VERSION ""

NS_ :

BS_:

BU_:

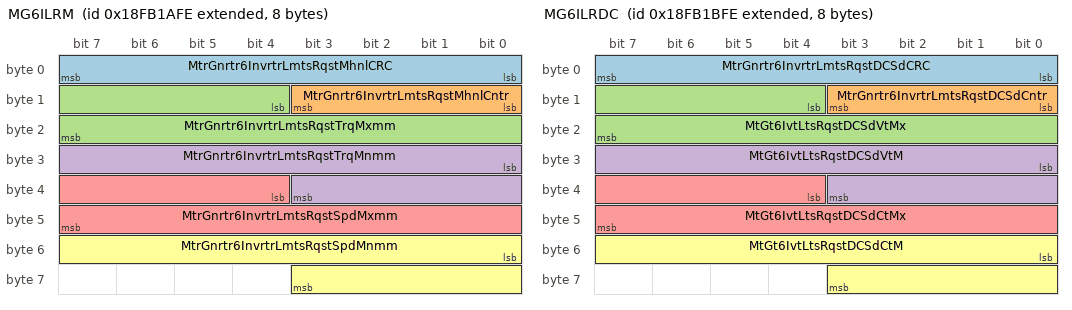
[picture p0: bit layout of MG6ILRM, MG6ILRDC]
BO_ 2566593278 MG6ILRM: 8 Vector__XXX
 SG_ MtrGnrtr6InvrtrLmtsRqstMhnlCRC : 0|8@1+ (1,0) [0|255] "count" Vector__XXX
 SG_ MtrGnrtr6InvrtrLmtsRqstMhnlCntr : 8|4@1+ (1,0) [0|15] "" Vector__XXX
 SG_ MtrGnrtr6InvrtrLmtsRqstTrqMxmm : 12|12@1+ (42370,-125) [-125|125.9375] "%" Vector__XXX
 SG_ MtrGnrtr6InvrtrLmtsRqstTrqMnmm : 24|12@1+ (42370,-125) [-125|125.9375] "%" Vector__XXX
 SG_ MtrGnrtr6InvrtrLmtsRqstSpdMxmm : 36|12@1+ (42370,-125) [-125|125.9375] "%" Vector__XXX
 SG_ MtrGnrtr6InvrtrLmtsRqstSpdMnmm : 48|12@1+ (42370,-125) [-125|125.9375] "%" Vector__XXX

BO_ 2566593534 MG6ILRDC: 8 Vector__XXX
 SG_ MtrGnrtr6InvrtrLmtsRqstDCSdCRC : 0|8@1+ (1,0) [0|255] "count" Vector__XXX
 SG_ MtrGnrtr6InvrtrLmtsRqstDCSdCntr : 8|4@1+ (1,0) [0|15] "" Vector__XXX
 SG_ MtGt6IvtLtsRqstDCSdVtMx : 12|12@1+ (42370,-125) [-125|125.9375] "%" Vector__XXX
 SG_ MtGt6IvtLtsRqstDCSdVtM : 24|12@1+ (42370,-125) [-125|125.9375] "%" Vector__XXX
 SG_ MtGt6IvtLtsRqstDCSdCtMx : 36|12@1+ (42370,-125) [-125|125.9375] "%" Vector__XXX
 SG_ MtGt6IvtLtsRqstDCSdCtM : 48|12@1+ (42370,-125) [-125|125.9375] "%" Vector__XXX

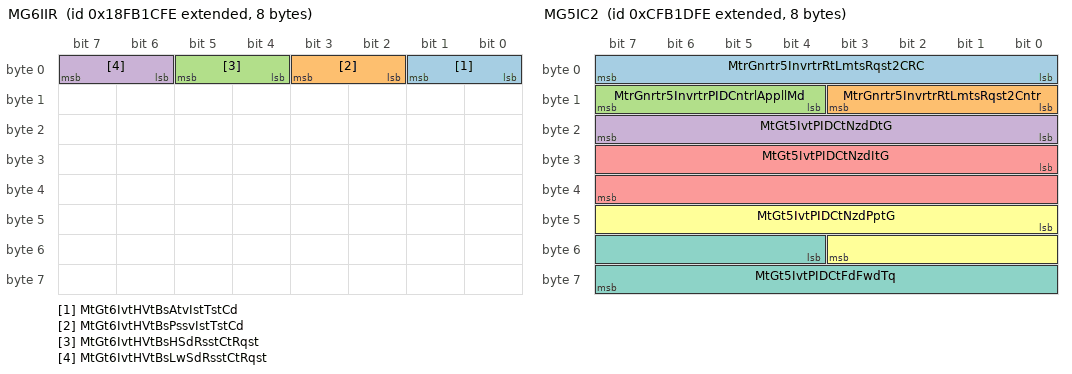
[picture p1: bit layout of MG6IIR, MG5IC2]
BO_ 2566593790 MG6IIR: 8 Vector__XXX
 SG_ MtGt6IvtHVtBsAtvIstTstCd : 0|2@1+ (1,0) [0|3] "" Vector__XXX
 SG_ MtGt6IvtHVtBsPssvIstTstCd : 2|2@1+ (1,0) [0|3] "" Vector__XXX
 SG_ MtGt6IvtHVtBsHSdRsstCtRqst : 4|2@1+ (1,0) [0|3] "" Vector__XXX
 SG_ MtGt6IvtHVtBsLwSdRsstCtRqst : 6|2@1+ (1,0) [0|3] "" Vector__XXX

BO_ 2365267454 MG5IC2: 8 Vector__XXX
 SG_ MtrGnrtr5InvrtrRtLmtsRqst2CRC : 0|8@1+ (1,0) [0|255] "count" Vector__XXX
 SG_ MtrGnrtr5InvrtrRtLmtsRqst2Cntr : 8|4@1+ (1,0) [0|15] "" Vector__XXX
 SG_ MtrGnrtr5InvrtrPIDCntrlAppllMd : 12|4@1+ (1,0) [0|15] "" Vector__XXX
 SG_ MtGt5IvtPIDCtNzdDtG : 16|8@1+ (11689,0) [0|7.8125] "%/(%/s)" Vector__XXX
 SG_ MtGt5IvtPIDCtNzdItG : 24|16@1+ (23377,0) [0|1003.984375] "%/(%/s)" Vector__XXX
 SG_ MtGt5IvtPIDCtNzdPptG : 40|12@1+ (42370,0) [0|250.9375] "%/%" Vector__XXX
 SG_ MtGt5IvtPIDCtFdFwdTq : 52|12@1+ (42370,-125) [-125|125.9375] "%" Vector__XXX

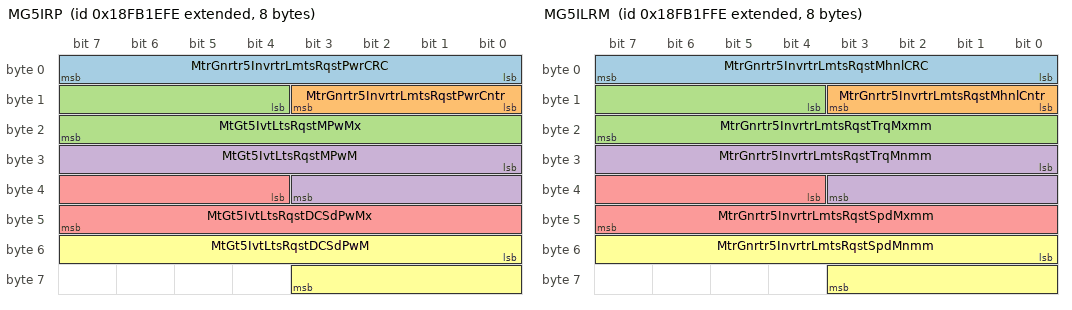
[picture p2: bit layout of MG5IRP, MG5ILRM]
BO_ 2566594302 MG5IRP: 8 Vector__XXX
 SG_ MtrGnrtr5InvrtrLmtsRqstPwrCRC : 0|8@1+ (1,0) [0|255] "count" Vector__XXX
 SG_ MtrGnrtr5InvrtrLmtsRqstPwrCntr : 8|4@1+ (1,0) [0|15] "" Vector__XXX
 SG_ MtGt5IvtLtsRqstMPwMx : 12|12@1+ (42370,-125) [-125|125.9375] "%" Vector__XXX
 SG_ MtGt5IvtLtsRqstMPwM : 24|12@1+ (42370,-125) [-125|125.9375] "%" Vector__XXX
 SG_ MtGt5IvtLtsRqstDCSdPwMx : 36|12@1+ (42370,-125) [-125|125.9375] "%" Vector__XXX
 SG_ MtGt5IvtLtsRqstDCSdPwM : 48|12@1+ (42370,-125) [-125|125.9375] "%" Vector__XXX

BO_ 2566594558 MG5ILRM: 8 Vector__XXX
 SG_ MtrGnrtr5InvrtrLmtsRqstMhnlCRC : 0|8@1+ (1,0) [0|255] "count" Vector__XXX
 SG_ MtrGnrtr5InvrtrLmtsRqstMhnlCntr : 8|4@1+ (1,0) [0|15] "" Vector__XXX
 SG_ MtrGnrtr5InvrtrLmtsRqstTrqMxmm : 12|12@1+ (42370,-125) [-125|125.9375] "%" Vector__XXX
 SG_ MtrGnrtr5InvrtrLmtsRqstTrqMnmm : 24|12@1+ (42370,-125) [-125|125.9375] "%" Vector__XXX
 SG_ MtrGnrtr5InvrtrLmtsRqstSpdMxmm : 36|12@1+ (42370,-125) [-125|125.9375] "%" Vector__XXX
 SG_ MtrGnrtr5InvrtrLmtsRqstSpdMnmm : 48|12@1+ (42370,-125) [-125|125.9375] "%" Vector__XXX

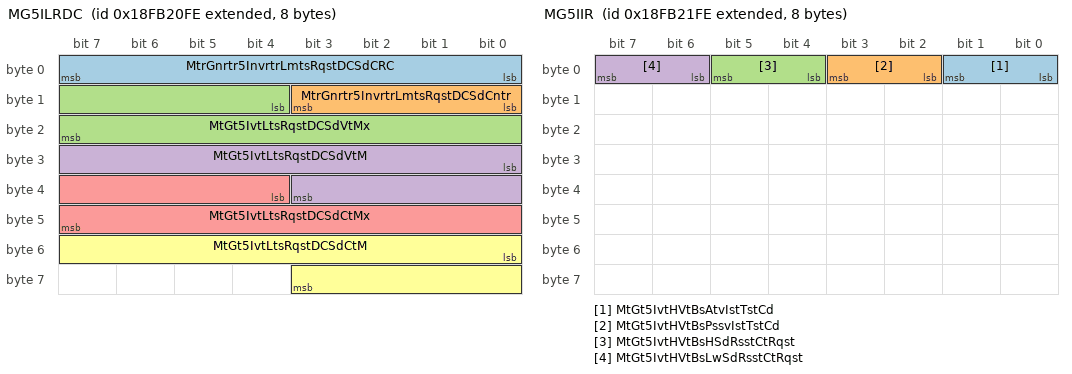
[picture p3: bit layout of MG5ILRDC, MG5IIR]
BO_ 2566594814 MG5ILRDC: 8 Vector__XXX
 SG_ MtrGnrtr5InvrtrLmtsRqstDCSdCRC : 0|8@1+ (1,0) [0|255] "count" Vector__XXX
 SG_ MtrGnrtr5InvrtrLmtsRqstDCSdCntr : 8|4@1+ (1,0) [0|15] "" Vector__XXX
 SG_ MtGt5IvtLtsRqstDCSdVtMx : 12|12@1+ (42370,-125) [-125|125.9375] "%" Vector__XXX
 SG_ MtGt5IvtLtsRqstDCSdVtM : 24|12@1+ (42370,-125) [-125|125.9375] "%" Vector__XXX
 SG_ MtGt5IvtLtsRqstDCSdCtMx : 36|12@1+ (42370,-125) [-125|125.9375] "%" Vector__XXX
 SG_ MtGt5IvtLtsRqstDCSdCtM : 48|12@1+ (42370,-125) [-125|125.9375] "%" Vector__XXX

BO_ 2566595070 MG5IIR: 8 Vector__XXX
 SG_ MtGt5IvtHVtBsAtvIstTstCd : 0|2@1+ (1,0) [0|3] "" Vector__XXX
 SG_ MtGt5IvtHVtBsPssvIstTstCd : 2|2@1+ (1,0) [0|3] "" Vector__XXX
 SG_ MtGt5IvtHVtBsHSdRsstCtRqst : 4|2@1+ (1,0) [0|3] "" Vector__XXX
 SG_ MtGt5IvtHVtBsLwSdRsstCtRqst : 6|2@1+ (1,0) [0|3] "" Vector__XXX

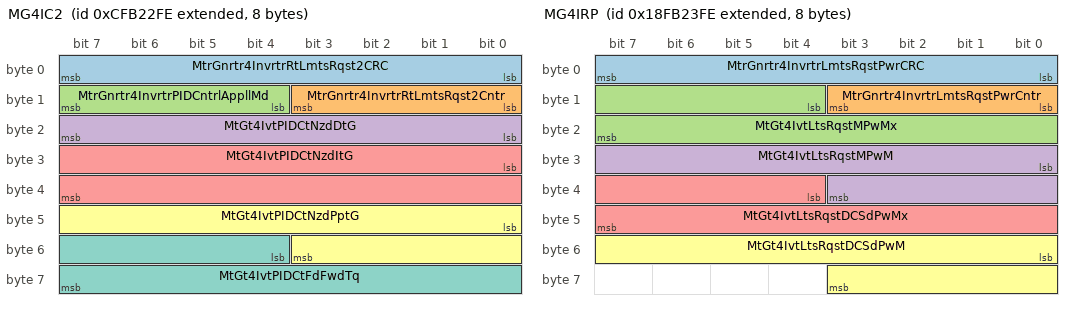
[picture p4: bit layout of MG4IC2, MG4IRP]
BO_ 2365268734 MG4IC2: 8 Vector__XXX
 SG_ MtrGnrtr4InvrtrRtLmtsRqst2CRC : 0|8@1+ (1,0) [0|255] "count" Vector__XXX
 SG_ MtrGnrtr4InvrtrRtLmtsRqst2Cntr : 8|4@1+ (1,0) [0|15] "" Vector__XXX
 SG_ MtrGnrtr4InvrtrPIDCntrlAppllMd : 12|4@1+ (1,0) [0|15] "" Vector__XXX
 SG_ MtGt4IvtPIDCtNzdDtG : 16|8@1+ (11689,0) [0|7.8125] "%/(%/s)" Vector__XXX
 SG_ MtGt4IvtPIDCtNzdItG : 24|16@1+ (23377,0) [0|1003.984375] "%/(%/s)" Vector__XXX
 SG_ MtGt4IvtPIDCtNzdPptG : 40|12@1+ (42370,0) [0|250.9375] "%/%" Vector__XXX
 SG_ MtGt4IvtPIDCtFdFwdTq : 52|12@1+ (42370,-125) [-125|125.9375] "%" Vector__XXX

BO_ 2566595582 MG4IRP: 8 Vector__XXX
 SG_ MtrGnrtr4InvrtrLmtsRqstPwrCRC : 0|8@1+ (1,0) [0|255] "count" Vector__XXX
 SG_ MtrGnrtr4InvrtrLmtsRqstPwrCntr : 8|4@1+ (1,0) [0|15] "" Vector__XXX
 SG_ MtGt4IvtLtsRqstMPwMx : 12|12@1+ (42370,-125) [-125|125.9375] "%" Vector__XXX
 SG_ MtGt4IvtLtsRqstMPwM : 24|12@1+ (42370,-125) [-125|125.9375] "%" Vector__XXX
 SG_ MtGt4IvtLtsRqstDCSdPwMx : 36|12@1+ (42370,-125) [-125|125.9375] "%" Vector__XXX
 SG_ MtGt4IvtLtsRqstDCSdPwM : 48|12@1+ (42370,-125) [-125|125.9375] "%" Vector__XXX

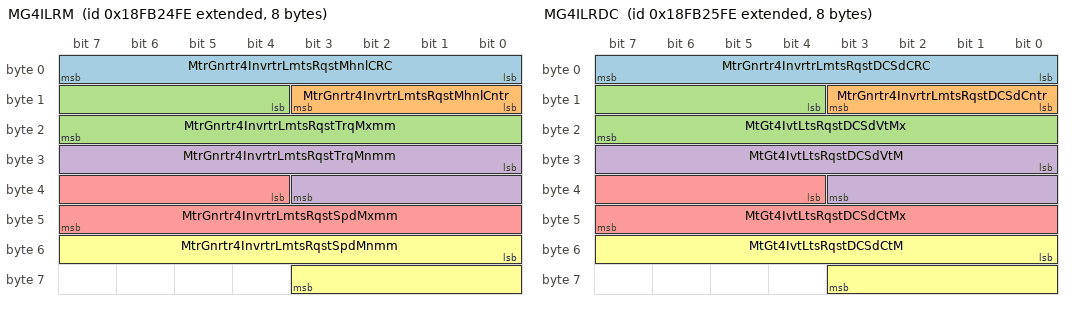
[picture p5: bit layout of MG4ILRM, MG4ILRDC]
BO_ 2566595838 MG4ILRM: 8 Vector__XXX
 SG_ MtrGnrtr4InvrtrLmtsRqstMhnlCRC : 0|8@1+ (1,0) [0|255] "count" Vector__XXX
 SG_ MtrGnrtr4InvrtrLmtsRqstMhnlCntr : 8|4@1+ (1,0) [0|15] "" Vector__XXX
 SG_ MtrGnrtr4InvrtrLmtsRqstTrqMxmm : 12|12@1+ (42370,-125) [-125|125.9375] "%" Vector__XXX
 SG_ MtrGnrtr4InvrtrLmtsRqstTrqMnmm : 24|12@1+ (42370,-125) [-125|125.9375] "%" Vector__XXX
 SG_ MtrGnrtr4InvrtrLmtsRqstSpdMxmm : 36|12@1+ (42370,-125) [-125|125.9375] "%" Vector__XXX
 SG_ MtrGnrtr4InvrtrLmtsRqstSpdMnmm : 48|12@1+ (42370,-125) [-125|125.9375] "%" Vector__XXX

BO_ 2566596094 MG4ILRDC: 8 Vector__XXX
 SG_ MtrGnrtr4InvrtrLmtsRqstDCSdCRC : 0|8@1+ (1,0) [0|255] "count" Vector__XXX
 SG_ MtrGnrtr4InvrtrLmtsRqstDCSdCntr : 8|4@1+ (1,0) [0|15] "" Vector__XXX
 SG_ MtGt4IvtLtsRqstDCSdVtMx : 12|12@1+ (42370,-125) [-125|125.9375] "%" Vector__XXX
 SG_ MtGt4IvtLtsRqstDCSdVtM : 24|12@1+ (42370,-125) [-125|125.9375] "%" Vector__XXX
 SG_ MtGt4IvtLtsRqstDCSdCtMx : 36|12@1+ (42370,-125) [-125|125.9375] "%" Vector__XXX
 SG_ MtGt4IvtLtsRqstDCSdCtM : 48|12@1+ (42370,-125) [-125|125.9375] "%" Vector__XXX

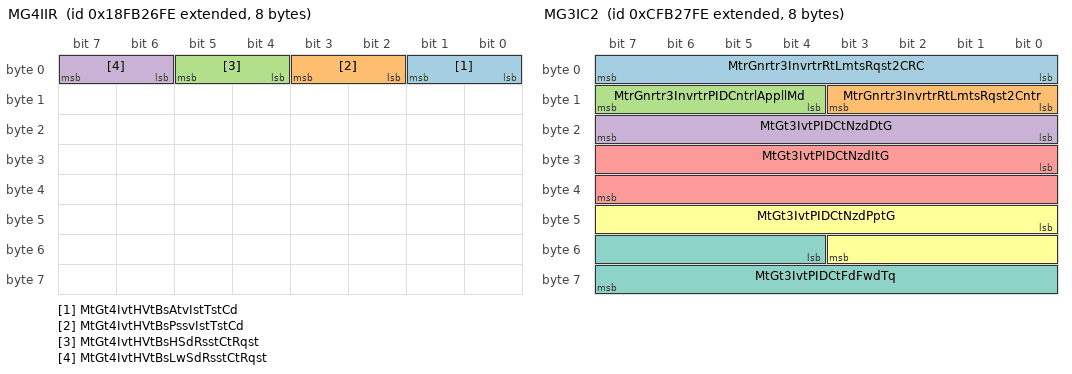
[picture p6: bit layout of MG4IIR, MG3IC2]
BO_ 2566596350 MG4IIR: 8 Vector__XXX
 SG_ MtGt4IvtHVtBsAtvIstTstCd : 0|2@1+ (1,0) [0|3] "" Vector__XXX
 SG_ MtGt4IvtHVtBsPssvIstTstCd : 2|2@1+ (1,0) [0|3] "" Vector__XXX
 SG_ MtGt4IvtHVtBsHSdRsstCtRqst : 4|2@1+ (1,0) [0|3] "" Vector__XXX
 SG_ MtGt4IvtHVtBsLwSdRsstCtRqst : 6|2@1+ (1,0) [0|3] "" Vector__XXX

BO_ 2365270014 MG3IC2: 8 Vector__XXX
 SG_ MtrGnrtr3InvrtrRtLmtsRqst2CRC : 0|8@1+ (1,0) [0|255] "count" Vector__XXX
 SG_ MtrGnrtr3InvrtrRtLmtsRqst2Cntr : 8|4@1+ (1,0) [0|15] "" Vector__XXX
 SG_ MtrGnrtr3InvrtrPIDCntrlAppllMd : 12|4@1+ (1,0) [0|15] "" Vector__XXX
 SG_ MtGt3IvtPIDCtNzdDtG : 16|8@1+ (11689,0) [0|7.8125] "%/(%/s)" Vector__XXX
 SG_ MtGt3IvtPIDCtNzdItG : 24|16@1+ (23377,0) [0|1003.984375] "%/(%/s)" Vector__XXX
 SG_ MtGt3IvtPIDCtNzdPptG : 40|12@1+ (42370,0) [0|250.9375] "%/%" Vector__XXX
 SG_ MtGt3IvtPIDCtFdFwdTq : 52|12@1+ (42370,-125) [-125|125.9375] "%" Vector__XXX

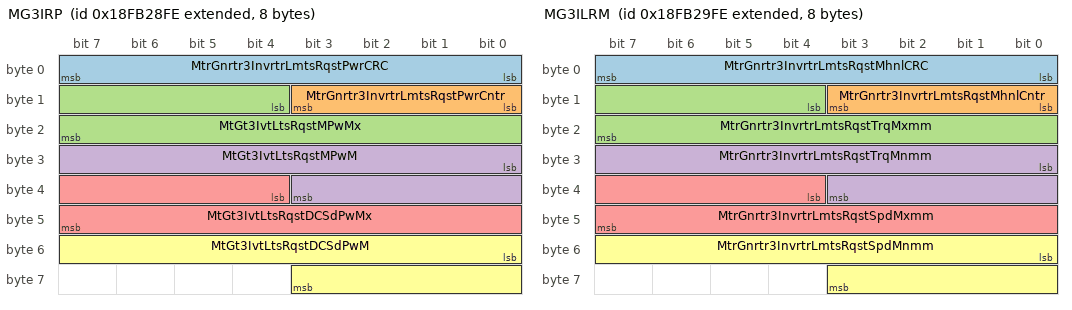
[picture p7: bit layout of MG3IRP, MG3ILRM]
BO_ 2566596862 MG3IRP: 8 Vector__XXX
 SG_ MtrGnrtr3InvrtrLmtsRqstPwrCRC : 0|8@1+ (1,0) [0|255] "count" Vector__XXX
 SG_ MtrGnrtr3InvrtrLmtsRqstPwrCntr : 8|4@1+ (1,0) [0|15] "" Vector__XXX
 SG_ MtGt3IvtLtsRqstMPwMx : 12|12@1+ (42370,-125) [-125|125.9375] "%" Vector__XXX
 SG_ MtGt3IvtLtsRqstMPwM : 24|12@1+ (42370,-125) [-125|125.9375] "%" Vector__XXX
 SG_ MtGt3IvtLtsRqstDCSdPwMx : 36|12@1+ (42370,-125) [-125|125.9375] "%" Vector__XXX
 SG_ MtGt3IvtLtsRqstDCSdPwM : 48|12@1+ (42370,-125) [-125|125.9375] "%" Vector__XXX

BO_ 2566597118 MG3ILRM: 8 Vector__XXX
 SG_ MtrGnrtr3InvrtrLmtsRqstMhnlCRC : 0|8@1+ (1,0) [0|255] "count" Vector__XXX
 SG_ MtrGnrtr3InvrtrLmtsRqstMhnlCntr : 8|4@1+ (1,0) [0|15] "" Vector__XXX
 SG_ MtrGnrtr3InvrtrLmtsRqstTrqMxmm : 12|12@1+ (42370,-125) [-125|125.9375] "%" Vector__XXX
 SG_ MtrGnrtr3InvrtrLmtsRqstTrqMnmm : 24|12@1+ (42370,-125) [-125|125.9375] "%" Vector__XXX
 SG_ MtrGnrtr3InvrtrLmtsRqstSpdMxmm : 36|12@1+ (42370,-125) [-125|125.9375] "%" Vector__XXX
 SG_ MtrGnrtr3InvrtrLmtsRqstSpdMnmm : 48|12@1+ (42370,-125) [-125|125.9375] "%" Vector__XXX

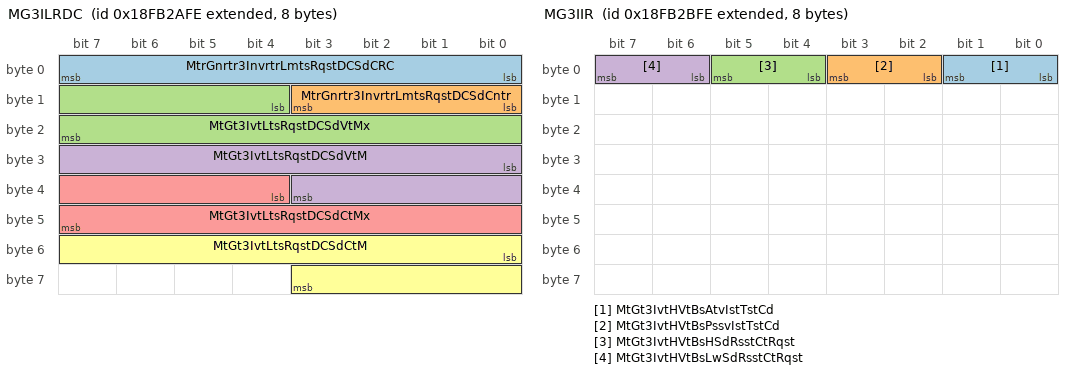
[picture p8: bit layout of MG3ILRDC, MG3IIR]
BO_ 2566597374 MG3ILRDC: 8 Vector__XXX
 SG_ MtrGnrtr3InvrtrLmtsRqstDCSdCRC : 0|8@1+ (1,0) [0|255] "count" Vector__XXX
 SG_ MtrGnrtr3InvrtrLmtsRqstDCSdCntr : 8|4@1+ (1,0) [0|15] "" Vector__XXX
 SG_ MtGt3IvtLtsRqstDCSdVtMx : 12|12@1+ (42370,-125) [-125|125.9375] "%" Vector__XXX
 SG_ MtGt3IvtLtsRqstDCSdVtM : 24|12@1+ (42370,-125) [-125|125.9375] "%" Vector__XXX
 SG_ MtGt3IvtLtsRqstDCSdCtMx : 36|12@1+ (42370,-125) [-125|125.9375] "%" Vector__XXX
 SG_ MtGt3IvtLtsRqstDCSdCtM : 48|12@1+ (42370,-125) [-125|125.9375] "%" Vector__XXX

BO_ 2566597630 MG3IIR: 8 Vector__XXX
 SG_ MtGt3IvtHVtBsAtvIstTstCd : 0|2@1+ (1,0) [0|3] "" Vector__XXX
 SG_ MtGt3IvtHVtBsPssvIstTstCd : 2|2@1+ (1,0) [0|3] "" Vector__XXX
 SG_ MtGt3IvtHVtBsHSdRsstCtRqst : 4|2@1+ (1,0) [0|3] "" Vector__XXX
 SG_ MtGt3IvtHVtBsLwSdRsstCtRqst : 6|2@1+ (1,0) [0|3] "" Vector__XXX

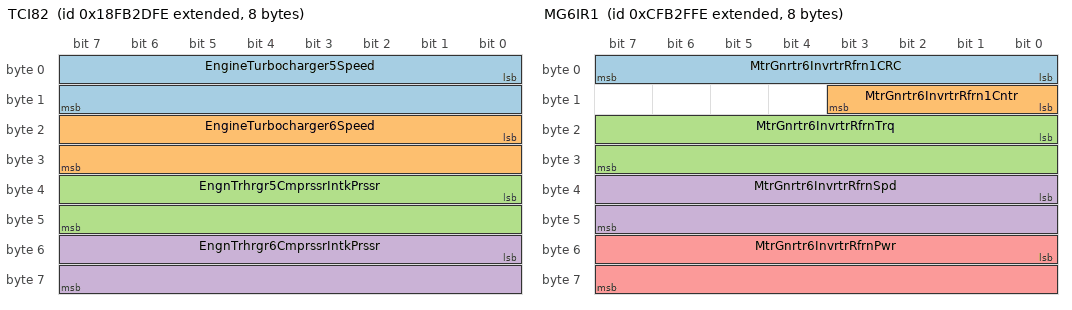
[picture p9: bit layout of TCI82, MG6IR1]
BO_ 2566598142 TCI82: 8 Vector__XXX
 SG_ EngineTurbocharger5Speed : 0|16@1+ (4,0) [0|257020] "rpm" Vector__XXX
 SG_ EngineTurbocharger6Speed : 16|16@1+ (4,0) [0|257020] "rpm" Vector__XXX
 SG_ EngnTrhrgr5CmprssrIntkPrssr : 32|16@1+ (0.0078125,-250) [-250|251.99] "kPa" Vector__XXX
 SG_ EngnTrhrgr6CmprssrIntkPrssr : 48|16@1+ (0.0078125,-250) [-250|251.99] "kPa" Vector__XXX

BO_ 2566598398 WINCH2: 8 Vector__XXX
 SG_ WinchLifetimeRevolutionCounter : 0|32@1+ (1,0) [0|4211081215] "count" Vector__XXX

BO_ 2365272062 MG6IR1: 8 Vector__XXX
 SG_ MtrGnrtr6InvrtrRfrn1CRC : 0|8@1+ (1,0) [0|255] "count" Vector__XXX
 SG_ MtrGnrtr6InvrtrRfrn1Cntr : 8|4@1+ (1,0) [0|15] "" Vector__XXX
 SG_ MtrGnrtr6InvrtrRfrnTrq : 16|16@1+ (0.5,0) [0|32127.5] "Nm" Vector__XXX
 SG_ MtrGnrtr6InvrtrRfrnSpd : 32|16@1+ (4,0) [0|257020] "rpm" Vector__XXX
 SG_ MtrGnrtr6InvrtrRfrnPwr : 48|16@1+ (0.0625,0) [0|4015.9375] "kW" Vector__XXX

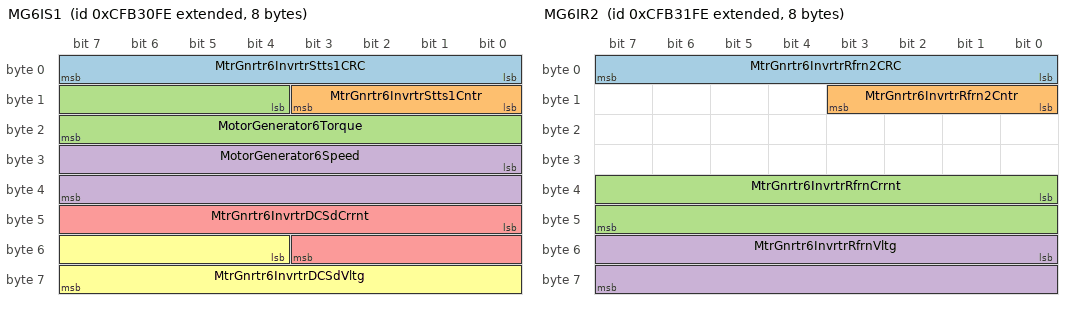
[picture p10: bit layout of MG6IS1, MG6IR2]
BO_ 2365272318 MG6IS1: 8 Vector__XXX
 SG_ MtrGnrtr6InvrtrStts1CRC : 0|8@1+ (1,0) [0|255] "count" Vector__XXX
 SG_ MtrGnrtr6InvrtrStts1Cntr : 8|4@1+ (1,0) [0|15] "" Vector__XXX
 SG_ MotorGenerator6Torque : 12|12@1+ (42370,-125) [-125|125.9375] "%" Vector__XXX
 SG_ MotorGenerator6Speed : 24|16@1+ (0.00390625,-125) [-125|125.99609375] "%" Vector__XXX
 SG_ MtrGnrtr6InvrtrDCSdCrrnt : 40|12@1+ (42370,-125) [-125|125.9375] "%" Vector__XXX
 SG_ MtrGnrtr6InvrtrDCSdVltg : 52|12@1+ (42370,-125) [-125|125.9375] "%" Vector__XXX

BO_ 2365272574 MG6IR2: 8 Vector__XXX
 SG_ MtrGnrtr6InvrtrRfrn2CRC : 0|8@1+ (1,0) [0|255] "count" Vector__XXX
 SG_ MtrGnrtr6InvrtrRfrn2Cntr : 8|4@1+ (1,0) [0|15] "" Vector__XXX
 SG_ MtrGnrtr6InvrtrRfrnCrrnt : 32|16@1+ (0.125,0) [0|8031.875] "A" Vector__XXX
 SG_ MtrGnrtr6InvrtrRfrnVltg : 48|16@1+ (0.125,0) [0|8031.875] "V" Vector__XXX

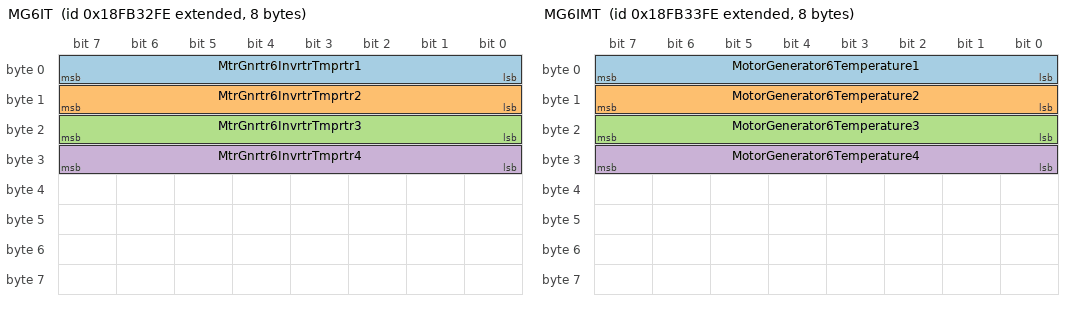
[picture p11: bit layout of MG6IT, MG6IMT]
BO_ 2566599422 MG6IT: 8 Vector__XXX
 SG_ MtrGnrtr6InvrtrTmprtr1 : 0|8@1+ (1,-40) [-40|210] "degC" Vector__XXX
 SG_ MtrGnrtr6InvrtrTmprtr2 : 8|8@1+ (1,-40) [-40|210] "degC" Vector__XXX
 SG_ MtrGnrtr6InvrtrTmprtr3 : 16|8@1+ (1,-40) [-40|210] "degC" Vector__XXX
 SG_ MtrGnrtr6InvrtrTmprtr4 : 24|8@1+ (1,-40) [-40|210] "degC" Vector__XXX

BO_ 2566599678 MG6IMT: 8 Vector__XXX
 SG_ MotorGenerator6Temperature1 : 0|8@1+ (1,-40) [-40|210] "degC" Vector__XXX
 SG_ MotorGenerator6Temperature2 : 8|8@1+ (1,-40) [-40|210] "degC" Vector__XXX
 SG_ MotorGenerator6Temperature3 : 16|8@1+ (1,-40) [-40|210] "degC" Vector__XXX
 SG_ MotorGenerator6Temperature4 : 24|8@1+ (1,-40) [-40|210] "degC" Vector__XXX

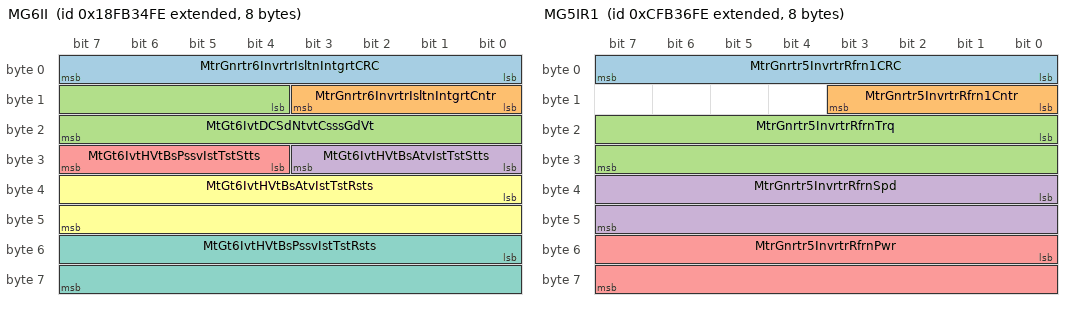
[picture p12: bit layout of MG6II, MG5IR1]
BO_ 2566599934 MG6II: 8 Vector__XXX
 SG_ MtrGnrtr6InvrtrIsltnIntgrtCRC : 0|8@1+ (1,0) [0|255] "count" Vector__XXX
 SG_ MtrGnrtr6InvrtrIsltnIntgrtCntr : 8|4@1+ (1,0) [0|15] "" Vector__XXX
 SG_ MtGt6IvtDCSdNtvtCsssGdVt : 12|12@1+ (42370,-125) [-125|125.9375] "%" Vector__XXX
 SG_ MtGt6IvtHVtBsAtvIstTstStts : 24|4@1+ (1,0) [0|15] "" Vector__XXX
 SG_ MtGt6IvtHVtBsPssvIstTstStts : 28|4@1+ (1,0) [0|15] "" Vector__XXX
 SG_ MtGt6IvtHVtBsAtvIstTstRsts : 32|16@1+ (0.1,0) [0|6425.5] "ohm/V" Vector__XXX
 SG_ MtGt6IvtHVtBsPssvIstTstRsts : 48|16@1+ (0.1,0) [0|6425.5] "ohm/V" Vector__XXX

BO_ 2566600190 MG6IAPL: 8 Vector__XXX
 SG_ MtGt6IvtPwLtddtUddRs : 0|2@1+ (1,0) [0|3] "" Vector__XXX
 SG_ MtGt6IvtPwLtddtDCSdCtMx : 2|2@1+ (1,0) [0|3] "" Vector__XXX
 SG_ MtGt6IvtPwLtddtDCSdCtM : 4|2@1+ (1,0) [0|3] "" Vector__XXX
 SG_ MtGt6IvtPwLtddtDCSdVtMx : 6|2@1+ (1,0) [0|3] "" Vector__XXX
 SG_ MtGt6IvtPwLtddtDCSdVtM : 8|2@1+ (1,0) [0|3] "" Vector__XXX
 SG_ MtGt6IvtPwLtddtMPwMx : 10|2@1+ (1,0) [0|3] "" Vector__XXX
 SG_ MtGt6IvtPwLtddtMPwM : 12|2@1+ (1,0) [0|3] "" Vector__XXX
 SG_ MtGt6IvtPwLtddtDCSdPwMx : 14|2@1+ (1,0) [0|3] "" Vector__XXX
 SG_ MtGt6IvtPwLtddtDCSdPwM : 16|2@1+ (1,0) [0|3] "" Vector__XXX
 SG_ MtrGnrtr6InvrtrPwrLmtddtTrqMxmm : 18|2@1+ (1,0) [0|3] "" Vector__XXX
 SG_ MtrGnrtr6InvrtrPwrLmtddtTrqMnmm : 20|2@1+ (1,0) [0|3] "" Vector__XXX
 SG_ MtrGnrtr6InvrtrPwrLmtddtSpdMxmm : 22|2@1+ (1,0) [0|3] "" Vector__XXX
 SG_ MtrGnrtr6InvrtrPwrLmtddtSpdMnmm : 24|2@1+ (1,0) [0|3] "" Vector__XXX
 SG_ MtGt6IvtPwLtddtIvtTpt : 28|2@1+ (1,0) [0|3] "" Vector__XXX
 SG_ MtGt6IvtPwLtddtMtTpt : 30|2@1+ (1,0) [0|3] "" Vector__XXX
 SG_ MtGt6IvtPwLtdDtFtCdt : 32|2@1+ (1,0) [0|3] "" Vector__XXX
 SG_ MtGt6IvtPwLtdDtAtvTqRtLt : 34|2@1+ (1,0) [0|3] "" Vector__XXX
 SG_ MtGt6IvtPwLtdDtAtvSpdRtLt : 36|2@1+ (1,0) [0|3] "" Vector__XXX
 SG_ MtGt6IvtTqLtdDtMCtsts : 38|2@1+ (1,0) [0|3] "" Vector__XXX

BO_ 2365273854 MG5IR1: 8 Vector__XXX
 SG_ MtrGnrtr5InvrtrRfrn1CRC : 0|8@1+ (1,0) [0|255] "count" Vector__XXX
 SG_ MtrGnrtr5InvrtrRfrn1Cntr : 8|4@1+ (1,0) [0|15] "" Vector__XXX
 SG_ MtrGnrtr5InvrtrRfrnTrq : 16|16@1+ (0.5,0) [0|32127.5] "Nm" Vector__XXX
 SG_ MtrGnrtr5InvrtrRfrnSpd : 32|16@1+ (4,0) [0|257020] "rpm" Vector__XXX
 SG_ MtrGnrtr5InvrtrRfrnPwr : 48|16@1+ (0.0625,0) [0|4015.9375] "kW" Vector__XXX

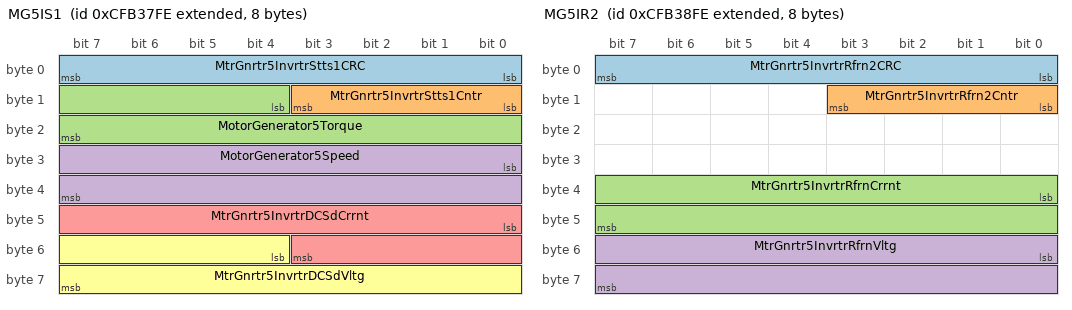
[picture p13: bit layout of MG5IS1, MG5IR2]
BO_ 2365274110 MG5IS1: 8 Vector__XXX
 SG_ MtrGnrtr5InvrtrStts1CRC : 0|8@1+ (1,0) [0|255] "count" Vector__XXX
 SG_ MtrGnrtr5InvrtrStts1Cntr : 8|4@1+ (1,0) [0|15] "" Vector__XXX
 SG_ MotorGenerator5Torque : 12|12@1+ (42370,-125) [-125|125.9375] "%" Vector__XXX
 SG_ MotorGenerator5Speed : 24|16@1+ (0.00390625,-125) [-125|125.99609375] "%" Vector__XXX
 SG_ MtrGnrtr5InvrtrDCSdCrrnt : 40|12@1+ (42370,-125) [-125|125.9375] "%" Vector__XXX
 SG_ MtrGnrtr5InvrtrDCSdVltg : 52|12@1+ (42370,-125) [-125|125.9375] "%" Vector__XXX

BO_ 2365274366 MG5IR2: 8 Vector__XXX
 SG_ MtrGnrtr5InvrtrRfrn2CRC : 0|8@1+ (1,0) [0|255] "count" Vector__XXX
 SG_ MtrGnrtr5InvrtrRfrn2Cntr : 8|4@1+ (1,0) [0|15] "" Vector__XXX
 SG_ MtrGnrtr5InvrtrRfrnCrrnt : 32|16@1+ (0.125,0) [0|8031.875] "A" Vector__XXX
 SG_ MtrGnrtr5InvrtrRfrnVltg : 48|16@1+ (0.125,0) [0|8031.875] "V" Vector__XXX

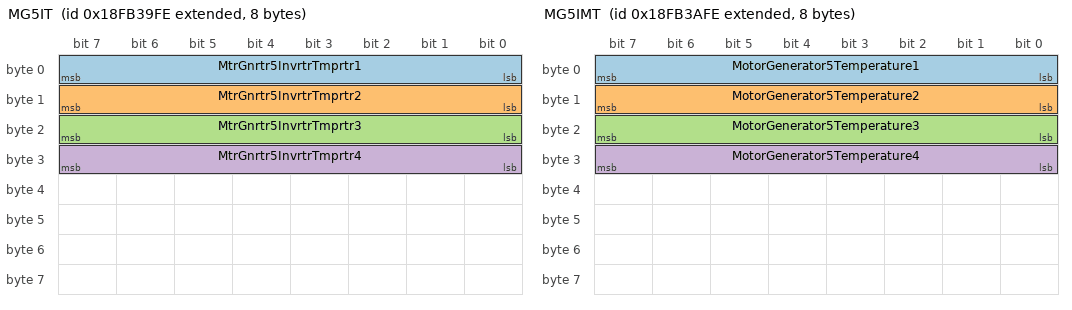
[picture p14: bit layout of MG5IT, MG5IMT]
BO_ 2566601214 MG5IT: 8 Vector__XXX
 SG_ MtrGnrtr5InvrtrTmprtr1 : 0|8@1+ (1,-40) [-40|210] "degC" Vector__XXX
 SG_ MtrGnrtr5InvrtrTmprtr2 : 8|8@1+ (1,-40) [-40|210] "degC" Vector__XXX
 SG_ MtrGnrtr5InvrtrTmprtr3 : 16|8@1+ (1,-40) [-40|210] "degC" Vector__XXX
 SG_ MtrGnrtr5InvrtrTmprtr4 : 24|8@1+ (1,-40) [-40|210] "degC" Vector__XXX

BO_ 2566601470 MG5IMT: 8 Vector__XXX
 SG_ MotorGenerator5Temperature1 : 0|8@1+ (1,-40) [-40|210] "degC" Vector__XXX
 SG_ MotorGenerator5Temperature2 : 8|8@1+ (1,-40) [-40|210] "degC" Vector__XXX
 SG_ MotorGenerator5Temperature3 : 16|8@1+ (1,-40) [-40|210] "degC" Vector__XXX
 SG_ MotorGenerator5Temperature4 : 24|8@1+ (1,-40) [-40|210] "degC" Vector__XXX

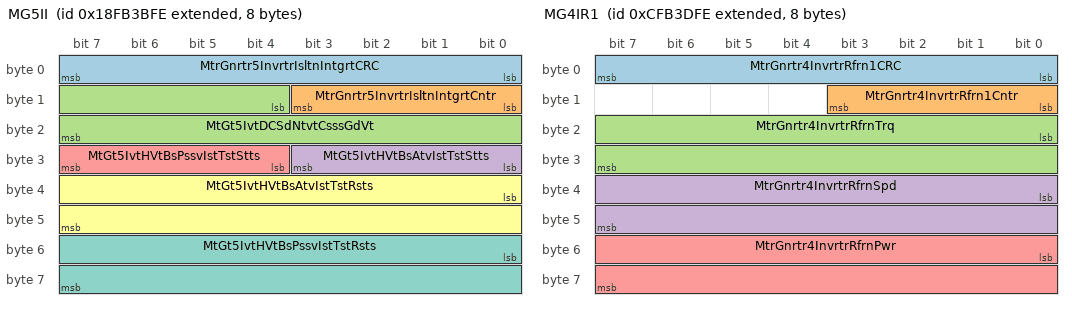
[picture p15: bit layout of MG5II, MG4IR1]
BO_ 2566601726 MG5II: 8 Vector__XXX
 SG_ MtrGnrtr5InvrtrIsltnIntgrtCRC : 0|8@1+ (1,0) [0|255] "count" Vector__XXX
 SG_ MtrGnrtr5InvrtrIsltnIntgrtCntr : 8|4@1+ (1,0) [0|15] "" Vector__XXX
 SG_ MtGt5IvtDCSdNtvtCsssGdVt : 12|12@1+ (42370,-125) [-125|125.9375] "%" Vector__XXX
 SG_ MtGt5IvtHVtBsAtvIstTstStts : 24|4@1+ (1,0) [0|15] "" Vector__XXX
 SG_ MtGt5IvtHVtBsPssvIstTstStts : 28|4@1+ (1,0) [0|15] "" Vector__XXX
 SG_ MtGt5IvtHVtBsAtvIstTstRsts : 32|16@1+ (0.1,0) [0|6425.5] "ohm/V" Vector__XXX
 SG_ MtGt5IvtHVtBsPssvIstTstRsts : 48|16@1+ (0.1,0) [0|6425.5] "ohm/V" Vector__XXX

BO_ 2566601982 MG5IAPL: 8 Vector__XXX
 SG_ MtGt5IvtPwLtddtUddRs : 0|2@1+ (1,0) [0|3] "" Vector__XXX
 SG_ MtGt5IvtPwLtddtDCSdCtMx : 2|2@1+ (1,0) [0|3] "" Vector__XXX
 SG_ MtGt5IvtPwLtddtDCSdCtM : 4|2@1+ (1,0) [0|3] "" Vector__XXX
 SG_ MtGt5IvtPwLtddtDCSdVtMx : 6|2@1+ (1,0) [0|3] "" Vector__XXX
 SG_ MtGt5IvtPwLtddtDCSdVtM : 8|2@1+ (1,0) [0|3] "" Vector__XXX
 SG_ MtGt5IvtPwLtddtMPwMx : 10|2@1+ (1,0) [0|3] "" Vector__XXX
 SG_ MtGt5IvtPwLtddtMPwM : 12|2@1+ (1,0) [0|3] "" Vector__XXX
 SG_ MtGt5IvtPwLtddtDCSdPwMx : 14|2@1+ (1,0) [0|3] "" Vector__XXX
 SG_ MtGt5IvtPwLtddtDCSdPwM : 16|2@1+ (1,0) [0|3] "" Vector__XXX
 SG_ MtrGnrtr5InvrtrPwrLmtddtTrqMxmm : 18|2@1+ (1,0) [0|3] "" Vector__XXX
 SG_ MtrGnrtr5InvrtrPwrLmtddtTrqMnmm : 20|2@1+ (1,0) [0|3] "" Vector__XXX
 SG_ MtrGnrtr5InvrtrPwrLmtddtSpdMxmm : 22|2@1+ (1,0) [0|3] "" Vector__XXX
 SG_ MtrGnrtr5InvrtrPwrLmtddtSpdMnmm : 24|2@1+ (1,0) [0|3] "" Vector__XXX
 SG_ MtGt5IvtPwLtddtIvtTpt : 28|2@1+ (1,0) [0|3] "" Vector__XXX
 SG_ MtGt5IvtPwLtddtMtTpt : 30|2@1+ (1,0) [0|3] "" Vector__XXX
 SG_ MtGt5IvtPwLtdDtFtCdt : 32|2@1+ (1,0) [0|3] "" Vector__XXX
 SG_ MtGt5IvtPwLtdDtAtvTqRtLt : 34|2@1+ (1,0) [0|3] "" Vector__XXX
 SG_ MtGt5IvtPwLtdDtAtvSpdRtLt : 36|2@1+ (1,0) [0|3] "" Vector__XXX
 SG_ MtGt5IvtTqLtdDtMCtsts : 38|2@1+ (1,0) [0|3] "" Vector__XXX

BO_ 2365275646 MG4IR1: 8 Vector__XXX
 SG_ MtrGnrtr4InvrtrRfrn1CRC : 0|8@1+ (1,0) [0|255] "count" Vector__XXX
 SG_ MtrGnrtr4InvrtrRfrn1Cntr : 8|4@1+ (1,0) [0|15] "" Vector__XXX
 SG_ MtrGnrtr4InvrtrRfrnTrq : 16|16@1+ (0.5,0) [0|32127.5] "Nm" Vector__XXX
 SG_ MtrGnrtr4InvrtrRfrnSpd : 32|16@1+ (4,0) [0|257020] "rpm" Vector__XXX
 SG_ MtrGnrtr4InvrtrRfrnPwr : 48|16@1+ (0.0625,0) [0|4015.9375] "kW" Vector__XXX

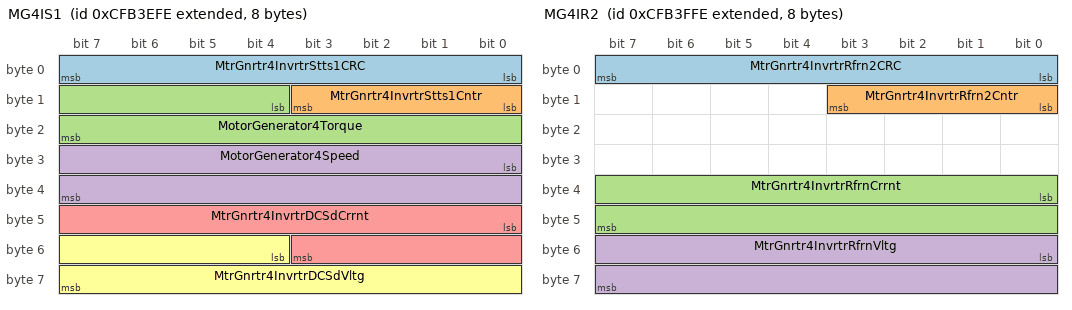
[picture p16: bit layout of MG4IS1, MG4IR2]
BO_ 2365275902 MG4IS1: 8 Vector__XXX
 SG_ MtrGnrtr4InvrtrStts1CRC : 0|8@1+ (1,0) [0|255] "count" Vector__XXX
 SG_ MtrGnrtr4InvrtrStts1Cntr : 8|4@1+ (1,0) [0|15] "" Vector__XXX
 SG_ MotorGenerator4Torque : 12|12@1+ (42370,-125) [-125|125.9375] "%" Vector__XXX
 SG_ MotorGenerator4Speed : 24|16@1+ (0.00390625,-125) [-125|125.99609375] "%" Vector__XXX
 SG_ MtrGnrtr4InvrtrDCSdCrrnt : 40|12@1+ (42370,-125) [-125|125.9375] "%" Vector__XXX
 SG_ MtrGnrtr4InvrtrDCSdVltg : 52|12@1+ (42370,-125) [-125|125.9375] "%" Vector__XXX

BO_ 2365276158 MG4IR2: 8 Vector__XXX
 SG_ MtrGnrtr4InvrtrRfrn2CRC : 0|8@1+ (1,0) [0|255] "count" Vector__XXX
 SG_ MtrGnrtr4InvrtrRfrn2Cntr : 8|4@1+ (1,0) [0|15] "" Vector__XXX
 SG_ MtrGnrtr4InvrtrRfrnCrrnt : 32|16@1+ (0.125,0) [0|8031.875] "A" Vector__XXX
 SG_ MtrGnrtr4InvrtrRfrnVltg : 48|16@1+ (0.125,0) [0|8031.875] "V" Vector__XXX

BO_ 2566603006 MG4IT: 8 Vector__XXX
 SG_ MtrGnrtr4InvrtrTmprtr1 : 0|8@1+ (1,-40) [-40|210] "degC" Vector__XXX
 SG_ MtrGnrtr4InvrtrTmprtr2 : 8|8@1+ (1,-40) [-40|210] "degC" Vector__XXX
 SG_ MtrGnrtr4InvrtrTmprtr3 : 16|8@1+ (1,-40) [-40|210] "degC" Vector__XXX
 SG_ MtrGnrtr4InvrtrTmprtr4 : 24|8@1+ (1,-40) [-40|210] "degC" Vector__XXX

BO_ 2566603262 MG4IMT: 8 Vector__XXX
 SG_ MotorGenerator4Temperature1 : 0|8@1+ (1,-40) [-40|210] "degC" Vector__XXX
 SG_ MotorGenerator4Temperature2 : 8|8@1+ (1,-40) [-40|210] "degC" Vector__XXX
 SG_ MotorGenerator4Temperature3 : 16|8@1+ (1,-40) [-40|210] "degC" Vector__XXX
 SG_ MotorGenerator4Temperature4 : 24|8@1+ (1,-40) [-40|210] "degC" Vector__XXX

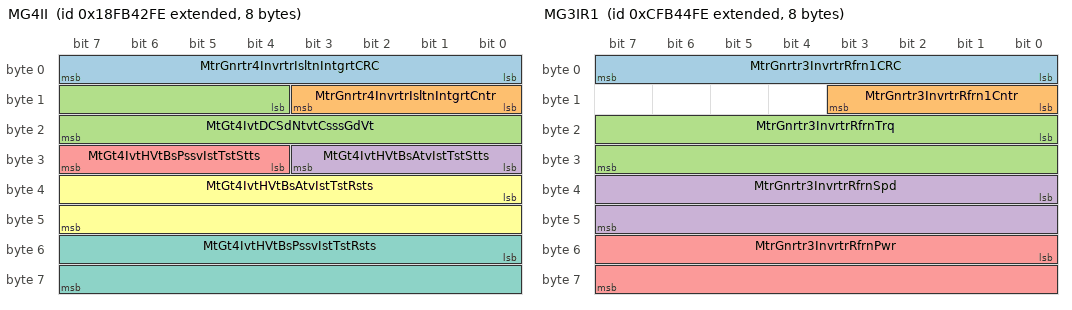
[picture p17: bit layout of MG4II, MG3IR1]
BO_ 2566603518 MG4II: 8 Vector__XXX
 SG_ MtrGnrtr4InvrtrIsltnIntgrtCRC : 0|8@1+ (1,0) [0|255] "count" Vector__XXX
 SG_ MtrGnrtr4InvrtrIsltnIntgrtCntr : 8|4@1+ (1,0) [0|15] "" Vector__XXX
 SG_ MtGt4IvtDCSdNtvtCsssGdVt : 12|12@1+ (42370,-125) [-125|125.9375] "%" Vector__XXX
 SG_ MtGt4IvtHVtBsAtvIstTstStts : 24|4@1+ (1,0) [0|15] "" Vector__XXX
 SG_ MtGt4IvtHVtBsPssvIstTstStts : 28|4@1+ (1,0) [0|15] "" Vector__XXX
 SG_ MtGt4IvtHVtBsAtvIstTstRsts : 32|16@1+ (0.1,0) [0|6425.5] "ohm/V" Vector__XXX
 SG_ MtGt4IvtHVtBsPssvIstTstRsts : 48|16@1+ (0.1,0) [0|6425.5] "ohm/V" Vector__XXX

BO_ 2566603774 MG4IAPL: 8 Vector__XXX
 SG_ MtGt4IvtPwLtddtUddRs : 0|2@1+ (1,0) [0|3] "" Vector__XXX
 SG_ MtGt4IvtPwLtddtDCSdCtMx : 2|2@1+ (1,0) [0|3] "" Vector__XXX
 SG_ MtGt4IvtPwLtddtDCSdCtM : 4|2@1+ (1,0) [0|3] "" Vector__XXX
 SG_ MtGt4IvtPwLtddtDCSdVtMx : 6|2@1+ (1,0) [0|3] "" Vector__XXX
 SG_ MtGt4IvtPwLtddtDCSdVtM : 8|2@1+ (1,0) [0|3] "" Vector__XXX
 SG_ MtGt4IvtPwLtddtMPwMx : 10|2@1+ (1,0) [0|3] "" Vector__XXX
 SG_ MtGt4IvtPwLtddtMPwM : 12|2@1+ (1,0) [0|3] "" Vector__XXX
 SG_ MtGt4IvtPwLtddtDCSdPwMx : 14|2@1+ (1,0) [0|3] "" Vector__XXX
 SG_ MtGt4IvtPwLtddtDCSdPwM : 16|2@1+ (1,0) [0|3] "" Vector__XXX
 SG_ MtrGnrtr4InvrtrPwrLmtddtTrqMxmm : 18|2@1+ (1,0) [0|3] "" Vector__XXX
 SG_ MtrGnrtr4InvrtrPwrLmtddtTrqMnmm : 20|2@1+ (1,0) [0|3] "" Vector__XXX
 SG_ MtrGnrtr4InvrtrPwrLmtddtSpdMxmm : 22|2@1+ (1,0) [0|3] "" Vector__XXX
 SG_ MtrGnrtr4InvrtrPwrLmtddtSpdMnmm : 24|2@1+ (1,0) [0|3] "" Vector__XXX
 SG_ MtGt4IvtPwLtddtIvtTpt : 28|2@1+ (1,0) [0|3] "" Vector__XXX
 SG_ MtGt4IvtPwLtddtMtTpt : 30|2@1+ (1,0) [0|3] "" Vector__XXX
 SG_ MtGt4IvtPwLtdDtFtCdt : 32|2@1+ (1,0) [0|3] "" Vector__XXX
 SG_ MtGt4IvtPwLtdDtAtvTqRtLt : 34|2@1+ (1,0) [0|3] "" Vector__XXX
 SG_ MtGt4IvtPwLtdDtAtvSpdRtLt : 36|2@1+ (1,0) [0|3] "" Vector__XXX
 SG_ MtGt4IvtTqLtdDtMCtsts : 38|2@1+ (1,0) [0|3] "" Vector__XXX

BO_ 2365277438 MG3IR1: 8 Vector__XXX
 SG_ MtrGnrtr3InvrtrRfrn1CRC : 0|8@1+ (1,0) [0|255] "count" Vector__XXX
 SG_ MtrGnrtr3InvrtrRfrn1Cntr : 8|4@1+ (1,0) [0|15] "" Vector__XXX
 SG_ MtrGnrtr3InvrtrRfrnTrq : 16|16@1+ (0.5,0) [0|32127.5] "Nm" Vector__XXX
 SG_ MtrGnrtr3InvrtrRfrnSpd : 32|16@1+ (4,0) [0|257020] "rpm" Vector__XXX
 SG_ MtrGnrtr3InvrtrRfrnPwr : 48|16@1+ (0.0625,0) [0|4015.9375] "kW" Vector__XXX

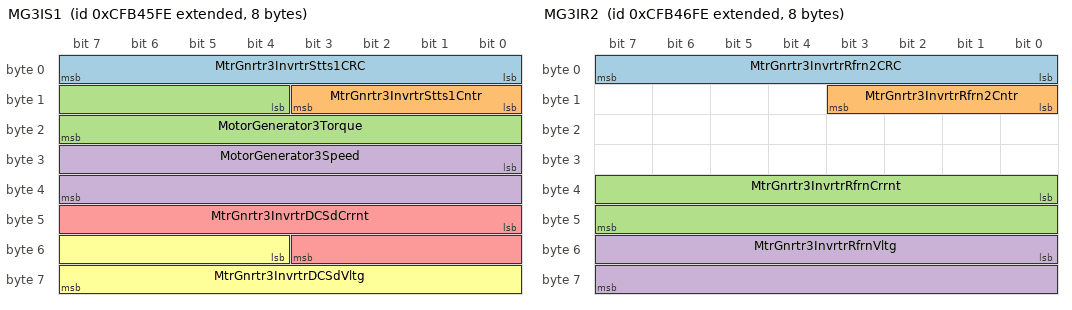
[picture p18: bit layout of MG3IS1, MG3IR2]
BO_ 2365277694 MG3IS1: 8 Vector__XXX
 SG_ MtrGnrtr3InvrtrStts1CRC : 0|8@1+ (1,0) [0|255] "count" Vector__XXX
 SG_ MtrGnrtr3InvrtrStts1Cntr : 8|4@1+ (1,0) [0|15] "" Vector__XXX
 SG_ MotorGenerator3Torque : 12|12@1+ (42370,-125) [-125|125.9375] "%" Vector__XXX
 SG_ MotorGenerator3Speed : 24|16@1+ (0.00390625,-125) [-125|125.99609375] "%" Vector__XXX
 SG_ MtrGnrtr3InvrtrDCSdCrrnt : 40|12@1+ (42370,-125) [-125|125.9375] "%" Vector__XXX
 SG_ MtrGnrtr3InvrtrDCSdVltg : 52|12@1+ (42370,-125) [-125|125.9375] "%" Vector__XXX

BO_ 2365277950 MG3IR2: 8 Vector__XXX
 SG_ MtrGnrtr3InvrtrRfrn2CRC : 0|8@1+ (1,0) [0|255] "count" Vector__XXX
 SG_ MtrGnrtr3InvrtrRfrn2Cntr : 8|4@1+ (1,0) [0|15] "" Vector__XXX
 SG_ MtrGnrtr3InvrtrRfrnCrrnt : 32|16@1+ (0.125,0) [0|8031.875] "A" Vector__XXX
 SG_ MtrGnrtr3InvrtrRfrnVltg : 48|16@1+ (0.125,0) [0|8031.875] "V" Vector__XXX

BO_ 2566604798 MG3IT: 8 Vector__XXX
 SG_ MtrGnrtr3InvrtrTmprtr1 : 0|8@1+ (1,-40) [-40|210] "degC" Vector__XXX
 SG_ MtrGnrtr3InvrtrTmprtr2 : 8|8@1+ (1,-40) [-40|210] "degC" Vector__XXX
 SG_ MtrGnrtr3InvrtrTmprtr3 : 16|8@1+ (1,-40) [-40|210] "degC" Vector__XXX
 SG_ MtrGnrtr3InvrtrTmprtr4 : 24|8@1+ (1,-40) [-40|210] "degC" Vector__XXX

BO_ 2566605054 MG3IMT: 8 Vector__XXX
 SG_ MotorGenerator3Temperature1 : 0|8@1+ (1,-40) [-40|210] "degC" Vector__XXX
 SG_ MotorGenerator3Temperature2 : 8|8@1+ (1,-40) [-40|210] "degC" Vector__XXX
 SG_ MotorGenerator3Temperature3 : 16|8@1+ (1,-40) [-40|210] "degC" Vector__XXX
 SG_ MotorGenerator3Temperature4 : 24|8@1+ (1,-40) [-40|210] "degC" Vector__XXX

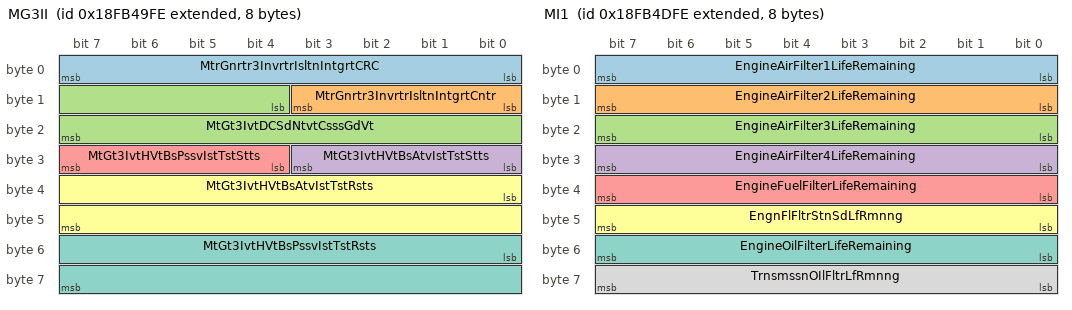
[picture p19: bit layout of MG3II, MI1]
BO_ 2566605310 MG3II: 8 Vector__XXX
 SG_ MtrGnrtr3InvrtrIsltnIntgrtCRC : 0|8@1+ (1,0) [0|255] "count" Vector__XXX
 SG_ MtrGnrtr3InvrtrIsltnIntgrtCntr : 8|4@1+ (1,0) [0|15] "" Vector__XXX
 SG_ MtGt3IvtDCSdNtvtCsssGdVt : 12|12@1+ (42370,-125) [-125|125.9375] "%" Vector__XXX
 SG_ MtGt3IvtHVtBsAtvIstTstStts : 24|4@1+ (1,0) [0|15] "" Vector__XXX
 SG_ MtGt3IvtHVtBsPssvIstTstStts : 28|4@1+ (1,0) [0|15] "" Vector__XXX
 SG_ MtGt3IvtHVtBsAtvIstTstRsts : 32|16@1+ (0.1,0) [0|6425.5] "ohm/V" Vector__XXX
 SG_ MtGt3IvtHVtBsPssvIstTstRsts : 48|16@1+ (0.1,0) [0|6425.5] "ohm/V" Vector__XXX

BO_ 2566605566 MG3IAPL: 8 Vector__XXX
 SG_ MtGt3IvtPwLtddtUddRs : 0|2@1+ (1,0) [0|3] "" Vector__XXX
 SG_ MtGt3IvtPwLtddtDCSdCtMx : 2|2@1+ (1,0) [0|3] "" Vector__XXX
 SG_ MtGt3IvtPwLtddtDCSdCtM : 4|2@1+ (1,0) [0|3] "" Vector__XXX
 SG_ MtGt3IvtPwLtddtDCSdVtMx : 6|2@1+ (1,0) [0|3] "" Vector__XXX
 SG_ MtGt3IvtPwLtddtDCSdVtM : 8|2@1+ (1,0) [0|3] "" Vector__XXX
 SG_ MtGt3IvtPwLtddtMPwMx : 10|2@1+ (1,0) [0|3] "" Vector__XXX
 SG_ MtGt3IvtPwLtddtMPwM : 12|2@1+ (1,0) [0|3] "" Vector__XXX
 SG_ MtGt3IvtPwLtddtDCSdPwMx : 14|2@1+ (1,0) [0|3] "" Vector__XXX
 SG_ MtGt3IvtPwLtddtDCSdPwM : 16|2@1+ (1,0) [0|3] "" Vector__XXX
 SG_ MtrGnrtr3InvrtrPwrLmtddtTrqMxmm : 18|2@1+ (1,0) [0|3] "" Vector__XXX
 SG_ MtrGnrtr3InvrtrPwrLmtddtTrqMnmm : 20|2@1+ (1,0) [0|3] "" Vector__XXX
 SG_ MtrGnrtr3InvrtrPwrLmtddtSpdMxmm : 22|2@1+ (1,0) [0|3] "" Vector__XXX
 SG_ MtrGnrtr3InvrtrPwrLmtddtSpdMnmm : 24|2@1+ (1,0) [0|3] "" Vector__XXX
 SG_ MtGt3IvtPwLtddtIvtTpt : 28|2@1+ (1,0) [0|3] "" Vector__XXX
 SG_ MtGt3IvtPwLtddtMtTpt : 30|2@1+ (1,0) [0|3] "" Vector__XXX
 SG_ MtGt3IvtPwLtdDtFtCdt : 32|2@1+ (1,0) [0|3] "" Vector__XXX
 SG_ MtGt3IvtPwLtdDtAtvTqRtLt : 34|2@1+ (1,0) [0|3] "" Vector__XXX
 SG_ MtGt3IvtPwLtdDtAtvSpdRtLt : 36|2@1+ (1,0) [0|3] "" Vector__XXX
 SG_ MtGt3IvtTqLtdDtMCtsts : 38|2@1+ (1,0) [0|3] "" Vector__XXX

BO_ 2566605822 ADSF: 8 Vector__XXX
 SG_ SAddssCtDvTSC1CtPpsP7 : 0|8@1+ (1,0) [0|255] "SA" Vector__XXX
 SG_ TSC1CntrlPrpsP7RdnssStts : 8|2@1+ (1,0) [0|3] "" Vector__XXX

BO_ 2566606078 CCSI2: 8 Vector__XXX
 SG_ CabHeaterPower : 0|16@1+ (2,0) [0|128510] "W" Vector__XXX

BO_ 2566606334 MI1: 8 Vector__XXX
 SG_ EngineAirFilter1LifeRemaining : 0|8@1+ (0.4,0) [0|100] "%" Vector__XXX
 SG_ EngineAirFilter2LifeRemaining : 8|8@1+ (0.4,0) [0|100] "%" Vector__XXX
 SG_ EngineAirFilter3LifeRemaining : 16|8@1+ (0.4,0) [0|100] "%" Vector__XXX
 SG_ EngineAirFilter4LifeRemaining : 24|8@1+ (0.4,0) [0|100] "%" Vector__XXX
 SG_ EngineFuelFilterLifeRemaining : 32|8@1+ (0.4,0) [0|100] "%" Vector__XXX
 SG_ EngnFlFltrStnSdLfRmnng : 40|8@1+ (0.4,0) [0|100] "%" Vector__XXX
 SG_ EngineOilFilterLifeRemaining : 48|8@1+ (0.4,0) [0|100] "%" Vector__XXX
 SG_ TrnsmssnOIlFltrLfRmnng : 56|8@1+ (0.4,0) [0|100] "%" Vector__XXX

BO_ 2499497726 HCI1: 8 Vector__XXX
 SG_ HoistLeverPosition : 0|16@1+ (0.005,-150) [-150|171.275] "%" Vector__XXX
 SG_ HoistLeverDetentPositionStatus : 16|2@1+ (1,0) [0|3] "" Vector__XXX

BO_ 2633715710 HVESP6HIST: 200 Vector__XXX
 SG_ HVESP6StateofHealth : 0|8@1+ (0.4,0) [0|100] "%" Vector__XXX
 SG_ HVESP6CnttrOpnUndrLdCnt : 8|16@1+ (1,0) [0|64255] "count" Vector__XXX
 SG_ HVESP6TotalEnergyThroughput : 24|32@1+ (100,0) [0|421108121500] "Watt-hour" Vector__XXX
 SG_ HVESP6TotalAccumulatedCharge : 56|32@1+ (100,0) [0|421108121500] "Ah" Vector__XXX
 SG_ HVESP6TotalLifetimeEnergyInput : 88|32@1+ (1,0) [0|4211081215] "kWh" Vector__XXX
 SG_ HVESP6TotalLifetimeEnergyOutput : 120|32@1+ (1,0) [0|4211081215] "kWh" Vector__XXX

BO_ 2566607102 HVESP6CFG: 200 Vector__XXX
 SG_ HVESP6NominalVoltage : 0|16@1+ (0.05,0) [0|3212.75] "V" Vector__XXX
 SG_ HVESP6RmmnddMnmmOprtngVltg : 16|16@1+ (0.05,0) [0|3212.75] "V" Vector__XXX
 SG_ HVESP6RmmnddMxmmOprtngVltg : 32|16@1+ (0.05,0) [0|3212.75] "V" Vector__XXX
 SG_ HVESP6RmmnddMnmmSttOfChrg : 48|16@1+ (0.0015625,0) [0|100.3984375] "%" Vector__XXX
 SG_ HVESP6RmmnddMxmmSttOfChrg : 64|16@1+ (0.0015625,0) [0|100.3984375] "%" Vector__XXX
 SG_ HVESP6RmmnddMxmmOprtngTmprtr : 80|16@1+ (0.03125,-273) [-273|1734.96875] "degC" Vector__XXX
 SG_ HVESP6RmmnddMnmmOprtngTmprtr : 96|16@1+ (0.03125,-273) [-273|1734.96875] "degC" Vector__XXX
 SG_ HVESP6CellMaximumVoltageLimit : 112|8@1+ (0.02044,0) [0|5.11] "V" Vector__XXX
 SG_ HVESP6CellMinimumVoltageLimit : 120|8@1+ (0.02044,0) [0|5.11] "V" Vector__XXX

BO_ 2633716222 HVESP5HIST: 200 Vector__XXX
 SG_ HVESP5StateofHealth : 0|8@1+ (0.4,0) [0|100] "%" Vector__XXX
 SG_ HVESP5CnttrOpnUndrLdCnt : 8|16@1+ (1,0) [0|64255] "count" Vector__XXX
 SG_ HVESP5TotalEnergyThroughput : 24|32@1+ (100,0) [0|421108121500] "Watt-hour" Vector__XXX
 SG_ HVESP5TotalAccumulatedCharge : 56|32@1+ (100,0) [0|421108121500] "Ah" Vector__XXX
 SG_ HVESP5TotalLifetimeEnergyInput : 88|32@1+ (1,0) [0|4211081215] "kWh" Vector__XXX
 SG_ HVESP5TotalLifetimeEnergyOutput : 120|32@1+ (1,0) [0|4211081215] "kWh" Vector__XXX

BO_ 2566607614 HVESP5CFG: 200 Vector__XXX
 SG_ HVESP5NominalVoltage : 0|16@1+ (0.05,0) [0|3212.75] "V" Vector__XXX
 SG_ HVESP5RmmnddMnmmOprtngVltg : 16|16@1+ (0.05,0) [0|3212.75] "V" Vector__XXX
 SG_ HVESP5RmmnddMxmmOprtngVltg : 32|16@1+ (0.05,0) [0|3212.75] "V" Vector__XXX
 SG_ HVESP5RmmnddMnmmSttOfChrg : 48|16@1+ (0.0015625,0) [0|100.3984375] "%" Vector__XXX
 SG_ HVESP5RmmnddMxmmSttOfChrg : 64|16@1+ (0.0015625,0) [0|100.3984375] "%" Vector__XXX
 SG_ HVESP5RmmnddMxmmOprtngTmprtr : 80|16@1+ (0.03125,-273) [-273|1734.96875] "degC" Vector__XXX
 SG_ HVESP5RmmnddMnmmOprtngTmprtr : 96|16@1+ (0.03125,-273) [-273|1734.96875] "degC" Vector__XXX
 SG_ HVESP5CellMaximumVoltageLimit : 112|8@1+ (0.02044,0) [0|5.11] "V" Vector__XXX
 SG_ HVESP5CellMinimumVoltageLimit : 120|8@1+ (0.02044,0) [0|5.11] "V" Vector__XXX

BO_ 2633716734 HVESP4HIST: 200 Vector__XXX
 SG_ HVESP4StateofHealth : 0|8@1+ (0.4,0) [0|100] "%" Vector__XXX
 SG_ HVESP4CnttrOpnUndrLdCnt : 8|16@1+ (1,0) [0|64255] "count" Vector__XXX
 SG_ HVESP4TotalEnergyThroughput : 24|32@1+ (100,0) [0|421108121500] "Watt-hour" Vector__XXX
 SG_ HVESP4TotalAccumulatedCharge : 56|32@1+ (100,0) [0|421108121500] "Ah" Vector__XXX
 SG_ HVESP4TotalLifetimeEnergyInput : 88|32@1+ (1,0) [0|4211081215] "kWh" Vector__XXX
 SG_ HVESP4TotalLifetimeEnergyOutput : 120|32@1+ (1,0) [0|4211081215] "kWh" Vector__XXX

BO_ 2566608126 HVESP4CFG: 200 Vector__XXX
 SG_ HVESP4NominalVoltage : 0|16@1+ (0.05,0) [0|3212.75] "V" Vector__XXX
 SG_ HVESP4RmmnddMnmmOprtngVltg : 16|16@1+ (0.05,0) [0|3212.75] "V" Vector__XXX
 SG_ HVESP4RmmnddMxmmOprtngVltg : 32|16@1+ (0.05,0) [0|3212.75] "V" Vector__XXX
 SG_ HVESP4RmmnddMnmmSttOfChrg : 48|16@1+ (0.0015625,0) [0|100.3984375] "%" Vector__XXX
 SG_ HVESP4RmmnddMxmmSttOfChrg : 64|16@1+ (0.0015625,0) [0|100.3984375] "%" Vector__XXX
 SG_ HVESP4RmmnddMxmmOprtngTmprtr : 80|16@1+ (0.03125,-273) [-273|1734.96875] "degC" Vector__XXX
 SG_ HVESP4RmmnddMnmmOprtngTmprtr : 96|16@1+ (0.03125,-273) [-273|1734.96875] "degC" Vector__XXX
 SG_ HVESP4CellMaximumVoltageLimit : 112|8@1+ (0.02044,0) [0|5.11] "V" Vector__XXX
 SG_ HVESP4CellMinimumVoltageLimit : 120|8@1+ (0.02044,0) [0|5.11] "V" Vector__XXX

BO_ 2633717246 HVESP3HIST: 200 Vector__XXX
 SG_ HVESP3StateofHealth : 0|8@1+ (0.4,0) [0|100] "%" Vector__XXX
 SG_ HVESP3CnttrOpnUndrLdCnt : 8|16@1+ (1,0) [0|64255] "count" Vector__XXX
 SG_ HVESP3TotalEnergyThroughput : 24|32@1+ (100,0) [0|421108121500] "Watt-hour" Vector__XXX
 SG_ HVESP3TotalAccumulatedCharge : 56|32@1+ (100,0) [0|421108121500] "Ah" Vector__XXX
 SG_ HVESP3TotalLifetimeEnergyInput : 88|32@1+ (1,0) [0|4211081215] "kWh" Vector__XXX
 SG_ HVESP3TotalLifetimeEnergyOutput : 120|32@1+ (1,0) [0|4211081215] "kWh" Vector__XXX

BO_ 2566608638 HVESP3CFG: 200 Vector__XXX
 SG_ HVESP3NominalVoltage : 0|16@1+ (0.05,0) [0|3212.75] "V" Vector__XXX
 SG_ HVESP3RmmnddMnmmOprtngVltg : 16|16@1+ (0.05,0) [0|3212.75] "V" Vector__XXX
 SG_ HVESP3RmmnddMxmmOprtngVltg : 32|16@1+ (0.05,0) [0|3212.75] "V" Vector__XXX
 SG_ HVESP3RmmnddMnmmSttOfChrg : 48|16@1+ (0.0015625,0) [0|100.3984375] "%" Vector__XXX
 SG_ HVESP3RmmnddMxmmSttOfChrg : 64|16@1+ (0.0015625,0) [0|100.3984375] "%" Vector__XXX
 SG_ HVESP3RmmnddMxmmOprtngTmprtr : 80|16@1+ (0.03125,-273) [-273|1734.96875] "degC" Vector__XXX
 SG_ HVESP3RmmnddMnmmOprtngTmprtr : 96|16@1+ (0.03125,-273) [-273|1734.96875] "degC" Vector__XXX
 SG_ HVESP3CellMaximumVoltageLimit : 112|8@1+ (0.02044,0) [0|5.11] "V" Vector__XXX
 SG_ HVESP3CellMinimumVoltageLimit : 120|8@1+ (0.02044,0) [0|5.11] "V" Vector__XXX

BO_ 2633717758 HVESP2HIST: 200 Vector__XXX
 SG_ HVESP2StateofHealth : 0|8@1+ (0.4,0) [0|100] "%" Vector__XXX
 SG_ HVESP2CnttrOpnUndrLdCnt : 8|16@1+ (1,0) [0|64255] "count" Vector__XXX
 SG_ HVESP2TotalEnergyThroughput : 24|32@1+ (100,0) [0|421108121500] "Watt-hour" Vector__XXX
 SG_ HVESP2TotalAccumulatedCharge : 56|32@1+ (100,0) [0|421108121500] "Ah" Vector__XXX
 SG_ HVESP2TotalLifetimeEnergyInput : 88|32@1+ (1,0) [0|4211081215] "kWh" Vector__XXX
 SG_ HVESP2TotalLifetimeEnergyOutput : 120|32@1+ (1,0) [0|4211081215] "kWh" Vector__XXX

BO_ 2566609150 HVESP2CFG: 200 Vector__XXX
 SG_ HVESP2NominalVoltage : 0|16@1+ (0.05,0) [0|3212.75] "V" Vector__XXX
 SG_ HVESP2RmmnddMnmmOprtngVltg : 16|16@1+ (0.05,0) [0|3212.75] "V" Vector__XXX
 SG_ HVESP2RmmnddMxmmOprtngVltg : 32|16@1+ (0.05,0) [0|3212.75] "V" Vector__XXX
 SG_ HVESP2RmmnddMnmmSttOfChrg : 48|16@1+ (0.0015625,0) [0|100.3984375] "%" Vector__XXX
 SG_ HVESP2RmmnddMxmmSttOfChrg : 64|16@1+ (0.0015625,0) [0|100.3984375] "%" Vector__XXX
 SG_ HVESP2RmmnddMxmmOprtngTmprtr : 80|16@1+ (0.03125,-273) [-273|1734.96875] "degC" Vector__XXX
 SG_ HVESP2RmmnddMnmmOprtngTmprtr : 96|16@1+ (0.03125,-273) [-273|1734.96875] "degC" Vector__XXX
 SG_ HVESP2CellMaximumVoltageLimit : 112|8@1+ (0.02044,0) [0|5.11] "V" Vector__XXX
 SG_ HVESP2CellMinimumVoltageLimit : 120|8@1+ (0.02044,0) [0|5.11] "V" Vector__XXX

BO_ 2633718270 HVESP1HIST: 200 Vector__XXX
 SG_ HVESP1StateofHealth : 0|8@1+ (0.4,0) [0|100] "%" Vector__XXX
 SG_ HVESP1CnttrOpnUndrLdCnt : 8|16@1+ (1,0) [0|64255] "count" Vector__XXX
 SG_ HVESP1TotalEnergyThroughput : 24|32@1+ (100,0) [0|421108121500] "Watt-hour" Vector__XXX
 SG_ HVESP1TotalAccumulatedCharge : 56|32@1+ (100,0) [0|421108121500] "Ah" Vector__XXX
 SG_ HVESP1TotalLifetimeEnergyInput : 88|32@1+ (1,0) [0|4211081215] "kWh" Vector__XXX
 SG_ HVESP1TotalLifetimeEnergyOutput : 120|32@1+ (1,0) [0|4211081215] "kWh" Vector__XXX

BO_ 2566609662 HVESP1CFG: 200 Vector__XXX
 SG_ HVESP1NominalVoltage : 0|16@1+ (0.05,0) [0|3212.75] "V" Vector__XXX
 SG_ HVESP1RmmnddMnmmOprtngVltg : 16|16@1+ (0.05,0) [0|3212.75] "V" Vector__XXX
 SG_ HVESP1RmmnddMxmmOprtngVltg : 32|16@1+ (0.05,0) [0|3212.75] "V" Vector__XXX
 SG_ HVESP1RmmnddMnmmSttOfChrg : 48|16@1+ (0.0015625,0) [0|100.3984375] "%" Vector__XXX
 SG_ HVESP1RmmnddMxmmSttOfChrg : 64|16@1+ (0.0015625,0) [0|100.3984375] "%" Vector__XXX
 SG_ HVESP1RmmnddMxmmOprtngTmprtr : 80|16@1+ (0.03125,-273) [-273|1734.96875] "degC" Vector__XXX
 SG_ HVESP1RmmnddMnmmOprtngTmprtr : 96|16@1+ (0.03125,-273) [-273|1734.96875] "degC" Vector__XXX
 SG_ HVESP1CellMaximumVoltageLimit : 112|8@1+ (0.02044,0) [0|5.11] "V" Vector__XXX
 SG_ HVESP1CellMinimumVoltageLimit : 120|8@1+ (0.02044,0) [0|5.11] "V" Vector__XXX

BO_ 2633718782 VFSSM1DET: 24 Vector__XXX
 SG_ VFSSMdl1Dttr1DttrTp : 0|4@1+ (1,0) [0|15] "" Vector__XXX
 SG_ VFSSMdl1Dttr1DttrDtSLOT : 4|4@1+ (1,0) [0|15] "" Vector__XXX
 SG_ VFSSMdl1Dttr2DttrTp : 24|4@1+ (1,0) [0|15] "" Vector__XXX
 SG_ VFSSMdl1Dttr2DttrDtSLOT : 28|4@1+ (1,0) [0|15] "" Vector__XXX
 SG_ VFSSMdl1Dttr3DttrTp : 48|4@1+ (1,0) [0|15] "" Vector__XXX
 SG_ VFSSMdl1Dttr3DttrDtSLOT : 52|4@1+ (1,0) [0|15] "" Vector__XXX
 SG_ VFSSMdl1Dttr4DttrTp : 72|4@1+ (1,0) [0|15] "" Vector__XXX
 SG_ VFSSMdl1Dttr4DttrDtSLOT : 76|4@1+ (1,0) [0|15] "" Vector__XXX
 SG_ VFSSMdl1Dttr5DttrTp : 96|4@1+ (1,0) [0|15] "" Vector__XXX
 SG_ VFSSMdl1Dttr5DttrDtSLOT : 100|4@1+ (1,0) [0|15] "" Vector__XXX
 SG_ VFSSMdl1Dttr6DttrTp : 120|4@1+ (1,0) [0|15] "" Vector__XXX
 SG_ VFSSMdl1Dttr6DttrDtSLOT : 124|4@1+ (1,0) [0|15] "" Vector__XXX
 SG_ VFSSMdl1Dttr7DttrTp : 144|4@1+ (1,0) [0|15] "" Vector__XXX
 SG_ VFSSMdl1Dttr7DttrDtSLOT : 148|4@1+ (1,0) [0|15] "" Vector__XXX
 SG_ VFSSMdl1Dttr8DttrTp : 168|4@1+ (1,0) [0|15] "" Vector__XXX
 SG_ VFSSMdl1Dttr8DttrDtSLOT : 172|4@1+ (1,0) [0|15] "" Vector__XXX

BO_ 2633719038 VFSSM2DET: 24 Vector__XXX
 SG_ VFSSMdl2Dttr1DttrTp : 0|4@1+ (1,0) [0|15] "" Vector__XXX
 SG_ VFSSMdl2Dttr1DttrDtSLOT : 4|4@1+ (1,0) [0|15] "" Vector__XXX
 SG_ VFSSMdl2Dttr2DttrTp : 24|4@1+ (1,0) [0|15] "" Vector__XXX
 SG_ VFSSMdl2Dttr2DttrDtSLOT : 28|4@1+ (1,0) [0|15] "" Vector__XXX
 SG_ VFSSMdl2Dttr3DttrTp : 48|4@1+ (1,0) [0|15] "" Vector__XXX
 SG_ VFSSMdl2Dttr3DttrDtSLOT : 52|4@1+ (1,0) [0|15] "" Vector__XXX
 SG_ VFSSMdl2Dttr4DttrTp : 72|4@1+ (1,0) [0|15] "" Vector__XXX
 SG_ VFSSMdl2Dttr4DttrDtSLOT : 76|4@1+ (1,0) [0|15] "" Vector__XXX
 SG_ VFSSMdl2Dttr5DttrTp : 96|4@1+ (1,0) [0|15] "" Vector__XXX
 SG_ VFSSMdl2Dttr5DttrDtSLOT : 100|4@1+ (1,0) [0|15] "" Vector__XXX
 SG_ VFSSMdl2Dttr6DttrTp : 120|4@1+ (1,0) [0|15] "" Vector__XXX
 SG_ VFSSMdl2Dttr6DttrDtSLOT : 124|4@1+ (1,0) [0|15] "" Vector__XXX
 SG_ VFSSMdl2Dttr7DttrTp : 144|4@1+ (1,0) [0|15] "" Vector__XXX
 SG_ VFSSMdl2Dttr7DttrDtSLOT : 148|4@1+ (1,0) [0|15] "" Vector__XXX
 SG_ VFSSMdl2Dttr8DttrTp : 168|4@1+ (1,0) [0|15] "" Vector__XXX
 SG_ VFSSMdl2Dttr8DttrDtSLOT : 172|4@1+ (1,0) [0|15] "" Vector__XXX

CM_ BO_ 2566593278 "Motor/Generator 6 Inverter Limits Request Mechanical";
CM_ SG_ 2566593278 MtrGnrtr6InvrtrLmtsRqstMhnlCRC "Motor/Generator 6 Inverter Limits Request Mechanical CRC: The CRC is defined as follows:• Length: 8 bits• Polynomial: x^8+x^5+x^3+x^2+x+1• Initial Value: FFh• Input Data Reflection: Not reflected• Result Data Reflection: Not reflected• XOR value: FFh...";
CM_ SG_ 2566593278 MtrGnrtr6InvrtrLmtsRqstMhnlCntr "Motor/Generator 6 Inverter Limits Request Mechanical Counter: The message counter is used to detect situations where the transmitting ECU malfunction repeats the same frame all the time. The receiver of the information may use the counter parameter t...";
CM_ SG_ 2566593278 MtrGnrtr6InvrtrLmtsRqstTrqMxmm "Motor/Generator 6 Inverter Limits Request Torque Maximum: This requests a maximum torque the inverter should command for this device.Refer to SPN 12175 [Reference Torque] to convert % to Nm. Request a value of FBFh to instruct the inverter to use its...";
CM_ SG_ 2566593278 MtrGnrtr6InvrtrLmtsRqstTrqMnmm "Motor/Generator 6 Inverter Limits Request Torque Minimum: This requests a minimum torque the inverter should command for this device.Refer to SPN 12175 [Reference Torque] to convert % to Nm. Request a value of FBFh to instruct the inverter to use its...";
CM_ SG_ 2566593278 MtrGnrtr6InvrtrLmtsRqstSpdMxmm "Motor/Generator 6 Inverter Limits Request Speed Maximum: This is a request to the inverter to set a maximum speed limit for this device.Refer to SPN 12176 [Reference Speed] to convert % to rpm. Request a value of FBFh to instruct the inverter to use ...";
CM_ SG_ 2566593278 MtrGnrtr6InvrtrLmtsRqstSpdMnmm "Motor/Generator 6 Inverter Limits Request Speed Minimum: This is a request to the inverter to set a minimum speed limit for this device.Refer to SPN 12176 [Reference Speed] to convert % to rpm. Request a value of FBFh to instruct the inverter to use ...";
CM_ BO_ 2566593534 "Motor/Generator 6 Inverter Limits Request DC Side";
CM_ SG_ 2566593534 MtrGnrtr6InvrtrLmtsRqstDCSdCRC "Motor/Generator 6 Inverter Limits Request DC Side CRC: The CRC is defined as follows:• Length: 8 bits• Polynomial: x^8+x^5+x^3+x^2+x+1• Initial Value: FFh• Input Data Reflection: Not reflected• Result Data Reflection: Not reflected• XOR value: FFhSAE...";
CM_ SG_ 2566593534 MtrGnrtr6InvrtrLmtsRqstDCSdCntr "Motor/Generator 6 Inverter Limits Request DC Side Counter: The message counter is used to detect situations where the transmitting ECU malfunction repeats the same frame all the time. The receiver of the information may use the counter parameter to d...";
CM_ SG_ 2566593534 MtGt6IvtLtsRqstDCSdVtMx "Motor/Generator 6 Inverter Limits Request DC Side Voltage Maximum: This is a request to the inverter to set a maximum DC Side Voltage limit for this device instance.Refer to SPN 12208 [Reference Voltage] to convert % to Volts. Request a value of FBFh...";
CM_ SG_ 2566593534 MtGt6IvtLtsRqstDCSdVtM "Motor/Generator 6 Inverter Limits Request DC Side Voltage Minimum: This is a request to the inverter to set a minimum DC Side Voltage limit for this device instance.Refer to SPN 12208 [Reference Voltage] to convert % to Volts. Request a value of FBFh...";
CM_ SG_ 2566593534 MtGt6IvtLtsRqstDCSdCtMx "Motor/Generator 6 Inverter Limits Request DC Side Current Maximum: This is a request to the inverter to set a maximum DC Side Current limit for this device instance.Refer to SPN 12207 [Reference Current] to convert % to Amps. Request a value of FBFh ...";
CM_ SG_ 2566593534 MtGt6IvtLtsRqstDCSdCtM "Motor/Generator 6 Inverter Limits Request DC Side Current Minimum: This is a request to the inverter to set a minimum DC Side Current limit for this device instance.Refer to SPN 12207 [Reference Current] to convert % to Amps. Request a value of FBFh ...";
CM_ BO_ 2566593790 "Motor/Generator 6 Inverter Isolation Integrity Request";
CM_ SG_ 2566593790 MtGt6IvtHVtBsAtvIstTstCd "Motor/Generator 6 Inverter High-Voltage Bus Active Isolation Test Command: Command for the inverter to perform an active electrical isolation test on the high voltage bus.An active isolation test might use a generated signal (e.g. an injected AC sign...";
CM_ SG_ 2566593790 MtGt6IvtHVtBsPssvIstTstCd "Motor/Generator 6 Inverter High-Voltage Bus Passive Isolation Test Command: Command for the inverter to perform a passive electrical isolation test on the high voltage bus.A passive isolation test uses additional circuitry (e.g. a high impedance netw...";
CM_ SG_ 2566593790 MtGt6IvtHVtBsHSdRsstCtRqst "Motor/Generator 6 Inverter High-Voltage Bus High Side Resistor Connect Request: This parameter is used to request connection of the inverter High-Voltage bus high side resistor in order to perform an isolation test. 00b = Connection not Requested01b ...";
CM_ SG_ 2566593790 MtGt6IvtHVtBsLwSdRsstCtRqst "Motor/Generator 6 Inverter High-Voltage Bus Low Side Resistor Connect Request: This parameter is used to request connection of the inverter High-Voltage bus low side resistor in order to perform an isolation test.  00b = Connection not Requested01b =...";
CM_ BO_ 2365267454 "Motor/Generator 5 Inverter Control 2";
CM_ SG_ 2365267454 MtrGnrtr5InvrtrRtLmtsRqst2CRC "Motor/Generator 5 Inverter Rate Limits Request 2 CRC: The CRC is defined as follows:• Length: 8 bits• Polynomial: x^8+x^5+x^3+x^2+x+1• Initial Value: FFh• Input Data Reflection: Not reflected• Result Data Reflection: Not reflected• XOR value: FFhSAE ...";
CM_ SG_ 2365267454 MtrGnrtr5InvrtrRtLmtsRqst2Cntr "Motor/Generator 5 Inverter Rate Limits Request 2 Counter: The message counter is used to detect situations where the transmitting ECU malfunction repeats the same frame all the time. The receiver of the information may use the counter parameter to de...";
CM_ SG_ 2365267454 MtrGnrtr5InvrtrPIDCntrlAppllMd "Motor/Generator 5 Inverter PID Control Applicable Mode : Defines the Mode that the PID Gain parameters apply for this instance of the inverter.  See SPN 12054 [Control Setpoint Mode] for a definition of modes for control purposes.Applicable modes:000...";
CM_ SG_ 2365267454 MtGt5IvtPIDCtNzdDtG "Motor/Generator 5 Inverter PID Control Normalized Differential Gain: A PID controller can be parametrized by factors Kp, Ki and Kd. This parameter defines the normalized integral gain (Kin) for control applications in this inverter instance. The norm...";
CM_ SG_ 2365267454 MtGt5IvtPIDCtNzdItG "Motor/Generator 5 Inverter PID Control Normalized Integral Gain: A PID controller can be parametrized by factors Kp, Ki and Kd. This parameter defines the normalized integral gain (Kin) for control applications in this inverter instance. The normaliz...";
CM_ SG_ 2365267454 MtGt5IvtPIDCtNzdPptG "Motor/Generator 5 Inverter PID Control Normalized Proportional Gain: A PID controller can be parametrized by factors Kp, Ki and Kd. This parameter defines the normalized proportional gain (Kpn) for control applications in this inverter instance. The ...";
CM_ SG_ 2365267454 MtGt5IvtPIDCtFdFwdTq "Motor/Generator 5 Inverter PID Control Feed-Forward Torque: A PID controller can have a Feed-Forward Torque added to its output. This parameter defines the Feed-Forward Torque Setpoint for control applications in this inverter instance. The Setpoint ...";
CM_ BO_ 2566594302 "Motor/Generator 5 Inverter Limits Request Power";
CM_ SG_ 2566594302 MtrGnrtr5InvrtrLmtsRqstPwrCRC "Motor/Generator 5 Inverter Limits Request Power CRC: The CRC is defined as follows:• Length: 8 bits• Polynomial: x^8+x^5+x^3+x^2+x+1• Initial Value: FFh• Input Data Reflection: Not reflected• Result Data Reflection: Not reflected• XOR value: FFhSAE m...";
CM_ SG_ 2566594302 MtrGnrtr5InvrtrLmtsRqstPwrCntr "Motor/Generator 5 Inverter Limits Request Power Counter: The message counter is used to detect situations where the transmitting ECU malfunction repeats the same frame all the time. The receiver of the information may use the counter parameter to det...";
CM_ SG_ 2566594302 MtGt5IvtLtsRqstMPwMx "Motor/Generator 5 Inverter Limits Request Mechanical Power Maximum: This requests a maximum limit for the mechanical power.Refer to SPN 12059 [Reference Power] to convert % to kW. Request a value of FBFh to instruct the inverter to use its default va...";
CM_ SG_ 2566594302 MtGt5IvtLtsRqstMPwM "Motor/Generator 5 Inverter Limits Request Mechanical Power Minimum: This requests a minimum limit for the mechanical power.Refer to SPN 12059 [Reference Power] to convert % to kW. Request a value of FBFh to instruct the inverter to use its default va...";
CM_ SG_ 2566594302 MtGt5IvtLtsRqstDCSdPwMx "Motor/Generator 5 Inverter Limits Request DC Side Power Maximum: This requests a maximum limit for the DC Side power.Refer to SPN 12059 [Reference Power] to convert % to kW. Request a value of FBFh to instruct the inverter to use its default values.F...";
CM_ SG_ 2566594302 MtGt5IvtLtsRqstDCSdPwM "Motor/Generator 5 Inverter Limits Request DC Side Power Minimum: This requests a minimum limit for the DC Side power.Refer to SPN 12059 [Reference Power] to convert % to kW. Request a value of FBFh to instruct the inverter to use its default values.F...";
CM_ BO_ 2566594558 "Motor/Generator 5 Inverter Limits Request Mechanical";
CM_ SG_ 2566594558 MtrGnrtr5InvrtrLmtsRqstMhnlCRC "Motor/Generator 5 Inverter Limits Request Mechanical CRC: The CRC is defined as follows:• Length: 8 bits• Polynomial: x^8+x^5+x^3+x^2+x+1• Initial Value: FFh• Input Data Reflection: Not reflected• Result Data Reflection: Not reflected• XOR value: FFh...";
CM_ SG_ 2566594558 MtrGnrtr5InvrtrLmtsRqstMhnlCntr "Motor/Generator 5 Inverter Limits Request Mechanical Counter: The message counter is used to detect situations where the transmitting ECU malfunction repeats the same frame all the time. The receiver of the information may use the counter parameter t...";
CM_ SG_ 2566594558 MtrGnrtr5InvrtrLmtsRqstTrqMxmm "Motor/Generator 5 Inverter Limits Request Torque Maximum: This requests a maximum torque the inverter should command for this device.Refer to SPN 12057 [Reference Torque] to convert % to Nm. Request a value of FBFh to instruct the inverter to use its...";
CM_ SG_ 2566594558 MtrGnrtr5InvrtrLmtsRqstTrqMnmm "Motor/Generator 5 Inverter Limits Request Torque Minimum: This requests a minimum torque the inverter should command for this device.Refer to SPN 12057 [Reference Torque] to convert % to Nm. Request a value of FBFh to instruct the inverter to use its...";
CM_ SG_ 2566594558 MtrGnrtr5InvrtrLmtsRqstSpdMxmm "Motor/Generator 5 Inverter Limits Request Speed Maximum: This is a request to the inverter to set a maximum speed limit for this device.Refer to SPN 12058 [Reference Speed] to convert % to rpm. Request a value of FBFh to instruct the inverter to use ...";
CM_ SG_ 2566594558 MtrGnrtr5InvrtrLmtsRqstSpdMnmm "Motor/Generator 5 Inverter Limits Request Speed Minimum: This is a request to the inverter to set a minimum speed limit for this device.Refer to SPN 12058 [Reference Speed] to convert % to rpm. Request a value of FBFh to instruct the inverter to use ...";
CM_ BO_ 2566594814 "Motor/Generator 5 Inverter Limits Request DC Side";
CM_ SG_ 2566594814 MtrGnrtr5InvrtrLmtsRqstDCSdCRC "Motor/Generator 5 Inverter Limits Request DC Side CRC: The CRC is defined as follows:• Length: 8 bits• Polynomial: x^8+x^5+x^3+x^2+x+1• Initial Value: FFh• Input Data Reflection: Not reflected• Result Data Reflection: Not reflected• XOR value: FFhSAE...";
CM_ SG_ 2566594814 MtrGnrtr5InvrtrLmtsRqstDCSdCntr "Motor/Generator 5 Inverter Limits Request DC Side Counter: The message counter is used to detect situations where the transmitting ECU malfunction repeats the same frame all the time. The receiver of the information may use the counter parameter to d...";
CM_ SG_ 2566594814 MtGt5IvtLtsRqstDCSdVtMx "Motor/Generator 5 Inverter Limits Request DC Side Voltage Maximum: This is a request to the inverter to set a maximum DC Side Voltage limit for this device instance.Refer to SPN 12090 [Reference Voltage] to convert % to Volts. Request a value of FBFh...";
CM_ SG_ 2566594814 MtGt5IvtLtsRqstDCSdVtM "Motor/Generator 5 Inverter Limits Request DC Side Voltage Minimum: This is a request to the inverter to set a minimum DC Side Voltage limit for this device instance.Refer to SPN 12090 [Reference Voltage] to convert % to Volts. Request a value of FBFh...";
CM_ SG_ 2566594814 MtGt5IvtLtsRqstDCSdCtMx "Motor/Generator 5 Inverter Limits Request DC Side Current Maximum: This is a request to the inverter to set a maximum DC Side Current limit for this device instance.Refer to SPN 12089 [Reference Current] to convert % to Amps. Request a value of FBFh ...";
CM_ SG_ 2566594814 MtGt5IvtLtsRqstDCSdCtM "Motor/Generator 5 Inverter Limits Request DC Side Current Minimum: This is a request to the inverter to set a minimum DC Side Current limit for this device instance.Refer to SPN 12089 [Reference Current] to convert % to Amps. Request a value of FBFh ...";
CM_ BO_ 2566595070 "Motor/Generator 5 Inverter Isolation Integrity Request";
CM_ SG_ 2566595070 MtGt5IvtHVtBsAtvIstTstCd "Motor/Generator 5 Inverter High-Voltage Bus Active Isolation Test Command: Command for the inverter to perform an active electrical isolation test on the high voltage bus.An active isolation test might use a generated signal (e.g. an injected AC sign...";
CM_ SG_ 2566595070 MtGt5IvtHVtBsPssvIstTstCd "Motor/Generator 5 Inverter High-Voltage Bus Passive Isolation Test Command: Command for the inverter to perform a passive electrical isolation test on the high voltage bus.A passive isolation test uses additional circuitry (e.g. a high impedance netw...";
CM_ SG_ 2566595070 MtGt5IvtHVtBsHSdRsstCtRqst "Motor/Generator 5 Inverter High-Voltage Bus High Side Resistor Connect Request: This parameter is used to request connection of the inverter High-Voltage bus high side resistor in order to perform an isolation test. 00b = Connection not Requested01b ...";
CM_ SG_ 2566595070 MtGt5IvtHVtBsLwSdRsstCtRqst "Motor/Generator 5 Inverter High-Voltage Bus Low Side Resistor Connect Request: This parameter is used to request connection of the inverter High-Voltage bus low side resistor in order to perform an isolation test.  00b = Connection not Requested01b =...";
CM_ BO_ 2365268734 "Motor/Generator 4 Inverter Control 2";
CM_ SG_ 2365268734 MtrGnrtr4InvrtrRtLmtsRqst2CRC "Motor/Generator 4 Inverter Rate Limits Request 2 CRC: The CRC is defined as follows:• Length: 8 bits• Polynomial: x^8+x^5+x^3+x^2+x+1• Initial Value: FFh• Input Data Reflection: Not reflected• Result Data Reflection: Not reflected• XOR value: FFhSAE ...";
CM_ SG_ 2365268734 MtrGnrtr4InvrtrRtLmtsRqst2Cntr "Motor/Generator 4 Inverter Rate Limits Request 2 Counter: The message counter is used to detect situations where the transmitting ECU malfunction repeats the same frame all the time. The receiver of the information may use the counter parameter to de...";
CM_ SG_ 2365268734 MtrGnrtr4InvrtrPIDCntrlAppllMd "Motor/Generator 4 Inverter PID Control Applicable Mode : Defines the Mode that the PID Gain parameters apply for this instance of the inverter.  See SPN 11936 [Control Setpoint Mode] for a definition of modes for control purposes.Applicable modes:000...";
CM_ SG_ 2365268734 MtGt4IvtPIDCtNzdDtG "Motor/Generator 4 Inverter PID Control Normalized Differential Gain: A PID controller can be parametrized by factors Kp, Ki and Kd. This parameter defines the normalized integral gain (Kin) for control applications in this inverter instance. The norm...";
CM_ SG_ 2365268734 MtGt4IvtPIDCtNzdItG "Motor/Generator 4 Inverter PID Control Normalized Integral Gain: A PID controller can be parametrized by factors Kp, Ki and Kd. This parameter defines the normalized integral gain (Kin) for control applications in this inverter instance. The normaliz...";
CM_ SG_ 2365268734 MtGt4IvtPIDCtNzdPptG "Motor/Generator 4 Inverter PID Control Normalized Proportional Gain: A PID controller can be parametrized by factors Kp, Ki and Kd. This parameter defines the normalized proportional gain (Kpn) for control applications in this inverter instance. The ...";
CM_ SG_ 2365268734 MtGt4IvtPIDCtFdFwdTq "Motor/Generator 4 Inverter PID Control Feed-Forward Torque: A PID controller can have a Feed-Forward Torque added to its output. This parameter defines the Feed-Forward Torque Setpoint for control applications in this inverter instance. The Setpoint ...";
CM_ BO_ 2566595582 "Motor/Generator 4 Inverter Limits Request Power";
CM_ SG_ 2566595582 MtrGnrtr4InvrtrLmtsRqstPwrCRC "Motor/Generator 4 Inverter Limits Request Power CRC: The CRC is defined as follows:• Length: 8 bits• Polynomial: x^8+x^5+x^3+x^2+x+1• Initial Value: FFh• Input Data Reflection: Not reflected• Result Data Reflection: Not reflected• XOR value: FFhSAE m...";
CM_ SG_ 2566595582 MtrGnrtr4InvrtrLmtsRqstPwrCntr "Motor/Generator 4 Inverter Limits Request Power Counter: The message counter is used to detect situations where the transmitting ECU malfunction repeats the same frame all the time. The receiver of the information may use the counter parameter to det...";
CM_ SG_ 2566595582 MtGt4IvtLtsRqstMPwMx "Motor/Generator 4 Inverter Limits Request Mechanical Power Maximum: This requests a maximum limit for the mechanical power.Refer to SPN 11941 [Reference Power] to convert % to kW. Request a value of FBFh to instruct the inverter to use its default va...";
CM_ SG_ 2566595582 MtGt4IvtLtsRqstMPwM "Motor/Generator 4 Inverter Limits Request Mechanical Power Minimum: This requests a minimum limit for the mechanical power.Refer to SPN 11941 [Reference Power] to convert % to kW. Request a value of FBFh to instruct the inverter to use its default va...";
CM_ SG_ 2566595582 MtGt4IvtLtsRqstDCSdPwMx "Motor/Generator 4 Inverter Limits Request DC Side Power Maximum: This requests a maximum limit for the DC Side power.Refer to SPN 11941 [Reference Power] to convert % to kW. Request a value of FBFh to instruct the inverter to use its default values.F...";
CM_ SG_ 2566595582 MtGt4IvtLtsRqstDCSdPwM "Motor/Generator 4 Inverter Limits Request DC Side Power Minimum: This requests a minimum limit for the DC Side power.Refer to SPN 11941 [Reference Power] to convert % to kW. Request a value of FBFh to instruct the inverter to use its default values.F...";
CM_ BO_ 2566595838 "Motor/Generator 4 Inverter Limits Request Mechanical";
CM_ SG_ 2566595838 MtrGnrtr4InvrtrLmtsRqstMhnlCRC "Motor/Generator 4 Inverter Limits Request Mechanical CRC: The CRC is defined as follows:• Length: 8 bits• Polynomial: x^8+x^5+x^3+x^2+x+1• Initial Value: FFh• Input Data Reflection: Not reflected• Result Data Reflection: Not reflected• XOR value: FFh...";
CM_ SG_ 2566595838 MtrGnrtr4InvrtrLmtsRqstMhnlCntr "Motor/Generator 4 Inverter Limits Request Mechanical Counter: The message counter is used to detect situations where the transmitting ECU malfunction repeats the same frame all the time. The receiver of the information may use the counter parameter t...";
CM_ SG_ 2566595838 MtrGnrtr4InvrtrLmtsRqstTrqMxmm "Motor/Generator 4 Inverter Limits Request Torque Maximum: This requests a maximum torque the inverter should command for this device.Refer to SPN 11939 [Reference Torque] to convert % to Nm. Request a value of FBFh to instruct the inverter to use its...";
CM_ SG_ 2566595838 MtrGnrtr4InvrtrLmtsRqstTrqMnmm "Motor/Generator 4 Inverter Limits Request Torque Minimum: This requests a minimum torque the inverter should command for this device.Refer to SPN 11939 [Reference Torque] to convert % to Nm. Request a value of FBFh to instruct the inverter to use its...";
CM_ SG_ 2566595838 MtrGnrtr4InvrtrLmtsRqstSpdMxmm "Motor/Generator 4 Inverter Limits Request Speed Maximum: This is a request to the inverter to set a maximum speed limit for this device.Refer to SPN 11940 [Reference Speed] to convert % to rpm. Request a value of FBFh to instruct the inverter to use ...";
CM_ SG_ 2566595838 MtrGnrtr4InvrtrLmtsRqstSpdMnmm "Motor/Generator 4 Inverter Limits Request Speed Minimum: This is a request to the inverter to set a minimum speed limit for this device.Refer to SPN 11940 [Reference Speed] to convert % to rpm. Request a value of FBFh to instruct the inverter to use ...";
CM_ BO_ 2566596094 "Motor/Generator 4 Inverter Limits Request DC Side";
CM_ SG_ 2566596094 MtrGnrtr4InvrtrLmtsRqstDCSdCRC "Motor/Generator 4 Inverter Limits Request DC Side CRC: The CRC is defined as follows:• Length: 8 bits• Polynomial: x^8+x^5+x^3+x^2+x+1• Initial Value: FFh• Input Data Reflection: Not reflected• Result Data Reflection: Not reflected• XOR value: FFhSAE...";
CM_ SG_ 2566596094 MtrGnrtr4InvrtrLmtsRqstDCSdCntr "Motor/Generator 4 Inverter Limits Request DC Side Counter: The message counter is used to detect situations where the transmitting ECU malfunction repeats the same frame all the time. The receiver of the information may use the counter parameter to d...";
CM_ SG_ 2566596094 MtGt4IvtLtsRqstDCSdVtMx "Motor/Generator 4 Inverter Limits Request DC Side Voltage Maximum: This is a request to the inverter to set a maximum DC Side Voltage limit for this device instance.Refer to SPN 11972 [Reference Voltage] to convert % to Volts. Request a value of FBFh...";
CM_ SG_ 2566596094 MtGt4IvtLtsRqstDCSdVtM "Motor/Generator 4 Inverter Limits Request DC Side Voltage Minimum: This is a request to the inverter to set a minimum DC Side Voltage limit for this device instance.Refer to SPN 11972 [Reference Voltage] to convert % to Volts. Request a value of FBFh...";
CM_ SG_ 2566596094 MtGt4IvtLtsRqstDCSdCtMx "Motor/Generator 4 Inverter Limits Request DC Side Current Maximum: This is a request to the inverter to set a maximum DC Side Current limit for this device instance.Refer to SPN 11971 [Reference Current] to convert % to Amps. Request a value of FBFh ...";
CM_ SG_ 2566596094 MtGt4IvtLtsRqstDCSdCtM "Motor/Generator 4 Inverter Limits Request DC Side Current Minimum: This is a request to the inverter to set a minimum DC Side Current limit for this device instance.Refer to SPN 11971 [Reference Current] to convert % to Amps. Request a value of FBFh ...";
CM_ BO_ 2566596350 "Motor/Generator 4 Inverter Isolation Integrity Request";
CM_ SG_ 2566596350 MtGt4IvtHVtBsAtvIstTstCd "Motor/Generator 4 Inverter High-Voltage Bus Active Isolation Test Command: Command for the inverter to perform an active electrical isolation test on the high voltage bus.An active isolation test might use a generated signal (e.g. an injected AC sign...";
CM_ SG_ 2566596350 MtGt4IvtHVtBsPssvIstTstCd "Motor/Generator 4 Inverter High-Voltage Bus Passive Isolation Test Command: Command for the inverter to perform a passive electrical isolation test on the high voltage bus.A passive isolation test uses additional circuitry (e.g. a high impedance netw...";
CM_ SG_ 2566596350 MtGt4IvtHVtBsHSdRsstCtRqst "Motor/Generator 4 Inverter High-Voltage Bus High Side Resistor Connect Request: This parameter is used to request connection of the inverter High-Voltage bus high side resistor in order to perform an isolation test. 00b = Connection not Requested01b ...";
CM_ SG_ 2566596350 MtGt4IvtHVtBsLwSdRsstCtRqst "Motor/Generator 4 Inverter High-Voltage Bus Low Side Resistor Connect Request: This parameter is used to request connection of the inverter High-Voltage bus low side resistor in order to perform an isolation test.  00b = Connection not Requested01b =...";
CM_ BO_ 2365270014 "Motor/Generator 3 Inverter Control 2";
CM_ SG_ 2365270014 MtrGnrtr3InvrtrRtLmtsRqst2CRC "Motor/Generator 3 Inverter Rate Limits Request 2 CRC: The CRC is defined as follows:• Length: 8 bits• Polynomial: x^8+x^5+x^3+x^2+x+1• Initial Value: FFh• Input Data Reflection: Not reflected• Result Data Reflection: Not reflected• XOR value: FFhSAE ...";
CM_ SG_ 2365270014 MtrGnrtr3InvrtrRtLmtsRqst2Cntr "Motor/Generator 3 Inverter Rate Limits Request 2 Counter: The message counter is used to detect situations where the transmitting ECU malfunction repeats the same frame all the time. The receiver of the information may use the counter parameter to de...";
CM_ SG_ 2365270014 MtrGnrtr3InvrtrPIDCntrlAppllMd "Motor/Generator 3 Inverter PID Control Applicable Mode : Defines the Mode that the PID Gain parameters apply for this instance of the inverter.  See SPN 11818 [Control Setpoint Mode] for a definition of modes for control purposes.Applicable modes:000...";
CM_ SG_ 2365270014 MtGt3IvtPIDCtNzdDtG "Motor/Generator 3 Inverter PID Control Normalized Differential Gain: A PID controller can be parametrized by factors Kp, Ki and Kd. This parameter defines the normalized integral gain (Kin) for control applications in this inverter instance. The norm...";
CM_ SG_ 2365270014 MtGt3IvtPIDCtNzdItG "Motor/Generator 3 Inverter PID Control Normalized Integral Gain: A PID controller can be parametrized by factors Kp, Ki and Kd. This parameter defines the normalized integral gain (Kin) for control applications in this inverter instance. The normaliz...";
CM_ SG_ 2365270014 MtGt3IvtPIDCtNzdPptG "Motor/Generator 3 Inverter PID Control Normalized Proportional Gain: A PID controller can be parametrized by factors Kp, Ki and Kd. This parameter defines the normalized proportional gain (Kpn) for control applications in this inverter instance. The ...";
CM_ SG_ 2365270014 MtGt3IvtPIDCtFdFwdTq "Motor/Generator 3 Inverter PID Control Feed-Forward Torque: A PID controller can have a Feed-Forward Torque added to its output. This parameter defines the Feed-Forward Torque Setpoint for control applications in this inverter instance. The Setpoint ...";
CM_ BO_ 2566596862 "Motor/Generator 3 Inverter Limits Request Power";
CM_ SG_ 2566596862 MtrGnrtr3InvrtrLmtsRqstPwrCRC "Motor/Generator 3 Inverter Limits Request Power CRC: The CRC is defined as follows:• Length: 8 bits• Polynomial: x^8+x^5+x^3+x^2+x+1• Initial Value: FFh• Input Data Reflection: Not reflected• Result Data Reflection: Not reflected• XOR value: FFhSAE m...";
CM_ SG_ 2566596862 MtrGnrtr3InvrtrLmtsRqstPwrCntr "Motor/Generator 3 Inverter Limits Request Power Counter: The message counter is used to detect situations where the transmitting ECU malfunction repeats the same frame all the time. The receiver of the information may use the counter parameter to det...";
CM_ SG_ 2566596862 MtGt3IvtLtsRqstMPwMx "Motor/Generator 3 Inverter Limits Request Mechanical Power Maximum: This requests a maximum limit for the mechanical power.Refer to SPN 11823 [Reference Power] to convert % to kW. Request a value of FBFh to instruct the inverter to use its default va...";
CM_ SG_ 2566596862 MtGt3IvtLtsRqstMPwM "Motor/Generator 3 Inverter Limits Request Mechanical Power Minimum: This requests a minimum limit for the mechanical power.Refer to SPN 11823 [Reference Power] to convert % to kW. Request a value of FBFh to instruct the inverter to use its default va...";
CM_ SG_ 2566596862 MtGt3IvtLtsRqstDCSdPwMx "Motor/Generator 3 Inverter Limits Request DC Side Power Maximum: This requests a maximum limit for the DC Side power.Refer to SPN 11823 [Reference Power] to convert % to kW. Request a value of FBFh to instruct the inverter to use its default values.F...";
CM_ SG_ 2566596862 MtGt3IvtLtsRqstDCSdPwM "Motor/Generator 3 Inverter Limits Request DC Side Power Minimum: This requests a minimum limit for the DC Side power.Refer to SPN 11823 [Reference Power] to convert % to kW. Request a value of FBFh to instruct the inverter to use its default values.F...";
CM_ BO_ 2566597118 "Motor/Generator 3 Inverter Limits Request Mechanical";
CM_ SG_ 2566597118 MtrGnrtr3InvrtrLmtsRqstMhnlCRC "Motor/Generator 3 Inverter Limits Request Mechanical CRC: The CRC is defined as follows:• Length: 8 bits• Polynomial: x^8+x^5+x^3+x^2+x+1• Initial Value: FFh• Input Data Reflection: Not reflected• Result Data Reflection: Not reflected• XOR value: FFh...";
CM_ SG_ 2566597118 MtrGnrtr3InvrtrLmtsRqstMhnlCntr "Motor/Generator 3 Inverter Limits Request Mechanical Counter: The message counter is used to detect situations where the transmitting ECU malfunction repeats the same frame all the time. The receiver of the information may use the counter parameter t...";
CM_ SG_ 2566597118 MtrGnrtr3InvrtrLmtsRqstTrqMxmm "Motor/Generator 3 Inverter Limits Request Torque Maximum: This requests a maximum torque the inverter should command for this device.Refer to SPN 11821 [Reference Torque] to convert % to Nm. Request a value of FBFh to instruct the inverter to use its...";
CM_ SG_ 2566597118 MtrGnrtr3InvrtrLmtsRqstTrqMnmm "Motor/Generator 3 Inverter Limits Request Torque Minimum: This requests a minimum torque the inverter should command for this device.Refer to SPN 11821 [Reference Torque] to convert % to Nm. Request a value of FBFh to instruct the inverter to use its...";
CM_ SG_ 2566597118 MtrGnrtr3InvrtrLmtsRqstSpdMxmm "Motor/Generator 3 Inverter Limits Request Speed Maximum: This is a request to the inverter to set a maximum speed limit for this device.Refer to SPN 11822 [Reference Speed] to convert % to rpm. Request a value of FBFh to instruct the inverter to use ...";
CM_ SG_ 2566597118 MtrGnrtr3InvrtrLmtsRqstSpdMnmm "Motor/Generator 3 Inverter Limits Request Speed Minimum: This is a request to the inverter to set a minimum speed limit for this device.Refer to SPN 11822 [Reference Speed] to convert % to rpm. Request a value of FBFh to instruct the inverter to use ...";
CM_ BO_ 2566597374 "Motor/Generator 3 Inverter Limits Request DC Side";
CM_ SG_ 2566597374 MtrGnrtr3InvrtrLmtsRqstDCSdCRC "Motor/Generator 3 Inverter Limits Request DC Side CRC: The CRC is defined as follows:• Length: 8 bits• Polynomial: x^8+x^5+x^3+x^2+x+1• Initial Value: FFh• Input Data Reflection: Not reflected• Result Data Reflection: Not reflected• XOR value: FFhSAE...";
CM_ SG_ 2566597374 MtrGnrtr3InvrtrLmtsRqstDCSdCntr "Motor/Generator 3 Inverter Limits Request DC Side Counter: The message counter is used to detect situations where the transmitting ECU malfunction repeats the same frame all the time. The receiver of the information may use the counter parameter to d...";
CM_ SG_ 2566597374 MtGt3IvtLtsRqstDCSdVtMx "Motor/Generator 3 Inverter Limits Request DC Side Voltage Maximum: This is a request to the inverter to set a maximum DC Side Voltage limit for this device instance.Refer to SPN 11854 [Reference Voltage] to convert % to Volts. Request a value of FBFh...";
CM_ SG_ 2566597374 MtGt3IvtLtsRqstDCSdVtM "Motor/Generator 3 Inverter Limits Request DC Side Voltage Minimum: This is a request to the inverter to set a minimum DC Side Voltage limit for this device instance.Refer to SPN 11854 [Reference Voltage] to convert % to Volts. Request a value of FBFh...";
CM_ SG_ 2566597374 MtGt3IvtLtsRqstDCSdCtMx "Motor/Generator 3 Inverter Limits Request DC Side Current Maximum: This is a request to the inverter to set a maximum DC Side Current limit for this device instance.Refer to SPN 11853 [Reference Current] to convert % to Amps. Request a value of FBFh ...";
CM_ SG_ 2566597374 MtGt3IvtLtsRqstDCSdCtM "Motor/Generator 3 Inverter Limits Request DC Side Current Minimum: This is a request to the inverter to set a minimum DC Side Current limit for this device instance.Refer to SPN 11853 [Reference Current] to convert % to Amps. Request a value of FBFh ...";
CM_ BO_ 2566597630 "Motor/Generator 3 Inverter Isolation Integrity Request";
CM_ SG_ 2566597630 MtGt3IvtHVtBsAtvIstTstCd "Motor/Generator 3 Inverter High-Voltage Bus Active Isolation Test Command: Command for the inverter to perform an active electrical isolation test on the high voltage bus.An active isolation test might use a generated signal (e.g. an injected AC sign...";
CM_ SG_ 2566597630 MtGt3IvtHVtBsPssvIstTstCd "Motor/Generator 3 Inverter High-Voltage Bus Passive Isolation Test Command: Command for the inverter to perform a passive electrical isolation test on the high voltage bus.A passive isolation test uses additional circuitry (e.g. a high impedance netw...";
CM_ SG_ 2566597630 MtGt3IvtHVtBsHSdRsstCtRqst "Motor/Generator 3 Inverter High-Voltage Bus High Side Resistor Connect Request: This parameter is used to request connection of the inverter High-Voltage bus high side resistor in order to perform an isolation test. 00b = Connection not Requested01b ...";
CM_ SG_ 2566597630 MtGt3IvtHVtBsLwSdRsstCtRqst "Motor/Generator 3 Inverter High-Voltage Bus Low Side Resistor Connect Request: This parameter is used to request connection of the inverter High-Voltage bus low side resistor in order to perform an isolation test.  00b = Connection not Requested01b =...";
CM_ BO_ 2566598142 "Turbocharger Information 8";
CM_ SG_ 2566598142 EngineTurbocharger5Speed "Engine Turbocharger 5 Speed: Rotational velocity of rotor in the turbocharger.";
CM_ SG_ 2566598142 EngineTurbocharger6Speed "Engine Turbocharger 6 Speed: Rotational velocity of rotor in the turbocharger.";
CM_ SG_ 2566598142 EngnTrhrgr5CmprssrIntkPrssr "Engine Turbocharger 5 Compressor Intake Pressure: Gage pressure of the air entering the compressor side of the turbocharger.";
CM_ SG_ 2566598142 EngnTrhrgr6CmprssrIntkPrssr "Engine Turbocharger 6 Compressor Intake Pressure: Gage pressure of the air entering the compressor side of the turbocharger.";
CM_ BO_ 2566598398 "Winch Information 2";
CM_ SG_ 2566598398 WinchLifetimeRevolutionCounter "Winch Lifetime Revolution Counter: Accumulated number of revolutions of winch motor during its operation. This includes both forward and reverse directions and may be used for maintenance purposes.";
CM_ BO_ 2365272062 "Motor/Generator 6 Inverter Reference 1";
CM_ SG_ 2365272062 MtrGnrtr6InvrtrRfrn1CRC "Motor/Generator 6 Inverter Reference 1 CRC: The CRC is defined as follows:• Length: 8 bits• Polynomial: x^8+x^5+x^3+x^2+x+1• Initial Value: FFh• Input Data Reflection: Not reflected• Result Data Reflection: Not reflected• XOR value: FFhSAE makes no c...";
CM_ SG_ 2365272062 MtrGnrtr6InvrtrRfrn1Cntr "Motor/Generator 6 Inverter Reference 1 Counter: The message counter is used to detect situations where the transmitting ECU malfunction repeats the same frame all the time. The receiver of the information may use the counter parameter to detect this ...";
CM_ SG_ 2365272062 MtrGnrtr6InvrtrRfrnTrq "Motor/Generator 6 Inverter Reference Torque: This value is used for converting torque in percent to units of Nm.Value in Nm = (Percent Value)/(100%) * (Reference Torque)For example, if this parameter has a value of 400 Nm and the percent value is equ...";
CM_ SG_ 2365272062 MtrGnrtr6InvrtrRfrnSpd "Motor/Generator 6 Inverter Reference Speed: This value is used for converting Speed in percent to units of rpm.Value in rpm = (Percent Value)/(100%) * (Reference Speed)For example, if this parameter has a value of 8192 rpm and the percent value is eq...";
CM_ SG_ 2365272062 MtrGnrtr6InvrtrRfrnPwr "Motor/Generator 6 Inverter Reference Power: This value is used for converting power in percent to units of kW.  It is applicable to both mechanical and electrical power.(Value in kW) = (Percent Value)/(100%) * (Reference Power)For example, if this pa...";
CM_ BO_ 2365272318 "Motor/Generator 6 Inverter Status 1";
CM_ SG_ 2365272318 MtrGnrtr6InvrtrStts1CRC "Motor/Generator 6 Inverter Status 1 CRC: The CRC is defined as follows:• Length: 8 bits• Polynomial: x^8+x^5+x^3+x^2+x+1• Initial Value: FFh• Input Data Reflection: Not reflected• Result Data Reflection: Not reflected• XOR value: FFhSAE makes no clai...";
CM_ SG_ 2365272318 MtrGnrtr6InvrtrStts1Cntr "Motor/Generator 6 Inverter Status 1 Counter: The message counter is used to detect situations where the transmitting ECU malfunction repeats the same frame all the time. The receiver of the information may use the counter parameter to detect this sit...";
CM_ SG_ 2365272318 MotorGenerator6Torque "Motor/Generator 6 Torque: The measured or estimated motor torque.  This refers to the motor rotor output and excludes any gearbox that may be attached to the motor.Refer to SPN 12175 [Reference Torque] to convert % to Nm.The motor is generating when ...";
CM_ SG_ 2365272318 MotorGenerator6Speed "Motor/Generator 6 Speed: The measured or estimated motor speed.  This refers to the motor rotor output and excludes any gearbox that may be attached to the motor.   Refer to SPN 12176 [Reference Speed] to convert % to rpm.";
CM_ SG_ 2365272318 MtrGnrtr6InvrtrDCSdCrrnt "Motor/Generator 6 Inverter DC Side Current: This is the DC side current of the inverter.Refer to SPN 12207 [Reference Current] to convert % to Amps.While motoring, the current is defined as positive.  For example, in a hybrid propulsion system, posit...";
CM_ SG_ 2365272318 MtrGnrtr6InvrtrDCSdVltg "Motor/Generator 6 Inverter DC Side Voltage: The measured or estimated DC side voltage.  Refer to SPN 12208 [Reference Voltage] to convert % to Volts.";
CM_ BO_ 2365272574 "Motor/Generator 6 Inverter Reference 2";
CM_ SG_ 2365272574 MtrGnrtr6InvrtrRfrn2CRC "Motor/Generator 6 Inverter Reference 2 CRC: The CRC is defined as follows:• Length: 8 bits• Polynomial: x^8+x^5+x^3+x^2+x+1• Initial Value: FFh• Input Data Reflection: Not reflected• Result Data Reflection: Not reflected• XOR value: FFhSAE makes no c...";
CM_ SG_ 2365272574 MtrGnrtr6InvrtrRfrn2Cntr "Motor/Generator 6 Inverter Reference 2 Counter: The message counter is used to detect situations where the transmitting ECU malfunction repeats the same frame all the time. The receiver of the information may use the counter parameter to detect this ...";
CM_ SG_ 2365272574 MtrGnrtr6InvrtrRfrnCrrnt "Motor/Generator 6 Inverter Reference Current: This value is used for converting inverter current in percent to units of Amps (RMS or DC).(Value in Amps) = (Percent Value)/(100%) * (Reference Current)For example, if this parameter has a value of 200 A...";
CM_ SG_ 2365272574 MtrGnrtr6InvrtrRfrnVltg "Motor/Generator 6 Inverter Reference Voltage: This value is used for converting inverter voltage in percent to units of Volts (RMS or DC).(Value in Volts) = (Percent Value)/(100%) * (Reference Voltage)For example, if this parameter has a value of 400...";
CM_ BO_ 2566599422 "Motor/Generator 6 Inverter Temperature";
CM_ SG_ 2566599422 MtrGnrtr6InvrtrTmprtr1 "Motor/Generator 6 Inverter Temperature 1: The exact location of this temperature can be defined by the manufacturer.  It is intended to be located somewhere on the inverter. ";
CM_ SG_ 2566599422 MtrGnrtr6InvrtrTmprtr2 "Motor/Generator 6 Inverter Temperature 2: The exact location of this temperature can be defined by the manufacturer.  It is intended to be located somewhere on the inverter. ";
CM_ SG_ 2566599422 MtrGnrtr6InvrtrTmprtr3 "Motor/Generator 6 Inverter Temperature 3: The exact location of this temperature can be defined by the manufacturer.  It is intended to be located somewhere on the inverter. ";
CM_ SG_ 2566599422 MtrGnrtr6InvrtrTmprtr4 "Motor/Generator 6 Inverter Temperature 4: The exact location of this temperature can be defined by the manufacturer.  It is intended to be located somewhere on the inverter. ";
CM_ BO_ 2566599678 "Motor/Generator 6 Inverter Motor Temperature";
CM_ SG_ 2566599678 MotorGenerator6Temperature1 "Motor/Generator 6 Temperature 1: The exact location of this temperature can be defined by the manufacturer.  It is intended to located somewhere on the motor.";
CM_ SG_ 2566599678 MotorGenerator6Temperature2 "Motor/Generator 6 Temperature 2: The exact location of this temperature can be defined by the manufacturer.  It is intended to located somewhere on the motor. ";
CM_ SG_ 2566599678 MotorGenerator6Temperature3 "Motor/Generator 6 Temperature 3: The exact location of this temperature can be defined by the manufacturer.  It is intended to located somewhere on the motor. ";
CM_ SG_ 2566599678 MotorGenerator6Temperature4 "Motor/Generator 6 Temperature 4: The exact location of this temperature can be defined by the manufacturer.  It is intended to located somewhere on the motor. ";
CM_ BO_ 2566599934 "Motor/Generator 6 Inverter Isolation Integrity";
CM_ SG_ 2566599934 MtrGnrtr6InvrtrIsltnIntgrtCRC "Motor/Generator 6 Inverter Isolation Integrity CRC: The CRC is defined as follows:• Length: 8 bits• Polynomial: x^8+x^5+x^3+x^2+x+1• Initial Value: FFh• Input Data Reflection: Not reflected• Result Data Reflection: Not reflected• XOR value: FFhSAE ma...";
CM_ SG_ 2566599934 MtrGnrtr6InvrtrIsltnIntgrtCntr "Motor/Generator 6 Inverter Isolation Integrity Counter: The message counter is used to detect situations where the transmitting ECU malfunction repeats the same frame all the time. The receiver of the information may use the counter parameter to dete...";
CM_ SG_ 2566599934 MtGt6IvtDCSdNtvtCsssGdVt "Motor/Generator 6 Inverter DC Side Negative to Chassis Ground Voltage: The voltage level of the high voltage DC side, as measured by the inverter between the negative side of the High Voltage DC Side input and the chassis of the inverter enclosure.  ...";
CM_ SG_ 2566599934 MtGt6IvtHVtBsAtvIstTstStts "Motor/Generator 6 Inverter High-Voltage Bus Active Isolation Test Status: Status of the high-voltage bus electrical active isolation test as performed by this instance of the Motor/Generator.0000b = No test requested / No test in process0001b = Test ...";
CM_ SG_ 2566599934 MtGt6IvtHVtBsPssvIstTstStts "Motor/Generator 6 Inverter High-Voltage Bus Passive Isolation Test Status: Status of the high-voltage bus electrical passive isolation test as performed by this instance of the Motor/Generator.0000b = No test requested / No test in process0001b = Tes...";
CM_ SG_ 2566599934 MtGt6IvtHVtBsAtvIstTstRsts "Motor/Generator 6 Inverter High-Voltage Bus Active Isolation Test Results: The isolation resistance that resulted from the High-Voltage Bus Active Isolation Test.See SPN 12239 [High-Voltage Bus Active Isolation Test Status] for test status and SPN 12...";
CM_ SG_ 2566599934 MtGt6IvtHVtBsPssvIstTstRsts "Motor/Generator 6 Inverter High-Voltage Bus Passive Isolation Test Results: The isolation resistance that resulted from the High-Voltage Bus Passive Isolation Test.See SPN 12240 [High-Voltage Bus Passive Isolation Test Status] for test status and SPN...";
CM_ BO_ 2566600190 "Motor/Generator 6 Inverter Active Power Limits";
CM_ SG_ 2566600190 MtGt6IvtPwLtddtUddRs "Motor/Generator 6 Inverter Power Limited due to Undefined Reason: Output power is being limited due to an undefined reason.00b = No power limit for this reason01b = Power limited for this reason10b = Error11b = Not Available";
CM_ SG_ 2566600190 MtGt6IvtPwLtddtDCSdCtMx "Motor/Generator 6 Inverter Power Limited due to DC Side Current Maximum: Output power is being limited due to SPN 12180 [Inverter DC Side Current] approaching or exceeding the SPN 12219 [Inverter Limits Active DC Side Current Maximum].00b = No power ...";
CM_ SG_ 2566600190 MtGt6IvtPwLtddtDCSdCtM "Motor/Generator 6 Inverter Power Limited due to DC Side Current Minimum: Output power is being limited due to SPN 12180 [Inverter DC Side Current] approaching or falling below the SPN 12220 [Inverter Limits Active DC Side Current Minimum].00b = No po...";
CM_ SG_ 2566600190 MtGt6IvtPwLtddtDCSdVtMx "Motor/Generator 6 Inverter Power Limited due to DC Side Voltage Maximum: Output power is being limited due to SPN 12158 [Inverter DC Side Voltage] approaching or exceeding the SPN 12217 [Inverter Limits Active DC Side Voltage Maximum].00b = No power ...";
CM_ SG_ 2566600190 MtGt6IvtPwLtddtDCSdVtM "Motor/Generator 6 Inverter Power Limited due to DC Side Voltage Minimum: Output power is being limited due to SPN 12158 [Inverter DC Side Voltage] approaching or falling below the SPN 12218 [Inverter Limits Active DC Side Voltage Minimum].00b = No po...";
CM_ SG_ 2566600190 MtGt6IvtPwLtddtMPwMx "Motor/Generator 6 Inverter Power Limited due to Mechanical Power Maximum: Output power is being limited due to Mechanical Power (product of SPN 12157 [Torque] and SPN 12155 [Speed]) approaching or exceeding the SPN 12189 [Inverter Limits Active Mecha...";
CM_ SG_ 2566600190 MtGt6IvtPwLtddtMPwM "Motor/Generator 6 Inverter Power Limited due to Mechanical Power Minimum: Output power is being limited due to Mechanical Power (product of SPN 12157 [Torque] and SPN 12155 [Speed]) approaching or falling below the SPN 12190 [Inverter Limits Active M...";
CM_ SG_ 2566600190 MtGt6IvtPwLtddtDCSdPwMx "Motor/Generator 6 Inverter Power Limited due to DC Side Power Maximum: Output power is being limited due to DC Side Power (product of SPN 12180 [Inverter DC Side Current] and SPN 12158 [Inverter DC Side Voltage]) approaching or exceeding the SPN 1219...";
CM_ SG_ 2566600190 MtGt6IvtPwLtddtDCSdPwM "Motor/Generator 6 Inverter Power Limited due to DC Side Power Minimum: Output power is being limited due to DC Side Power (product of SPN 12180 [Inverter DC Side Current] and SPN 12158 [Inverter DC Side Voltage]) approaching or falling below the SPN ...";
CM_ SG_ 2566600190 MtrGnrtr6InvrtrPwrLmtddtTrqMxmm "Motor/Generator 6 Inverter Power Limited due to Torque Maximum: Output power is being limited due to SPN 12157 [Torque] approaching or exceeding the SPN 12201 [Inverter Limits Active Torque Maximum].00b = No power limit for this reason01b = Power lim...";
CM_ SG_ 2566600190 MtrGnrtr6InvrtrPwrLmtddtTrqMnmm "Motor/Generator 6 Inverter Power Limited due to Torque Minimum: Output power is being limited due to SPN 12157 [Torque] approaching or falling below the SPN 12202 [Inverter Limits Active Torque Minimum].00b = No power limit for this reason01b = Power...";
CM_ SG_ 2566600190 MtrGnrtr6InvrtrPwrLmtddtSpdMxmm "Motor/Generator 6 Inverter Power Limited due to Speed Maximum: Output power is being limited due to SPN 12155 [Speed] approaching or exceeding the SPN 12203 [Inverter Limits Active Speed Maximum].00b = No power limit for this reason01b = Power limite...";
CM_ SG_ 2566600190 MtrGnrtr6InvrtrPwrLmtddtSpdMnmm "Motor/Generator 6 Inverter Power Limited due to Speed Minimum: Output power is being limited due to SPN 12155 [Speed] approaching or falling below the SPN 12204 [Inverter Limits Active Speed Minimum].00b = No power limit for this reason01b = Power li...";
CM_ SG_ 2566600190 MtGt6IvtPwLtddtIvtTpt "Motor/Generator 6 Inverter Power Limited due to Inverter Temperature: Output power is being limited due to one or more inverter temperature(s), see SPNs 12221 through 12224 [Inverter Temperature 1-4] approaching or exceeding internally defined limit(...";
CM_ SG_ 2566600190 MtGt6IvtPwLtddtMtTpt "Motor/Generator 6 Inverter Power Limited due to Motor Temperature: Output power is being limited due to one or more motor temperature(s), see SPNs 12156 and 12225 through 12227 [Motor Temperature 1-4] approaching or exceeding internally defined limit...";
CM_ SG_ 2566600190 MtGt6IvtPwLtdDtFtCdt "Motor/Generator 6 Inverter Power Limited Due to Fault Condition: Output power is being limited due to an fault condition that requires a torque limitation to prevent further damage (e.g. “limp home mode”).  For example, this could be in case of tempe...";
CM_ SG_ 2566600190 MtGt6IvtPwLtdDtAtvTqRtLt "Motor/Generator 6 Inverter Power Limited Due to Active Torque Rate Limit: Output power is being limited due to exceeding internally defined torque rate limit(s) or SPN 12261 [Inverter Rate Limits Request Absolute Torque Rate Limit].00b = No power lim...";
CM_ SG_ 2566600190 MtGt6IvtPwLtdDtAtvSpdRtLt "Motor/Generator 6 Inverter Power Limited Due to Active Speed Rate Limit: Output power is being limited due to exceeding internally defined speed rate limit(s) or SPN 12260 [Inverter Rate Limits Request Absolute Speed Rate Limit].00b = No power limit ...";
CM_ SG_ 2566600190 MtGt6IvtTqLtdDtMCtsts "Motor/Generator 6 Inverter Torque Limited Due to Machine Characteristics: Output torque is being limited due to SPN 12157 [Torque] approaching or exceeding a motor design characteristic.  For example, for permanent magnet machines, this would be in t...";
CM_ BO_ 2365273854 "Motor/Generator 5 Inverter Reference 1";
CM_ SG_ 2365273854 MtrGnrtr5InvrtrRfrn1CRC "Motor/Generator 5 Inverter Reference 1 CRC: The CRC is defined as follows:• Length: 8 bits• Polynomial: x^8+x^5+x^3+x^2+x+1• Initial Value: FFh• Input Data Reflection: Not reflected• Result Data Reflection: Not reflected• XOR value: FFhSAE makes no c...";
CM_ SG_ 2365273854 MtrGnrtr5InvrtrRfrn1Cntr "Motor/Generator 5 Inverter Reference 1 Counter: The message counter is used to detect situations where the transmitting ECU malfunction repeats the same frame all the time. The receiver of the information may use the counter parameter to detect this ...";
CM_ SG_ 2365273854 MtrGnrtr5InvrtrRfrnTrq "Motor/Generator 5 Inverter Reference Torque: This value is used for converting torque in percent to units of Nm.Value in Nm = (Percent Value)/(100%) * (Reference Torque)For example, if this parameter has a value of 400 Nm and the percent value is equ...";
CM_ SG_ 2365273854 MtrGnrtr5InvrtrRfrnSpd "Motor/Generator 5 Inverter Reference Speed: This value is used for converting Speed in percent to units of rpm.Value in rpm = (Percent Value)/(100%) * (Reference Speed)For example, if this parameter has a value of 8192 rpm and the percent value is eq...";
CM_ SG_ 2365273854 MtrGnrtr5InvrtrRfrnPwr "Motor/Generator 5 Inverter Reference Power: This value is used for converting power in percent to units of kW.  It is applicable to both mechanical and electrical power.(Value in kW) = (Percent Value)/(100%) * (Reference Power)For example, if this pa...";
CM_ BO_ 2365274110 "Motor/Generator 5 Inverter Status 1";
CM_ SG_ 2365274110 MtrGnrtr5InvrtrStts1CRC "Motor/Generator 5 Inverter Status 1 CRC: The CRC is defined as follows:• Length: 8 bits• Polynomial: x^8+x^5+x^3+x^2+x+1• Initial Value: FFh• Input Data Reflection: Not reflected• Result Data Reflection: Not reflected• XOR value: FFhSAE makes no clai...";
CM_ SG_ 2365274110 MtrGnrtr5InvrtrStts1Cntr "Motor/Generator 5 Inverter Status 1 Counter: The message counter is used to detect situations where the transmitting ECU malfunction repeats the same frame all the time. The receiver of the information may use the counter parameter to detect this sit...";
CM_ SG_ 2365274110 MotorGenerator5Torque "Motor/Generator 5 Torque: The measured or estimated motor torque.  This refers to the motor rotor output and excludes any gearbox that may be attached to the motor.Refer to SPN 12057 [Reference Torque] to convert % to Nm.The motor is generating when ...";
CM_ SG_ 2365274110 MotorGenerator5Speed "Motor/Generator 5 Speed: The measured or estimated motor speed.  This refers to the motor rotor output and excludes any gearbox that may be attached to the motor.   Refer to SPN 12058 [Reference Speed] to convert % to rpm.";
CM_ SG_ 2365274110 MtrGnrtr5InvrtrDCSdCrrnt "Motor/Generator 5 Inverter DC Side Current: This is the DC side current of the inverter.Refer to SPN 12089 [Reference Current] to convert % to Amps.While motoring, the current is defined as positive.  For example, in a hybrid propulsion system, posit...";
CM_ SG_ 2365274110 MtrGnrtr5InvrtrDCSdVltg "Motor/Generator 5 Inverter DC Side Voltage: The measured or estimated DC side voltage.  Refer to SPN 12090 [Reference Voltage] to convert % to Volts.";
CM_ BO_ 2365274366 "Motor/Generator 5 Inverter Reference 2";
CM_ SG_ 2365274366 MtrGnrtr5InvrtrRfrn2CRC "Motor/Generator 5 Inverter Reference 2 CRC: The CRC is defined as follows:• Length: 8 bits• Polynomial: x^8+x^5+x^3+x^2+x+1• Initial Value: FFh• Input Data Reflection: Not reflected• Result Data Reflection: Not reflected• XOR value: FFhSAE makes no c...";
CM_ SG_ 2365274366 MtrGnrtr5InvrtrRfrn2Cntr "Motor/Generator 5 Inverter Reference 2 Counter: The message counter is used to detect situations where the transmitting ECU malfunction repeats the same frame all the time. The receiver of the information may use the counter parameter to detect this ...";
CM_ SG_ 2365274366 MtrGnrtr5InvrtrRfrnCrrnt "Motor/Generator 5 Inverter Reference Current: This value is used for converting inverter current in percent to units of Amps (RMS or DC).(Value in Amps) = (Percent Value)/(100%) * (Reference Current)For example, if this parameter has a value of 200 A...";
CM_ SG_ 2365274366 MtrGnrtr5InvrtrRfrnVltg "Motor/Generator 5 Inverter Reference Voltage: This value is used for converting inverter voltage in percent to units of Volts (RMS or DC).(Value in Volts) = (Percent Value)/(100%) * (Reference Voltage)For example, if this parameter has a value of 400...";
CM_ BO_ 2566601214 "Motor/Generator 5 Inverter Temperature";
CM_ SG_ 2566601214 MtrGnrtr5InvrtrTmprtr1 "Motor/Generator 5 Inverter Temperature 1: The exact location of this temperature can be defined by the manufacturer.  It is intended to be located somewhere on the inverter. ";
CM_ SG_ 2566601214 MtrGnrtr5InvrtrTmprtr2 "Motor/Generator 5 Inverter Temperature 2: The exact location of this temperature can be defined by the manufacturer.  It is intended to be located somewhere on the inverter. ";
CM_ SG_ 2566601214 MtrGnrtr5InvrtrTmprtr3 "Motor/Generator 5 Inverter Temperature 3: The exact location of this temperature can be defined by the manufacturer.  It is intended to be located somewhere on the inverter. ";
CM_ SG_ 2566601214 MtrGnrtr5InvrtrTmprtr4 "Motor/Generator 5 Inverter Temperature 4: The exact location of this temperature can be defined by the manufacturer.  It is intended to be located somewhere on the inverter. ";
CM_ BO_ 2566601470 "Motor/Generator 5 Inverter Motor Temperature";
CM_ SG_ 2566601470 MotorGenerator5Temperature1 "Motor/Generator 5 Temperature 1: The exact location of this temperature can be defined by the manufacturer.  It is intended to located somewhere on the motor.";
CM_ SG_ 2566601470 MotorGenerator5Temperature2 "Motor/Generator 5 Temperature 2: The exact location of this temperature can be defined by the manufacturer.  It is intended to located somewhere on the motor. ";
CM_ SG_ 2566601470 MotorGenerator5Temperature3 "Motor/Generator 5 Temperature 3: The exact location of this temperature can be defined by the manufacturer.  It is intended to located somewhere on the motor. ";
CM_ SG_ 2566601470 MotorGenerator5Temperature4 "Motor/Generator 5 Temperature 4: The exact location of this temperature can be defined by the manufacturer.  It is intended to located somewhere on the motor. ";
CM_ BO_ 2566601726 "Motor/Generator 5 Inverter Isolation Integrity";
CM_ SG_ 2566601726 MtrGnrtr5InvrtrIsltnIntgrtCRC "Motor/Generator 5 Inverter Isolation Integrity CRC: The CRC is defined as follows:• Length: 8 bits• Polynomial: x^8+x^5+x^3+x^2+x+1• Initial Value: FFh• Input Data Reflection: Not reflected• Result Data Reflection: Not reflected• XOR value: FFhSAE ma...";
CM_ SG_ 2566601726 MtrGnrtr5InvrtrIsltnIntgrtCntr "Motor/Generator 5 Inverter Isolation Integrity Counter: The message counter is used to detect situations where the transmitting ECU malfunction repeats the same frame all the time. The receiver of the information may use the counter parameter to dete...";
CM_ SG_ 2566601726 MtGt5IvtDCSdNtvtCsssGdVt "Motor/Generator 5 Inverter DC Side Negative to Chassis Ground Voltage: The voltage level of the high voltage DC side, as measured by the inverter between the negative side of the High Voltage DC Side input and the chassis of the inverter enclosure.  ...";
CM_ SG_ 2566601726 MtGt5IvtHVtBsAtvIstTstStts "Motor/Generator 5 Inverter High-Voltage Bus Active Isolation Test Status: Status of the high-voltage bus electrical active isolation test as performed by this instance of the Motor/Generator.0000b = No test requested / No test in process0001b = Test ...";
CM_ SG_ 2566601726 MtGt5IvtHVtBsPssvIstTstStts "Motor/Generator 5 Inverter High-Voltage Bus Passive Isolation Test Status: Status of the high-voltage bus electrical passive isolation test as performed by this instance of the Motor/Generator.0000b = No test requested / No test in process0001b = Tes...";
CM_ SG_ 2566601726 MtGt5IvtHVtBsAtvIstTstRsts "Motor/Generator 5 Inverter High-Voltage Bus Active Isolation Test Results: The isolation resistance that resulted from the High-Voltage Bus Active Isolation Test.See SPN 12121 [High-Voltage Bus Active Isolation Test Status] for test status and SPN 12...";
CM_ SG_ 2566601726 MtGt5IvtHVtBsPssvIstTstRsts "Motor/Generator 5 Inverter High-Voltage Bus Passive Isolation Test Results: The isolation resistance that resulted from the High-Voltage Bus Passive Isolation Test.See SPN 12122 [High-Voltage Bus Passive Isolation Test Status] for test status and SPN...";
CM_ BO_ 2566601982 "Motor/Generator 5 Inverter Active Power Limits";
CM_ SG_ 2566601982 MtGt5IvtPwLtddtUddRs "Motor/Generator 5 Inverter Power Limited due to Undefined Reason: Output power is being limited due to an undefined reason.00b = No power limit for this reason01b = Power limited for this reason10b = Error11b = Not Available";
CM_ SG_ 2566601982 MtGt5IvtPwLtddtDCSdCtMx "Motor/Generator 5 Inverter Power Limited due to DC Side Current Maximum: Output power is being limited due to SPN 12062 [Inverter DC Side Current] approaching or exceeding the SPN 12101 [Inverter Limits Active DC Side Current Maximum].00b = No power ...";
CM_ SG_ 2566601982 MtGt5IvtPwLtddtDCSdCtM "Motor/Generator 5 Inverter Power Limited due to DC Side Current Minimum: Output power is being limited due to SPN 12062 [Inverter DC Side Current] approaching or falling below the SPN 12102 [Inverter Limits Active DC Side Current Minimum].00b = No po...";
CM_ SG_ 2566601982 MtGt5IvtPwLtddtDCSdVtMx "Motor/Generator 5 Inverter Power Limited due to DC Side Voltage Maximum: Output power is being limited due to SPN 12040 [Inverter DC Side Voltage] approaching or exceeding the SPN 12099 [Inverter Limits Active DC Side Voltage Maximum].00b = No power ...";
CM_ SG_ 2566601982 MtGt5IvtPwLtddtDCSdVtM "Motor/Generator 5 Inverter Power Limited due to DC Side Voltage Minimum: Output power is being limited due to SPN 12040 [Inverter DC Side Voltage] approaching or falling below the SPN 12100 [Inverter Limits Active DC Side Voltage Minimum].00b = No po...";
CM_ SG_ 2566601982 MtGt5IvtPwLtddtMPwMx "Motor/Generator 5 Inverter Power Limited due to Mechanical Power Maximum: Output power is being limited due to Mechanical Power (product of SPN 12039 [Torque] and SPN 12037 [Speed]) approaching or exceeding the SPN 12071 [Inverter Limits Active Mecha...";
CM_ SG_ 2566601982 MtGt5IvtPwLtddtMPwM "Motor/Generator 5 Inverter Power Limited due to Mechanical Power Minimum: Output power is being limited due to Mechanical Power (product of SPN 12039 [Torque] and SPN 12037 [Speed]) approaching or falling below the SPN 12072 [Inverter Limits Active M...";
CM_ SG_ 2566601982 MtGt5IvtPwLtddtDCSdPwMx "Motor/Generator 5 Inverter Power Limited due to DC Side Power Maximum: Output power is being limited due to DC Side Power (product of SPN 12062 [Inverter DC Side Current] and SPN 12040 [Inverter DC Side Voltage]) approaching or exceeding the SPN 1207...";
CM_ SG_ 2566601982 MtGt5IvtPwLtddtDCSdPwM "Motor/Generator 5 Inverter Power Limited due to DC Side Power Minimum: Output power is being limited due to DC Side Power (product of SPN 12062 [Inverter DC Side Current] and SPN 12040 [Inverter DC Side Voltage]) approaching or falling below the SPN ...";
CM_ SG_ 2566601982 MtrGnrtr5InvrtrPwrLmtddtTrqMxmm "Motor/Generator 5 Inverter Power Limited due to Torque Maximum: Output power is being limited due to SPN 12039 [Torque] approaching or exceeding the SPN 12083 [Inverter Limits Active Torque Maximum].00b = No power limit for this reason01b = Power lim...";
CM_ SG_ 2566601982 MtrGnrtr5InvrtrPwrLmtddtTrqMnmm "Motor/Generator 5 Inverter Power Limited due to Torque Minimum: Output power is being limited due to SPN 12039 [Torque] approaching or falling below the SPN 12084 [Inverter Limits Active Torque Minimum].00b = No power limit for this reason01b = Power...";
CM_ SG_ 2566601982 MtrGnrtr5InvrtrPwrLmtddtSpdMxmm "Motor/Generator 5 Inverter Power Limited due to Speed Maximum: Output power is being limited due to SPN 12037 [Speed] approaching or exceeding the SPN 12085 [Inverter Limits Active Speed Maximum].00b = No power limit for this reason01b = Power limite...";
CM_ SG_ 2566601982 MtrGnrtr5InvrtrPwrLmtddtSpdMnmm "Motor/Generator 5 Inverter Power Limited due to Speed Minimum: Output power is being limited due to SPN 12037 [Speed] approaching or falling below the SPN 12086 [Inverter Limits Active Speed Minimum].00b = No power limit for this reason01b = Power li...";
CM_ SG_ 2566601982 MtGt5IvtPwLtddtIvtTpt "Motor/Generator 5 Inverter Power Limited due to Inverter Temperature: Output power is being limited due to one or more inverter temperature(s), see SPNs 12103 through 12106 [Inverter Temperature 1-4] approaching or exceeding internally defined limit(...";
CM_ SG_ 2566601982 MtGt5IvtPwLtddtMtTpt "Motor/Generator 5 Inverter Power Limited due to Motor Temperature: Output power is being limited due to one or more motor temperature(s), see SPNs 12038 and 12107 through 12109 [Motor Temperature 1-4] approaching or exceeding internally defined limit...";
CM_ SG_ 2566601982 MtGt5IvtPwLtdDtFtCdt "Motor/Generator 5 Inverter Power Limited Due to Fault Condition: Output power is being limited due to an fault condition that requires a torque limitation to prevent further damage (e.g. “limp home mode”).  For example, this could be in case of tempe...";
CM_ SG_ 2566601982 MtGt5IvtPwLtdDtAtvTqRtLt "Motor/Generator 5 Inverter Power Limited Due to Active Torque Rate Limit: Output power is being limited due to exceeding internally defined torque rate limit(s) or SPN 12143 [Inverter Rate Limits Request Absolute Torque Rate Limit].00b = No power lim...";
CM_ SG_ 2566601982 MtGt5IvtPwLtdDtAtvSpdRtLt "Motor/Generator 5 Inverter Power Limited Due to Active Speed Rate Limit: Output power is being limited due to exceeding internally defined speed rate limit(s) or SPN 12142 [Inverter Rate Limits Request Absolute Speed Rate Limit].00b = No power limit ...";
CM_ SG_ 2566601982 MtGt5IvtTqLtdDtMCtsts "Motor/Generator 5 Inverter Torque Limited Due to Machine Characteristics: Output torque is being limited due to SPN 12039 [Torque] approaching or exceeding a motor design characteristic.  For example, for permanent magnet machines, this would be in t...";
CM_ BO_ 2365275646 "Motor/Generator 4 Inverter Reference 1";
CM_ SG_ 2365275646 MtrGnrtr4InvrtrRfrn1CRC "Motor/Generator 4 Inverter Reference 1 CRC: The CRC is defined as follows:• Length: 8 bits• Polynomial: x^8+x^5+x^3+x^2+x+1• Initial Value: FFh• Input Data Reflection: Not reflected• Result Data Reflection: Not reflected• XOR value: FFhSAE makes no c...";
CM_ SG_ 2365275646 MtrGnrtr4InvrtrRfrn1Cntr "Motor/Generator 4 Inverter Reference 1 Counter: The message counter is used to detect situations where the transmitting ECU malfunction repeats the same frame all the time. The receiver of the information may use the counter parameter to detect this ...";
CM_ SG_ 2365275646 MtrGnrtr4InvrtrRfrnTrq "Motor/Generator 4 Inverter Reference Torque: This value is used for converting torque in percent to units of Nm.Value in Nm = (Percent Value)/(100%) * (Reference Torque)For example, if this parameter has a value of 400 Nm and the percent value is equ...";
CM_ SG_ 2365275646 MtrGnrtr4InvrtrRfrnSpd "Motor/Generator 4 Inverter Reference Speed: This value is used for converting Speed in percent to units of rpm.Value in rpm = (Percent Value)/(100%) * (Reference Speed)For example, if this parameter has a value of 8192 rpm and the percent value is eq...";
CM_ SG_ 2365275646 MtrGnrtr4InvrtrRfrnPwr "Motor/Generator 4 Inverter Reference Power: This value is used for converting power in percent to units of kW.  It is applicable to both mechanical and electrical power.(Value in kW) = (Percent Value)/(100%) * (Reference Power)For example, if this pa...";
CM_ BO_ 2365275902 "Motor/Generator 4 Inverter Status 1";
CM_ SG_ 2365275902 MtrGnrtr4InvrtrStts1CRC "Motor/Generator 4 Inverter Status 1 CRC: The CRC is defined as follows:• Length: 8 bits• Polynomial: x^8+x^5+x^3+x^2+x+1• Initial Value: FFh• Input Data Reflection: Not reflected• Result Data Reflection: Not reflected• XOR value: FFhSAE makes no clai...";
CM_ SG_ 2365275902 MtrGnrtr4InvrtrStts1Cntr "Motor/Generator 4 Inverter Status 1 Counter: The message counter is used to detect situations where the transmitting ECU malfunction repeats the same frame all the time. The receiver of the information may use the counter parameter to detect this sit...";
CM_ SG_ 2365275902 MotorGenerator4Torque "Motor/Generator 4 Torque: The measured or estimated motor torque.  This refers to the motor rotor output and excludes any gearbox that may be attached to the motor.Refer to SPN 11939 [Reference Torque] to convert % to Nm.The motor is generating when ...";
CM_ SG_ 2365275902 MotorGenerator4Speed "Motor/Generator 4 Speed: The measured or estimated motor speed.  This refers to the motor rotor output and excludes any gearbox that may be attached to the motor.   Refer to SPN 11940 [Reference Speed] to convert % to rpm.";
CM_ SG_ 2365275902 MtrGnrtr4InvrtrDCSdCrrnt "Motor/Generator 4 Inverter DC Side Current: This is the DC side current of the inverter.Refer to SPN 11971 [Reference Current] to convert % to Amps.While motoring, the current is defined as positive.  For example, in a hybrid propulsion system, posit...";
CM_ SG_ 2365275902 MtrGnrtr4InvrtrDCSdVltg "Motor/Generator 4 Inverter DC Side Voltage: The measured or estimated DC side voltage.  Refer to SPN 11972 [Reference Voltage] to convert % to Volts.";
CM_ BO_ 2365276158 "Motor/Generator 4 Inverter Reference 2";
CM_ SG_ 2365276158 MtrGnrtr4InvrtrRfrn2CRC "Motor/Generator 4 Inverter Reference 2 CRC: The CRC is defined as follows:• Length: 8 bits• Polynomial: x^8+x^5+x^3+x^2+x+1• Initial Value: FFh• Input Data Reflection: Not reflected• Result Data Reflection: Not reflected• XOR value: FFhSAE makes no c...";
CM_ SG_ 2365276158 MtrGnrtr4InvrtrRfrn2Cntr "Motor/Generator 4 Inverter Reference 2 Counter: The message counter is used to detect situations where the transmitting ECU malfunction repeats the same frame all the time. The receiver of the information may use the counter parameter to detect this ...";
CM_ SG_ 2365276158 MtrGnrtr4InvrtrRfrnCrrnt "Motor/Generator 4 Inverter Reference Current: This value is used for converting inverter current in percent to units of Amps (RMS or DC).(Value in Amps) = (Percent Value)/(100%) * (Reference Current)For example, if this parameter has a value of 200 A...";
CM_ SG_ 2365276158 MtrGnrtr4InvrtrRfrnVltg "Motor/Generator 4 Inverter Reference Voltage: This value is used for converting inverter voltage in percent to units of Volts (RMS or DC).(Value in Volts) = (Percent Value)/(100%) * (Reference Voltage)For example, if this parameter has a value of 400...";
CM_ BO_ 2566603006 "Motor/Generator 4 Inverter Temperature";
CM_ SG_ 2566603006 MtrGnrtr4InvrtrTmprtr1 "Motor/Generator 4 Inverter Temperature 1: The exact location of this temperature can be defined by the manufacturer.  It is intended to be located somewhere on the inverter. ";
CM_ SG_ 2566603006 MtrGnrtr4InvrtrTmprtr2 "Motor/Generator 4 Inverter Temperature 2: The exact location of this temperature can be defined by the manufacturer.  It is intended to be located somewhere on the inverter. ";
CM_ SG_ 2566603006 MtrGnrtr4InvrtrTmprtr3 "Motor/Generator 4 Inverter Temperature 3: The exact location of this temperature can be defined by the manufacturer.  It is intended to be located somewhere on the inverter. ";
CM_ SG_ 2566603006 MtrGnrtr4InvrtrTmprtr4 "Motor/Generator 4 Inverter Temperature 4: The exact location of this temperature can be defined by the manufacturer.  It is intended to be located somewhere on the inverter. ";
CM_ BO_ 2566603262 "Motor/Generator 4 Inverter Motor Temperature";
CM_ SG_ 2566603262 MotorGenerator4Temperature1 "Motor/Generator 4 Temperature 1: The exact location of this temperature can be defined by the manufacturer.  It is intended to located somewhere on the motor.";
CM_ SG_ 2566603262 MotorGenerator4Temperature2 "Motor/Generator 4 Temperature 2: The exact location of this temperature can be defined by the manufacturer.  It is intended to located somewhere on the motor. ";
CM_ SG_ 2566603262 MotorGenerator4Temperature3 "Motor/Generator 4 Temperature 3: The exact location of this temperature can be defined by the manufacturer.  It is intended to located somewhere on the motor. ";
CM_ SG_ 2566603262 MotorGenerator4Temperature4 "Motor/Generator 4 Temperature 4: The exact location of this temperature can be defined by the manufacturer.  It is intended to located somewhere on the motor. ";
CM_ BO_ 2566603518 "Motor/Generator 4 Inverter Isolation Integrity";
CM_ SG_ 2566603518 MtrGnrtr4InvrtrIsltnIntgrtCRC "Motor/Generator 4 Inverter Isolation Integrity CRC: The CRC is defined as follows:• Length: 8 bits• Polynomial: x^8+x^5+x^3+x^2+x+1• Initial Value: FFh• Input Data Reflection: Not reflected• Result Data Reflection: Not reflected• XOR value: FFhSAE ma...";
CM_ SG_ 2566603518 MtrGnrtr4InvrtrIsltnIntgrtCntr "Motor/Generator 4 Inverter Isolation Integrity Counter: The message counter is used to detect situations where the transmitting ECU malfunction repeats the same frame all the time. The receiver of the information may use the counter parameter to dete...";
CM_ SG_ 2566603518 MtGt4IvtDCSdNtvtCsssGdVt "Motor/Generator 4 Inverter DC Side Negative to Chassis Ground Voltage: The voltage level of the high voltage DC side, as measured by the inverter between the negative side of the High Voltage DC Side input and the chassis of the inverter enclosure.  ...";
CM_ SG_ 2566603518 MtGt4IvtHVtBsAtvIstTstStts "Motor/Generator 4 Inverter High-Voltage Bus Active Isolation Test Status: Status of the high-voltage bus electrical active isolation test as performed by this instance of the Motor/Generator.0000b = No test requested / No test in process0001b = Test ...";
CM_ SG_ 2566603518 MtGt4IvtHVtBsPssvIstTstStts "Motor/Generator 4 Inverter High-Voltage Bus Passive Isolation Test Status: Status of the high-voltage bus electrical passive isolation test as performed by this instance of the Motor/Generator.0000b = No test requested / No test in process0001b = Tes...";
CM_ SG_ 2566603518 MtGt4IvtHVtBsAtvIstTstRsts "Motor/Generator 4 Inverter High-Voltage Bus Active Isolation Test Results: The isolation resistance that resulted from the High-Voltage Bus Active Isolation Test.See SPN 12003 [High-Voltage Bus Active Isolation Test Status] for test status and SPN 11...";
CM_ SG_ 2566603518 MtGt4IvtHVtBsPssvIstTstRsts "Motor/Generator 4 Inverter High-Voltage Bus Passive Isolation Test Results: The isolation resistance that resulted from the High-Voltage Bus Passive Isolation Test.See SPN 12004 [High-Voltage Bus Passive Isolation Test Status] for test status and SPN...";
CM_ BO_ 2566603774 "Motor/Generator 4 Inverter Active Power Limits";
CM_ SG_ 2566603774 MtGt4IvtPwLtddtUddRs "Motor/Generator 4 Inverter Power Limited due to Undefined Reason: Output power is being limited due to an undefined reason.00b = No power limit for this reason01b = Power limited for this reason10b = Error11b = Not Available";
CM_ SG_ 2566603774 MtGt4IvtPwLtddtDCSdCtMx "Motor/Generator 4 Inverter Power Limited due to DC Side Current Maximum: Output power is being limited due to SPN 11944 [Inverter DC Side Current] approaching or exceeding the SPN 11983 [Inverter Limits Active DC Side Current Maximum].00b = No power ...";
CM_ SG_ 2566603774 MtGt4IvtPwLtddtDCSdCtM "Motor/Generator 4 Inverter Power Limited due to DC Side Current Minimum: Output power is being limited due to SPN 11944 [Inverter DC Side Current] approaching or falling below the SPN 11984 [Inverter Limits Active DC Side Current Minimum].00b = No po...";
CM_ SG_ 2566603774 MtGt4IvtPwLtddtDCSdVtMx "Motor/Generator 4 Inverter Power Limited due to DC Side Voltage Maximum: Output power is being limited due to SPN 11922 [Inverter DC Side Voltage] approaching or exceeding the SPN 11981 [Inverter Limits Active DC Side Voltage Maximum].00b = No power ...";
CM_ SG_ 2566603774 MtGt4IvtPwLtddtDCSdVtM "Motor/Generator 4 Inverter Power Limited due to DC Side Voltage Minimum: Output power is being limited due to SPN 11922 [Inverter DC Side Voltage] approaching or falling below the SPN 11982 [Inverter Limits Active DC Side Voltage Minimum].00b = No po...";
CM_ SG_ 2566603774 MtGt4IvtPwLtddtMPwMx "Motor/Generator 4 Inverter Power Limited due to Mechanical Power Maximum: Output power is being limited due to Mechanical Power (product of SPN 11921 [Torque] and SPN 11919 [Speed]) approaching or exceeding the SPN 11953 [Inverter Limits Active Mecha...";
CM_ SG_ 2566603774 MtGt4IvtPwLtddtMPwM "Motor/Generator 4 Inverter Power Limited due to Mechanical Power Minimum: Output power is being limited due to Mechanical Power (product of SPN 11921 [Torque] and SPN 11919 [Speed]) approaching or falling below the SPN 11954 [Inverter Limits Active M...";
CM_ SG_ 2566603774 MtGt4IvtPwLtddtDCSdPwMx "Motor/Generator 4 Inverter Power Limited due to DC Side Power Maximum: Output power is being limited due to DC Side Power (product of SPN 11944 [Inverter DC Side Current] and SPN 11922 [Inverter DC Side Voltage]) approaching or exceeding the SPN 1195...";
CM_ SG_ 2566603774 MtGt4IvtPwLtddtDCSdPwM "Motor/Generator 4 Inverter Power Limited due to DC Side Power Minimum: Output power is being limited due to DC Side Power (product of SPN 11944 [Inverter DC Side Current] and SPN 11922 [Inverter DC Side Voltage]) approaching or falling below the SPN ...";
CM_ SG_ 2566603774 MtrGnrtr4InvrtrPwrLmtddtTrqMxmm "Motor/Generator 4 Inverter Power Limited due to Torque Maximum: Output power is being limited due to SPN 11921 [Torque] approaching or exceeding the SPN 11965 [Inverter Limits Active Torque Maximum].00b = No power limit for this reason01b = Power lim...";
CM_ SG_ 2566603774 MtrGnrtr4InvrtrPwrLmtddtTrqMnmm "Motor/Generator 4 Inverter Power Limited due to Torque Minimum: Output power is being limited due to SPN 11921 [Torque] approaching or falling below the SPN 11966 [Inverter Limits Active Torque Minimum].00b = No power limit for this reason01b = Power...";
CM_ SG_ 2566603774 MtrGnrtr4InvrtrPwrLmtddtSpdMxmm "Motor/Generator 4 Inverter Power Limited due to Speed Maximum: Output power is being limited due to SPN 11919 [Speed] approaching or exceeding the SPN 11967 [Inverter Limits Active Speed Maximum].00b = No power limit for this reason01b = Power limite...";
CM_ SG_ 2566603774 MtrGnrtr4InvrtrPwrLmtddtSpdMnmm "Motor/Generator 4 Inverter Power Limited due to Speed Minimum: Output power is being limited due to SPN 11919 [Speed] approaching or falling below the SPN 11968 [Inverter Limits Active Speed Minimum].00b = No power limit for this reason01b = Power li...";
CM_ SG_ 2566603774 MtGt4IvtPwLtddtIvtTpt "Motor/Generator 4 Inverter Power Limited due to Inverter Temperature: Output power is being limited due to one or more inverter temperature(s), see SPNs 11985 through 11988 [Inverter Temperature 1-4] approaching or exceeding internally defined limit(...";
CM_ SG_ 2566603774 MtGt4IvtPwLtddtMtTpt "Motor/Generator 4 Inverter Power Limited due to Motor Temperature: Output power is being limited due to one or more motor temperature(s), see SPNs 11920 and 11989 through 11991 [Motor Temperature 1-4] approaching or exceeding internally defined limit...";
CM_ SG_ 2566603774 MtGt4IvtPwLtdDtFtCdt "Motor/Generator 4 Inverter Power Limited Due to Fault Condition: Output power is being limited due to an fault condition that requires a torque limitation to prevent further damage (e.g. “limp home mode”).  For example, this could be in case of tempe...";
CM_ SG_ 2566603774 MtGt4IvtPwLtdDtAtvTqRtLt "Motor/Generator 4 Inverter Power Limited Due to Active Torque Rate Limit: Output power is being limited due to exceeding internally defined torque rate limit(s) or SPN 12025 [Inverter Rate Limits Request Absolute Torque Rate Limit].00b = No power lim...";
CM_ SG_ 2566603774 MtGt4IvtPwLtdDtAtvSpdRtLt "Motor/Generator 4 Inverter Power Limited Due to Active Speed Rate Limit: Output power is being limited due to exceeding internally defined speed rate limit(s) or SPN 12024 [Inverter Rate Limits Request Absolute Speed Rate Limit].00b = No power limit ...";
CM_ SG_ 2566603774 MtGt4IvtTqLtdDtMCtsts "Motor/Generator 4 Inverter Torque Limited Due to Machine Characteristics: Output torque is being limited due to SPN 11921 [Torque] approaching or exceeding a motor design characteristic.  For example, for permanent magnet machines, this would be in t...";
CM_ BO_ 2365277438 "Motor/Generator 3 Inverter Reference 1";
CM_ SG_ 2365277438 MtrGnrtr3InvrtrRfrn1CRC "Motor/Generator 3 Inverter Reference 1 CRC: The CRC is defined as follows:• Length: 8 bits• Polynomial: x^8+x^5+x^3+x^2+x+1• Initial Value: FFh• Input Data Reflection: Not reflected• Result Data Reflection: Not reflected• XOR value: FFhSAE makes no c...";
CM_ SG_ 2365277438 MtrGnrtr3InvrtrRfrn1Cntr "Motor/Generator 3 Inverter Reference 1 Counter: The message counter is used to detect situations where the transmitting ECU malfunction repeats the same frame all the time. The receiver of the information may use the counter parameter to detect this ...";
CM_ SG_ 2365277438 MtrGnrtr3InvrtrRfrnTrq "Motor/Generator 3 Inverter Reference Torque: This value is used for converting torque in percent to units of Nm.Value in Nm = (Percent Value)/(100%) * (Reference Torque)For example, if this parameter has a value of 400 Nm and the percent value is equ...";
CM_ SG_ 2365277438 MtrGnrtr3InvrtrRfrnSpd "Motor/Generator 3 Inverter Reference Speed: This value is used for converting Speed in percent to units of rpm.Value in rpm = (Percent Value)/(100%) * (Reference Speed)For example, if this parameter has a value of 8192 rpm and the percent value is eq...";
CM_ SG_ 2365277438 MtrGnrtr3InvrtrRfrnPwr "Motor/Generator 3 Inverter Reference Power: This value is used for converting power in percent to units of kW.  It is applicable to both mechanical and electrical power.(Value in kW) = (Percent Value)/(100%) * (Reference Power)For example, if this pa...";
CM_ BO_ 2365277694 "Motor/Generator 3 Inverter Status 1";
CM_ SG_ 2365277694 MtrGnrtr3InvrtrStts1CRC "Motor/Generator 3 Inverter Status 1 CRC: The CRC is defined as follows:• Length: 8 bits• Polynomial: x^8+x^5+x^3+x^2+x+1• Initial Value: FFh• Input Data Reflection: Not reflected• Result Data Reflection: Not reflected• XOR value: FFhSAE makes no clai...";
CM_ SG_ 2365277694 MtrGnrtr3InvrtrStts1Cntr "Motor/Generator 3 Inverter Status 1 Counter: The message counter is used to detect situations where the transmitting ECU malfunction repeats the same frame all the time. The receiver of the information may use the counter parameter to detect this sit...";
CM_ SG_ 2365277694 MotorGenerator3Torque "Motor/Generator 3 Torque: The measured or estimated motor torque.  This refers to the motor rotor output and excludes any gearbox that may be attached to the motor.Refer to SPN 11821 [Reference Torque] to convert % to Nm.The motor is generating when ...";
CM_ SG_ 2365277694 MotorGenerator3Speed "Motor/Generator 3 Speed: The measured or estimated motor speed.  This refers to the motor rotor output and excludes any gearbox that may be attached to the motor.   Refer to SPN 11822 [Reference Speed] to convert % to rpm.";
CM_ SG_ 2365277694 MtrGnrtr3InvrtrDCSdCrrnt "Motor/Generator 3 Inverter DC Side Current: This is the DC side current of the inverter.Refer to SPN 11853 [Reference Current] to convert % to Amps.While motoring, the current is defined as positive.  For example, in a hybrid propulsion system, posit...";
CM_ SG_ 2365277694 MtrGnrtr3InvrtrDCSdVltg "Motor/Generator 3 Inverter DC Side Voltage: The measured or estimated DC side voltage.  Refer to SPN 11854 [Reference Voltage] to convert % to Volts.";
CM_ BO_ 2365277950 "Motor/Generator 3 Inverter Reference 2";
CM_ SG_ 2365277950 MtrGnrtr3InvrtrRfrn2CRC "Motor/Generator 3 Inverter Reference 2 CRC: The CRC is defined as follows:• Length: 8 bits• Polynomial: x^8+x^5+x^3+x^2+x+1• Initial Value: FFh• Input Data Reflection: Not reflected• Result Data Reflection: Not reflected• XOR value: FFhSAE makes no c...";
CM_ SG_ 2365277950 MtrGnrtr3InvrtrRfrn2Cntr "Motor/Generator 3 Inverter Reference 2 Counter: The message counter is used to detect situations where the transmitting ECU malfunction repeats the same frame all the time. The receiver of the information may use the counter parameter to detect this ...";
CM_ SG_ 2365277950 MtrGnrtr3InvrtrRfrnCrrnt "Motor/Generator 3 Inverter Reference Current: This value is used for converting inverter current in percent to units of Amps (RMS or DC).(Value in Amps) = (Percent Value)/(100%) * (Reference Current)For example, if this parameter has a value of 200 A...";
CM_ SG_ 2365277950 MtrGnrtr3InvrtrRfrnVltg "Motor/Generator 3 Inverter Reference Voltage: This value is used for converting inverter voltage in percent to units of Volts (RMS or DC).(Value in Volts) = (Percent Value)/(100%) * (Reference Voltage)For example, if this parameter has a value of 400...";
CM_ BO_ 2566604798 "Motor/Generator 3 Inverter Temperature";
CM_ SG_ 2566604798 MtrGnrtr3InvrtrTmprtr1 "Motor/Generator 3 Inverter Temperature 1: The exact location of this temperature can be defined by the manufacturer.  It is intended to be located somewhere on the inverter. ";
CM_ SG_ 2566604798 MtrGnrtr3InvrtrTmprtr2 "Motor/Generator 3 Inverter Temperature 2: The exact location of this temperature can be defined by the manufacturer.  It is intended to be located somewhere on the inverter. ";
CM_ SG_ 2566604798 MtrGnrtr3InvrtrTmprtr3 "Motor/Generator 3 Inverter Temperature 3: The exact location of this temperature can be defined by the manufacturer.  It is intended to be located somewhere on the inverter. ";
CM_ SG_ 2566604798 MtrGnrtr3InvrtrTmprtr4 "Motor/Generator 3 Inverter Temperature 4: The exact location of this temperature can be defined by the manufacturer.  It is intended to be located somewhere on the inverter. ";
CM_ BO_ 2566605054 "Motor/Generator 3 Inverter Motor Temperature";
CM_ SG_ 2566605054 MotorGenerator3Temperature1 "Motor/Generator 3 Temperature 1: The exact location of this temperature can be defined by the manufacturer.  It is intended to located somewhere on the motor.";
CM_ SG_ 2566605054 MotorGenerator3Temperature2 "Motor/Generator 3 Temperature 2: The exact location of this temperature can be defined by the manufacturer.  It is intended to located somewhere on the motor. ";
CM_ SG_ 2566605054 MotorGenerator3Temperature3 "Motor/Generator 3 Temperature 3: The exact location of this temperature can be defined by the manufacturer.  It is intended to located somewhere on the motor. ";
CM_ SG_ 2566605054 MotorGenerator3Temperature4 "Motor/Generator 3 Temperature 4: The exact location of this temperature can be defined by the manufacturer.  It is intended to located somewhere on the motor. ";
CM_ BO_ 2566605310 "Motor/Generator 3 Inverter Isolation Integrity";
CM_ SG_ 2566605310 MtrGnrtr3InvrtrIsltnIntgrtCRC "Motor/Generator 3 Inverter Isolation Integrity CRC: The CRC is defined as follows:• Length: 8 bits• Polynomial: x^8+x^5+x^3+x^2+x+1• Initial Value: FFh• Input Data Reflection: Not reflected• Result Data Reflection: Not reflected• XOR value: FFhSAE ma...";
CM_ SG_ 2566605310 MtrGnrtr3InvrtrIsltnIntgrtCntr "Motor/Generator 3 Inverter Isolation Integrity Counter: The message counter is used to detect situations where the transmitting ECU malfunction repeats the same frame all the time. The receiver of the information may use the counter parameter to dete...";
CM_ SG_ 2566605310 MtGt3IvtDCSdNtvtCsssGdVt "Motor/Generator 3 Inverter DC Side Negative to Chassis Ground Voltage: The voltage level of the high voltage DC side, as measured by the inverter between the negative side of the High Voltage DC Side input and the chassis of the inverter enclosure.  ...";
CM_ SG_ 2566605310 MtGt3IvtHVtBsAtvIstTstStts "Motor/Generator 3 Inverter High-Voltage Bus Active Isolation Test Status: Status of the high-voltage bus electrical active isolation test as performed by this instance of the Motor/Generator.0000b = No test requested / No test in process0001b = Test ...";
CM_ SG_ 2566605310 MtGt3IvtHVtBsPssvIstTstStts "Motor/Generator 3 Inverter High-Voltage Bus Passive Isolation Test Status: Status of the high-voltage bus electrical passive isolation test as performed by this instance of the Motor/Generator.0000b = No test requested / No test in process0001b = Tes...";
CM_ SG_ 2566605310 MtGt3IvtHVtBsAtvIstTstRsts "Motor/Generator 3 Inverter High-Voltage Bus Active Isolation Test Results: The isolation resistance that resulted from the High-Voltage Bus Active Isolation Test.See SPN 11885 [High-Voltage Bus Active Isolation Test Status] for test status and SPN 11...";
CM_ SG_ 2566605310 MtGt3IvtHVtBsPssvIstTstRsts "Motor/Generator 3 Inverter High-Voltage Bus Passive Isolation Test Results: The isolation resistance that resulted from the High-Voltage Bus Passive Isolation Test.See SPN 11886 [High-Voltage Bus Passive Isolation Test Status] for test status and SPN...";
CM_ BO_ 2566605566 "Motor/Generator 3 Inverter Active Power Limits";
CM_ SG_ 2566605566 MtGt3IvtPwLtddtUddRs "Motor/Generator 3 Inverter Power Limited due to Undefined Reason: Output power is being limited due to an undefined reason.00b = No power limit for this reason01b = Power limited for this reason10b = Error11b = Not Available";
CM_ SG_ 2566605566 MtGt3IvtPwLtddtDCSdCtMx "Motor/Generator 3 Inverter Power Limited due to DC Side Current Maximum: Output power is being limited due to SPN 11826 [Inverter DC Side Current] approaching or exceeding the SPN 11865 [Inverter Limits Active DC Side Current Maximum].00b = No power ...";
CM_ SG_ 2566605566 MtGt3IvtPwLtddtDCSdCtM "Motor/Generator 3 Inverter Power Limited due to DC Side Current Minimum: Output power is being limited due to SPN 11826 [Inverter DC Side Current] approaching or falling below the SPN 11866 [Inverter Limits Active DC Side Current Minimum].00b = No po...";
CM_ SG_ 2566605566 MtGt3IvtPwLtddtDCSdVtMx "Motor/Generator 3 Inverter Power Limited due to DC Side Voltage Maximum: Output power is being limited due to SPN 11804 [Inverter DC Side Voltage] approaching or exceeding the SPN 11863 [Inverter Limits Active DC Side Voltage Maximum].00b = No power ...";
CM_ SG_ 2566605566 MtGt3IvtPwLtddtDCSdVtM "Motor/Generator 3 Inverter Power Limited due to DC Side Voltage Minimum: Output power is being limited due to SPN 11804 [Inverter DC Side Voltage] approaching or falling below the SPN 11864 [Inverter Limits Active DC Side Voltage Minimum].00b = No po...";
CM_ SG_ 2566605566 MtGt3IvtPwLtddtMPwMx "Motor/Generator 3 Inverter Power Limited due to Mechanical Power Maximum: Output power is being limited due to Mechanical Power (product of SPN 11803 [Torque] and SPN 11801 [Speed]) approaching or exceeding the SPN 11835 [Inverter Limits Active Mecha...";
CM_ SG_ 2566605566 MtGt3IvtPwLtddtMPwM "Motor/Generator 3 Inverter Power Limited due to Mechanical Power Minimum: Output power is being limited due to Mechanical Power (product of SPN 11803 [Torque] and SPN 11801 [Speed]) approaching or falling below the SPN 11836 [Inverter Limits Active M...";
CM_ SG_ 2566605566 MtGt3IvtPwLtddtDCSdPwMx "Motor/Generator 3 Inverter Power Limited due to DC Side Power Maximum: Output power is being limited due to DC Side Power (product of SPN 11826 [Inverter DC Side Current] and SPN 11804 [Inverter DC Side Voltage]) approaching or exceeding the SPN 1183...";
CM_ SG_ 2566605566 MtGt3IvtPwLtddtDCSdPwM "Motor/Generator 3 Inverter Power Limited due to DC Side Power Minimum: Output power is being limited due to DC Side Power (product of SPN 11826 [Inverter DC Side Current] and SPN 11804 [Inverter DC Side Voltage]) approaching or falling below the SPN ...";
CM_ SG_ 2566605566 MtrGnrtr3InvrtrPwrLmtddtTrqMxmm "Motor/Generator 3 Inverter Power Limited due to Torque Maximum: Output power is being limited due to SPN 11803 [Torque] approaching or exceeding the SPN 11847 [Inverter Limits Active Torque Maximum].00b = No power limit for this reason01b = Power lim...";
CM_ SG_ 2566605566 MtrGnrtr3InvrtrPwrLmtddtTrqMnmm "Motor/Generator 3 Inverter Power Limited due to Torque Minimum: Output power is being limited due to SPN 11803 [Torque] approaching or falling below the SPN 11848 [Inverter Limits Active Torque Minimum].00b = No power limit for this reason01b = Power...";
CM_ SG_ 2566605566 MtrGnrtr3InvrtrPwrLmtddtSpdMxmm "Motor/Generator 3 Inverter Power Limited due to Speed Maximum: Output power is being limited due to SPN 11801 [Speed] approaching or exceeding the SPN 11849 [Inverter Limits Active Speed Maximum].00b = No power limit for this reason01b = Power limite...";
CM_ SG_ 2566605566 MtrGnrtr3InvrtrPwrLmtddtSpdMnmm "Motor/Generator 3 Inverter Power Limited due to Speed Minimum: Output power is being limited due to SPN 11801 [Speed] approaching or falling below the SPN 11850 [Inverter Limits Active Speed Minimum].00b = No power limit for this reason01b = Power li...";
CM_ SG_ 2566605566 MtGt3IvtPwLtddtIvtTpt "Motor/Generator 3 Inverter Power Limited due to Inverter Temperature: Output power is being limited due to one or more inverter temperature(s), see SPNs 11867 through 11870 [Inverter Temperature 1-4] approaching or exceeding internally defined limit(...";
CM_ SG_ 2566605566 MtGt3IvtPwLtddtMtTpt "Motor/Generator 3 Inverter Power Limited due to Motor Temperature: Output power is being limited due to one or more motor temperature(s), see SPNs 11802 and 11871 through 11873 [Motor Temperature 1-4] approaching or exceeding internally defined limit...";
CM_ SG_ 2566605566 MtGt3IvtPwLtdDtFtCdt "Motor/Generator 3 Inverter Power Limited Due to Fault Condition: Output power is being limited due to an fault condition that requires a torque limitation to prevent further damage (e.g. “limp home mode”).  For example, this could be in case of tempe...";
CM_ SG_ 2566605566 MtGt3IvtPwLtdDtAtvTqRtLt "Motor/Generator 3 Inverter Power Limited Due to Active Torque Rate Limit: Output power is being limited due to exceeding internally defined torque rate limit(s) or SPN 11907 [Inverter Rate Limits Request Absolute Torque Rate Limit].00b = No power lim...";
CM_ SG_ 2566605566 MtGt3IvtPwLtdDtAtvSpdRtLt "Motor/Generator 3 Inverter Power Limited Due to Active Speed Rate Limit: Output power is being limited due to exceeding internally defined speed rate limit(s) or SPN 11906 [Inverter Rate Limits Request Absolute Speed Rate Limit].00b = No power limit ...";
CM_ SG_ 2566605566 MtGt3IvtTqLtdDtMCtsts "Motor/Generator 3 Inverter Torque Limited Due to Machine Characteristics: Output torque is being limited due to SPN 11803 [Torque] approaching or exceeding a motor design characteristic.  For example, for permanent magnet machines, this would be in t...";
CM_ BO_ 2566605822 "Automated Driving System Feedback";
CM_ SG_ 2566605822 SAddssCtDvTSC1CtPpsP7 "Source Address of Controlling Device for TSC1 Control Purpose P7: The source address of the SAE J1939 device that is currently sending a TSC1 message with control purpose P7 that is actively controlling or limitting the power system output.254 (FEh) ...";
CM_ SG_ 2566605822 TSC1CntrlPrpsP7RdnssStts "TSC1 Control Purpose P7 Readiness Status: This parameter is used to indicate an application's state of readiness for responding to TSC1 Control Purpose P7 (see SPN 3350) messages.00b = Not Ready01b = Ready10b = Error11b = Not Available/Not Supported....";
CM_ BO_ 2566606078 "Cab Climate System Information 2";
CM_ SG_ 2566606078 CabHeaterPower "Cab Heater Power: Electrical power consumed by the cab heater.";
CM_ BO_ 2566606334 "Maintenance Information";
CM_ SG_ 2566606334 EngineAirFilter1LifeRemaining "Engine Air Filter 1 Life Remaining: Signal which indicates an actual life remaining in percent of the engine air filter #1. 0% represents no life remaining in the filter and 100% represents a new filter with full life remaining.";
CM_ SG_ 2566606334 EngineAirFilter2LifeRemaining "Engine Air Filter 2 Life Remaining: Signal which indicates an actual life remaining in percent of the engine air filter #2. 0% represents no life remaining in the filter and 100% represents a new filter with full life remaining.";
CM_ SG_ 2566606334 EngineAirFilter3LifeRemaining "Engine Air Filter 3 Life Remaining: Signal which indicates an actual life remaining in percent of the engine air filter #3. 0% represents no life remaining in the filter and 100% represents a new filter with full life remaining.";
CM_ SG_ 2566606334 EngineAirFilter4LifeRemaining "Engine Air Filter 4 Life Remaining: Signal which indicates an actual life remaining in percent of the engine air filter #4. 0% represents no life remaining in the filter and 100% represents a new filter with full life remaining.";
CM_ SG_ 2566606334 EngineFuelFilterLifeRemaining "Engine Fuel Filter Life Remaining: Signal which indicates an actual life remaining in percent of the engine fuel filter.  0% represents no life remaining in the filter and 100% represents a new filter with full life remaining.";
CM_ SG_ 2566606334 EngnFlFltrStnSdLfRmnng "Engine Fuel Filter (Suction Side) Life Remaining: Signal which indicates an actual life remaining in percent of the engine suction side fuel filter.  0% represents no life remaining in the filter and 100% represents a new filter with full life remain...";
CM_ SG_ 2566606334 EngineOilFilterLifeRemaining "Engine Oil Filter Life Remaining: Signal which indicates an actual life remaining in percent of the engine oil filter.  0% represents no life remaining in the filter and 100% represents a new filter with full life remaining.";
CM_ SG_ 2566606334 TrnsmssnOIlFltrLfRmnng "Transmission OIl Filter Life Remaining: Signal which indicates an actual life remaining in percent of the transmission oil filter.  0% represents no life remaining in the filter and 100% represents a new filter with full life remaining.";
CM_ BO_ 2499497726 "Hoist Control Information";
CM_ SG_ 2499497726 HoistLeverPosition "Hoist Lever Position: The position of the operator's hoist control lever (used for a dump body) relative to travel from a neutral (center) position.  Position value of 0 indicates the lever is in the neutral (central) position where no hoist movement...";
CM_ SG_ 2499497726 HoistLeverDetentPositionStatus "Hoist Lever Detent Position Status: The status of the hoist lever (used for a dump body) in the detent position for either direction of travel.  00b = Not in the Detent Position01b = In the Detent Position10b = Error Indicator11b = Not Available...";
CM_ BO_ 2633715710 "High Voltage Energy Storage Pack 6 History";
CM_ SG_ 2633715710 HVESP6StateofHealth "HVESP6 State of Health: This signal represents the expected remaining Life of this High Voltage Energy Storage Pack instance, in percent.  Battery life is a manufacturer-specific measure of how well the energy storage system is functioning relative t...";
CM_ SG_ 2633715710 HVESP6CnttrOpnUndrLdCnt "HVESP6 Contactor Open Under Load Count: This signal represents the number of times the contactors inside this High Voltage Energy Storage Pack instance have opened while current is flowing through them.  The current level (that determines if an openi...";
CM_ SG_ 2633715710 HVESP6TotalEnergyThroughput "HVESP6 Total Energy Throughput: The total energy throughput which has flowed through this High Voltage Energy Storage Pack instance.  This parameter is the sum of the absolute values of the Energy into and out of this HVES instance.  This parameter i...";
CM_ SG_ 2633715710 HVESP6TotalAccumulatedCharge "HVESP6 Total Accumulated Charge: The total accumulated amp hours which have flowed through this High Voltage Energy Storage Pack instance.  This parameter is the sum of the absolute values of the Ampere hours into and out of this HVES instance.  This...";
CM_ SG_ 2633715710 HVESP6TotalLifetimeEnergyInput "HVESP6 Total Lifetime Energy Input: The cumulative energy which has flowed into this High Voltage Energy Storage Pack instance over the lifetime of the battery pack. This parameter is the sum of the Energy into this HVES instance.  This value is rese...";
CM_ SG_ 2633715710 HVESP6TotalLifetimeEnergyOutput "HVESP6 Total Lifetime Energy Output: The cumulative energy which has flowed out of this High Voltage Energy Storage Pack instance over the lifetime of the battery pack. This parameter is the sum of the Energy out of this HVES instance. This value is ...";
CM_ BO_ 2566607102 "High Voltage Energy Storage Pack 6 Configuration";
CM_ SG_ 2566607102 HVESP6NominalVoltage "HVESP6 Nominal Voltage: Per the HVES manufacturer, this is the nominal operating voltage of this High Voltage Energy Storage Pack instance, e.g. “300V” or “600V”.This parameter is for one of multiple packs in an HVESS.  If there is only one pack in t...";
CM_ SG_ 2566607102 HVESP6RmmnddMnmmOprtngVltg "HVESP6 Recommended Minimum Operating Voltage: Per the HVES manufacturer, this is the minimum recommended voltage level for this High Voltage Energy Storage Pack instance operation.  Operating below this value may compromise HVES life.This parameter i...";
CM_ SG_ 2566607102 HVESP6RmmnddMxmmOprtngVltg "HVESP6 Recommended Maximum Operating Voltage: Per the HVES manufacturer, this is the maximum recommended voltage level for this High Voltage Energy Storage Pack instance operation.  Operating above this value may compromise HVES life.This parameter i...";
CM_ SG_ 2566607102 HVESP6RmmnddMnmmSttOfChrg "HVESP6 Recommended Minimum State Of Charge: Per the HVES manufacturer, this is the recommended minimum state of charge for this High Voltage Energy Storage Pack instance operation.  Operating below this value may compromise HVES life.This parameter i...";
CM_ SG_ 2566607102 HVESP6RmmnddMxmmSttOfChrg "HVESP6 Recommended Maximum State Of Charge: Per the HVES manufacturer, this is the recommended maximum state of charge for this High Voltage Energy Storage Pack instance operation.  Operating above this value may compromise HVES life.This parameter i...";
CM_ SG_ 2566607102 HVESP6RmmnddMxmmOprtngTmprtr "HVESP6 Recommended Maximum Operating Temperature: Per the HVES manufacturer, this is the recommended maximum temperature for this High Voltage Energy Storage Pack instance operation.  Operating above this value may damage HVES hardware, or compromise...";
CM_ SG_ 2566607102 HVESP6RmmnddMnmmOprtngTmprtr "HVESP6 Recommended Minimum Operating Temperature: Per the HVES manufacturer, this is the recommended minimum temperature for this High Voltage Energy Storage Pack instance operation.  Operating below this value may damage HVES hardware, or compromise...";
CM_ SG_ 2566607102 HVESP6CellMaximumVoltageLimit "HVESP6 Cell Maximum Voltage Limit: Per the HVES manufacturer, this is the maximum cell voltage for this High Voltage Energy Storage Pack instance operation.  Operating above this value may damage HVES hardware, or compromise HVES life.This parameter ...";
CM_ SG_ 2566607102 HVESP6CellMinimumVoltageLimit "HVESP6 Cell Minimum Voltage Limit: Per the HVES manufacturer, this is the minimum cell voltage for this High Voltage Energy Storage Pack instance operation.  Operating below this value may damage HVES hardware, or compromise HVES life.This parameter ...";
CM_ BO_ 2633716222 "High Voltage Energy Storage Pack 5 History";
CM_ SG_ 2633716222 HVESP5StateofHealth "HVESP5 State of Health: This signal represents the expected remaining Life of this High Voltage Energy Storage Pack instance, in percent.  Battery life is a manufacturer-specific measure of how well the energy storage system is functioning relative t...";
CM_ SG_ 2633716222 HVESP5CnttrOpnUndrLdCnt "HVESP5 Contactor Open Under Load Count: This signal represents the number of times the contactors inside this High Voltage Energy Storage Pack instance have opened while current is flowing through them.  The current level (that determines if an openi...";
CM_ SG_ 2633716222 HVESP5TotalEnergyThroughput "HVESP5 Total Energy Throughput: The total energy throughput which has flowed through this High Voltage Energy Storage Pack instance.  This parameter is the sum of the absolute values of the Energy into and out of this HVES instance.  This parameter i...";
CM_ SG_ 2633716222 HVESP5TotalAccumulatedCharge "HVESP5 Total Accumulated Charge: The total accumulated amp hours which have flowed through this High Voltage Energy Storage Pack instance.  This parameter is the sum of the absolute values of the Ampere hours into and out of this HVES instance.  This...";
CM_ SG_ 2633716222 HVESP5TotalLifetimeEnergyInput "HVESP5 Total Lifetime Energy Input: The cumulative energy which has flowed into this High Voltage Energy Storage Pack instance over the lifetime of the battery pack. This parameter is the sum of the Energy into this HVES instance. This value is reset...";
CM_ SG_ 2633716222 HVESP5TotalLifetimeEnergyOutput "HVESP5 Total Lifetime Energy Output: The cumulative energy which has flowed out of this High Voltage Energy Storage Pack instance over the lifetime of the battery pack. This parameter is the sum of the Energy out of this HVES instance. This value is ...";
CM_ BO_ 2566607614 "High Voltage Energy Storage Pack 5 Configuration";
CM_ SG_ 2566607614 HVESP5NominalVoltage "HVESP5 Nominal Voltage: Per the HVES manufacturer, this is the nominal operating voltage of this High Voltage Energy Storage Pack instance, e.g. “300V” or “600V”.This parameter is for one of multiple packs in an HVESS.  If there is only one pack in t...";
CM_ SG_ 2566607614 HVESP5RmmnddMnmmOprtngVltg "HVESP5 Recommended Minimum Operating Voltage: Per the HVES manufacturer, this is the minimum recommended voltage level for this High Voltage Energy Storage Pack instance operation.  Operating below this value may compromise HVES life.This parameter i...";
CM_ SG_ 2566607614 HVESP5RmmnddMxmmOprtngVltg "HVESP5 Recommended Maximum Operating Voltage: Per the HVES manufacturer, this is the maximum recommended voltage level for this High Voltage Energy Storage Pack instance operation.  Operating above this value may compromise HVES life.This parameter i...";
CM_ SG_ 2566607614 HVESP5RmmnddMnmmSttOfChrg "HVESP5 Recommended Minimum State Of Charge: Per the HVES manufacturer, this is the recommended minimum state of charge for this High Voltage Energy Storage Pack instance operation.  Operating below this value may compromise HVES life.This parameter i...";
CM_ SG_ 2566607614 HVESP5RmmnddMxmmSttOfChrg "HVESP5 Recommended Maximum State Of Charge: Per the HVES manufacturer, this is the recommended maximum state of charge for this High Voltage Energy Storage Pack instance operation.  Operating above this value may compromise HVES life.This parameter i...";
CM_ SG_ 2566607614 HVESP5RmmnddMxmmOprtngTmprtr "HVESP5 Recommended Maximum Operating Temperature: Per the HVES manufacturer, this is the recommended maximum temperature for this High Voltage Energy Storage Pack instance operation.  Operating above this value may damage HVES hardware, or compromise...";
CM_ SG_ 2566607614 HVESP5RmmnddMnmmOprtngTmprtr "HVESP5 Recommended Minimum Operating Temperature: Per the HVES manufacturer, this is the recommended minimum temperature for this High Voltage Energy Storage Pack instance operation.  Operating below this value may damage HVES hardware, or compromise...";
CM_ SG_ 2566607614 HVESP5CellMaximumVoltageLimit "HVESP5 Cell Maximum Voltage Limit: Per the HVES manufacturer, this is the maximum cell voltage for this High Voltage Energy Storage Pack instance operation.  Operating above this value may damage HVES hardware, or compromise HVES life.This parameter ...";
CM_ SG_ 2566607614 HVESP5CellMinimumVoltageLimit "HVESP5 Cell Minimum Voltage Limit: Per the HVES manufacturer, this is the minimum cell voltage for this High Voltage Energy Storage Pack instance operation.  Operating below this value may damage HVES hardware, or compromise HVES life.This parameter ...";
CM_ BO_ 2633716734 "High Voltage Energy Storage Pack 4 History";
CM_ SG_ 2633716734 HVESP4StateofHealth "HVESP4 State of Health: This signal represents the expected remaining Life of this High Voltage Energy Storage Pack instance, in percent.  Battery life is a manufacturer-specific measure of how well the energy storage system is functioning relative t...";
CM_ SG_ 2633716734 HVESP4CnttrOpnUndrLdCnt "HVESP4 Contactor Open Under Load Count: This signal represents the number of times the contactors inside this High Voltage Energy Storage Pack instance have opened while current is flowing through them.  The current level (that determines if an openi...";
CM_ SG_ 2633716734 HVESP4TotalEnergyThroughput "HVESP4 Total Energy Throughput: The total energy throughput which has flowed through this High Voltage Energy Storage Pack instance.  This parameter is the sum of the absolute values of the Energy into and out of this HVES instance.  This parameter i...";
CM_ SG_ 2633716734 HVESP4TotalAccumulatedCharge "HVESP4 Total Accumulated Charge: The total accumulated amp hours which have flowed through this High Voltage Energy Storage Pack instance.  This parameter is the sum of the absolute values of the Ampere hours into and out of this HVES instance.  This...";
CM_ SG_ 2633716734 HVESP4TotalLifetimeEnergyInput "HVESP4 Total Lifetime Energy Input: The cumulative energy which has flowed into this High Voltage Energy Storage Pack instance over the lifetime of the battery pack. This parameter is the sum of the Energy into this HVES instance. This value is reset...";
CM_ SG_ 2633716734 HVESP4TotalLifetimeEnergyOutput "HVESP4 Total Lifetime Energy Output: The cumulative energy which has flowed out of this High Voltage Energy Storage Pack instance over the lifetime of the battery pack. This parameter is the sum of the Energy out of this HVES instance. This value is ...";
CM_ BO_ 2566608126 "High Voltage Energy Storage Pack 4 Configuration";
CM_ SG_ 2566608126 HVESP4NominalVoltage "HVESP4 Nominal Voltage: Per the HVES manufacturer, this is the nominal operating voltage of this High Voltage Energy Storage Pack instance, e.g. “300V” or “600V”.This parameter is for one of multiple packs in an HVESS.  If there is only one pack in t...";
CM_ SG_ 2566608126 HVESP4RmmnddMnmmOprtngVltg "HVESP4 Recommended Minimum Operating Voltage: Per the HVES manufacturer, this is the minimum recommended voltage level for this High Voltage Energy Storage Pack instance operation.  Operating below this value may compromise HVES life.This parameter i...";
CM_ SG_ 2566608126 HVESP4RmmnddMxmmOprtngVltg "HVESP4 Recommended Maximum Operating Voltage: Per the HVES manufacturer, this is the maximum recommended voltage level for this High Voltage Energy Storage Pack instance operation.  Operating above this value may compromise HVES life.This parameter i...";
CM_ SG_ 2566608126 HVESP4RmmnddMnmmSttOfChrg "HVESP4 Recommended Minimum State Of Charge: Per the HVES manufacturer, this is the recommended minimum state of charge for this High Voltage Energy Storage Pack instance operation.  Operating below this value may compromise HVES life.This parameter i...";
CM_ SG_ 2566608126 HVESP4RmmnddMxmmSttOfChrg "HVESP4 Recommended Maximum State Of Charge: Per the HVES manufacturer, this is the recommended maximum state of charge for this High Voltage Energy Storage Pack instance operation.  Operating above this value may compromise HVES life.This parameter i...";
CM_ SG_ 2566608126 HVESP4RmmnddMxmmOprtngTmprtr "HVESP4 Recommended Maximum Operating Temperature: Per the HVES manufacturer, this is the recommended maximum temperature for this High Voltage Energy Storage Pack instance operation.  Operating above this value may damage HVES hardware, or compromise...";
CM_ SG_ 2566608126 HVESP4RmmnddMnmmOprtngTmprtr "HVESP4 Recommended Minimum Operating Temperature: Per the HVES manufacturer, this is the recommended minimum temperature for this High Voltage Energy Storage Pack instance operation.  Operating below this value may damage HVES hardware, or compromise...";
CM_ SG_ 2566608126 HVESP4CellMaximumVoltageLimit "HVESP4 Cell Maximum Voltage Limit: Per the HVES manufacturer, this is the maximum cell voltage for this High Voltage Energy Storage Pack instance operation.  Operating above this value may damage HVES hardware, or compromise HVES life.This parameter ...";
CM_ SG_ 2566608126 HVESP4CellMinimumVoltageLimit "HVESP4 Cell Minimum Voltage Limit: Per the HVES manufacturer, this is the minimum cell voltage for this High Voltage Energy Storage Pack instance operation.  Operating below this value may damage HVES hardware, or compromise HVES life.This parameter ...";
CM_ BO_ 2633717246 "High Voltage Energy Storage Pack 3 History";
CM_ SG_ 2633717246 HVESP3StateofHealth "HVESP3 State of Health: This signal represents the expected remaining Life of this High Voltage Energy Storage Pack instance, in percent.  Battery life is a manufacturer-specific measure of how well the energy storage system is functioning relative t...";
CM_ SG_ 2633717246 HVESP3CnttrOpnUndrLdCnt "HVESP3 Contactor Open Under Load Count: This signal represents the number of times the contactors inside this High Voltage Energy Storage Pack instance have opened while current is flowing through them.  The current level (that determines if an openi...";
CM_ SG_ 2633717246 HVESP3TotalEnergyThroughput "HVESP3 Total Energy Throughput: The total energy throughput which has flowed through this High Voltage Energy Storage Pack instance.  This parameter is the sum of the absolute values of the Energy into and out of this HVES instance.  This parameter i...";
CM_ SG_ 2633717246 HVESP3TotalAccumulatedCharge "HVESP3 Total Accumulated Charge: The total accumulated amp hours which have flowed through this High Voltage Energy Storage Pack instance.  This parameter is the sum of the absolute values of the Ampere hours into and out of this HVES instance.  This...";
CM_ SG_ 2633717246 HVESP3TotalLifetimeEnergyInput "HVESP3 Total Lifetime Energy Input: The cumulative energy which has flowed into this High Voltage Energy Storage Pack instance over the lifetime of the battery pack. This parameter is the sum of the Energy into this HVES instance. This value is reset...";
CM_ SG_ 2633717246 HVESP3TotalLifetimeEnergyOutput "HVESP3 Total Lifetime Energy Output: The cumulative energy which has flowed out of this High Voltage Energy Storage Pack instance over the lifetime of the battery pack. This parameter is the sum of the Energy out of this HVES instance. This value is ...";
CM_ BO_ 2566608638 "High Voltage Energy Storage Pack 3 Configuration";
CM_ SG_ 2566608638 HVESP3NominalVoltage "HVESP3 Nominal Voltage: Per the HVES manufacturer, this is the nominal operating voltage of this High Voltage Energy Storage Pack instance, e.g. “300V” or “600V”.This parameter is for one of multiple packs in an HVESS.  If there is only one pack in t...";
CM_ SG_ 2566608638 HVESP3RmmnddMnmmOprtngVltg "HVESP3 Recommended Minimum Operating Voltage: Per the HVES manufacturer, this is the minimum recommended voltage level for this High Voltage Energy Storage Pack instance operation.  Operating below this value may compromise HVES life.This parameter i...";
CM_ SG_ 2566608638 HVESP3RmmnddMxmmOprtngVltg "HVESP3 Recommended Maximum Operating Voltage: Per the HVES manufacturer, this is the maximum recommended voltage level for this High Voltage Energy Storage Pack instance operation.  Operating above this value may compromise HVES life.This parameter i...";
CM_ SG_ 2566608638 HVESP3RmmnddMnmmSttOfChrg "HVESP3 Recommended Minimum State Of Charge: Per the HVES manufacturer, this is the recommended minimum state of charge for this High Voltage Energy Storage Pack instance operation.  Operating below this value may compromise HVES life.This parameter i...";
CM_ SG_ 2566608638 HVESP3RmmnddMxmmSttOfChrg "HVESP3 Recommended Maximum State Of Charge: Per the HVES manufacturer, this is the recommended maximum state of charge for this High Voltage Energy Storage Pack instance operation.  Operating above this value may compromise HVES life.This parameter i...";
CM_ SG_ 2566608638 HVESP3RmmnddMxmmOprtngTmprtr "HVESP3 Recommended Maximum Operating Temperature: Per the HVES manufacturer, this is the recommended maximum temperature for this High Voltage Energy Storage Pack instance operation.  Operating above this value may damage HVES hardware, or compromise...";
CM_ SG_ 2566608638 HVESP3RmmnddMnmmOprtngTmprtr "HVESP3 Recommended Minimum Operating Temperature: Per the HVES manufacturer, this is the recommended minimum temperature for this High Voltage Energy Storage Pack instance operation.  Operating below this value may damage HVES hardware, or compromise...";
CM_ SG_ 2566608638 HVESP3CellMaximumVoltageLimit "HVESP3 Cell Maximum Voltage Limit: Per the HVES manufacturer, this is the maximum cell voltage for this High Voltage Energy Storage Pack instance operation.  Operating above this value may damage HVES hardware, or compromise HVES life.This parameter ...";
CM_ SG_ 2566608638 HVESP3CellMinimumVoltageLimit "HVESP3 Cell Minimum Voltage Limit: Per the HVES manufacturer, this is the minimum cell voltage for this High Voltage Energy Storage Pack instance operation.  Operating below this value may damage HVES hardware, or compromise HVES life.This parameter ...";
CM_ BO_ 2633717758 "High Voltage Energy Storage Pack 2 History";
CM_ SG_ 2633717758 HVESP2StateofHealth "HVESP2 State of Health: This signal represents the expected remaining Life of this High Voltage Energy Storage Pack instance, in percent.  Battery life is a manufacturer-specific measure of how well the energy storage system is functioning relative t...";
CM_ SG_ 2633717758 HVESP2CnttrOpnUndrLdCnt "HVESP2 Contactor Open Under Load Count: This signal represents the number of times the contactors inside this High Voltage Energy Storage Pack instance have opened while current is flowing through them.  The current level (that determines if an openi...";
CM_ SG_ 2633717758 HVESP2TotalEnergyThroughput "HVESP2 Total Energy Throughput: The total energy throughput which has flowed through this High Voltage Energy Storage Pack instance.  This parameter is the sum of the absolute values of the Energy into and out of this HVES instance.  This parameter i...";
CM_ SG_ 2633717758 HVESP2TotalAccumulatedCharge "HVESP2 Total Accumulated Charge: The total accumulated amp hours which have flowed through this High Voltage Energy Storage Pack instance.  This parameter is the sum of the absolute values of the Ampere hours into and out of this HVES instance.  This...";
CM_ SG_ 2633717758 HVESP2TotalLifetimeEnergyInput "HVESP2 Total Lifetime Energy Input: The cumulative energy which has flowed into this High Voltage Energy Storage Pack instance over the lifetime of the battery pack. This parameter is the sum of the Energy into this HVES instance. This value is reset...";
CM_ SG_ 2633717758 HVESP2TotalLifetimeEnergyOutput "HVESP2 Total Lifetime Energy Output: The cumulative energy which has flowed out of this High Voltage Energy Storage Pack instance over the lifetime of the battery pack. This parameter is the sum of the Energy out of this HVES instance. This value is ...";
CM_ BO_ 2566609150 "High Voltage Energy Storage Pack 2 Configuration";
CM_ SG_ 2566609150 HVESP2NominalVoltage "HVESP2 Nominal Voltage: Per the HVES manufacturer, this is the nominal operating voltage of this High Voltage Energy Storage Pack instance, e.g. “300V” or “600V”.This parameter is for one of multiple packs in an HVESS.  If there is only one pack in t...";
CM_ SG_ 2566609150 HVESP2RmmnddMnmmOprtngVltg "HVESP2 Recommended Minimum Operating Voltage: Per the HVES manufacturer, this is the minimum recommended voltage level for this High Voltage Energy Storage Pack instance operation.  Operating below this value may compromise HVES life.This parameter i...";
CM_ SG_ 2566609150 HVESP2RmmnddMxmmOprtngVltg "HVESP2 Recommended Maximum Operating Voltage: Per the HVES manufacturer, this is the maximum recommended voltage level for this High Voltage Energy Storage Pack instance operation.  Operating above this value may compromise HVES life.This parameter i...";
CM_ SG_ 2566609150 HVESP2RmmnddMnmmSttOfChrg "HVESP2 Recommended Minimum State Of Charge: Per the HVES manufacturer, this is the recommended minimum state of charge for this High Voltage Energy Storage Pack instance operation.  Operating below this value may compromise HVES life.This parameter i...";
CM_ SG_ 2566609150 HVESP2RmmnddMxmmSttOfChrg "HVESP2 Recommended Maximum State Of Charge: Per the HVES manufacturer, this is the recommended maximum state of charge for this High Voltage Energy Storage Pack instance operation.  Operating above this value may compromise HVES life.This parameter i...";
CM_ SG_ 2566609150 HVESP2RmmnddMxmmOprtngTmprtr "HVESP2 Recommended Maximum Operating Temperature: Per the HVES manufacturer, this is the recommended maximum temperature for this High Voltage Energy Storage Pack instance operation.  Operating above this value may damage HVES hardware, or compromise...";
CM_ SG_ 2566609150 HVESP2RmmnddMnmmOprtngTmprtr "HVESP2 Recommended Minimum Operating Temperature: Per the HVES manufacturer, this is the recommended minimum temperature for this High Voltage Energy Storage Pack instance operation.  Operating below this value may damage HVES hardware, or compromise...";
CM_ SG_ 2566609150 HVESP2CellMaximumVoltageLimit "HVESP2 Cell Maximum Voltage Limit: Per the HVES manufacturer, this is the maximum cell voltage for this High Voltage Energy Storage Pack instance operation.  Operating above this value may damage HVES hardware, or compromise HVES life.This parameter ...";
CM_ SG_ 2566609150 HVESP2CellMinimumVoltageLimit "HVESP2 Cell Minimum Voltage Limit: Per the HVES manufacturer, this is the minimum cell voltage for this High Voltage Energy Storage Pack instance operation.  Operating below this value may damage HVES hardware, or compromise HVES life.This parameter ...";
CM_ BO_ 2633718270 "High Voltage Energy Storage Pack 1 History";
CM_ SG_ 2633718270 HVESP1StateofHealth "HVESP1 State of Health: This signal represents the expected remaining Life of this High Voltage Energy Storage Pack instance, in percent.  Battery life is a manufacturer-specific measure of how well the energy storage system is functioning relative t...";
CM_ SG_ 2633718270 HVESP1CnttrOpnUndrLdCnt "HVESP1 Contactor Open Under Load Count: This signal represents the number of times the contactors inside this High Voltage Energy Storage Pack instance have opened while current is flowing through them.  The current level (that determines if an openi...";
CM_ SG_ 2633718270 HVESP1TotalEnergyThroughput "HVESP1 Total Energy Throughput: The total energy throughput which has flowed through this High Voltage Energy Storage Pack instance.  This parameter is the sum of the absolute values of the Energy into and out of this HVES instance.  This parameter i...";
CM_ SG_ 2633718270 HVESP1TotalAccumulatedCharge "HVESP1 Total Accumulated Charge: The total accumulated amp hours which have flowed through this High Voltage Energy Storage Pack instance.  This parameter is the sum of the absolute values of the Ampere hours into and out of this HVES instance.  This...";
CM_ SG_ 2633718270 HVESP1TotalLifetimeEnergyInput "HVESP1 Total Lifetime Energy Input: The cumulative energy which has flowed into this High Voltage Energy Storage Pack instance over the lifetime of the battery pack. This parameter is the sum of the Energy into this HVES instance. This value is reset...";
CM_ SG_ 2633718270 HVESP1TotalLifetimeEnergyOutput "HVESP1 Total Lifetime Energy Output: The cumulative energy which has flowed out of this High Voltage Energy Storage Pack instance over the lifetime of the battery pack. This parameter is the sum of the Energy out of this HVES instance. This value is ...";
CM_ BO_ 2566609662 "High Voltage Energy Storage Pack 1 Configuration";
CM_ SG_ 2566609662 HVESP1NominalVoltage "HVESP1 Nominal Voltage: Per the HVES manufacturer, this is the nominal operating voltage of this High Voltage Energy Storage Pack instance, e.g. “300V” or “600V”.This parameter is for one of multiple packs in an HVESS.  If there is only one pack in t...";
CM_ SG_ 2566609662 HVESP1RmmnddMnmmOprtngVltg "HVESP1 Recommended Minimum Operating Voltage: Per the HVES manufacturer, this is the minimum recommended voltage level for this High Voltage Energy Storage Pack instance operation.  Operating below this value may compromise HVES life.This parameter i...";
CM_ SG_ 2566609662 HVESP1RmmnddMxmmOprtngVltg "HVESP1 Recommended Maximum Operating Voltage: Per the HVES manufacturer, this is the maximum recommended voltage level for this High Voltage Energy Storage Pack instance operation.  Operating above this value may compromise HVES life.This parameter i...";
CM_ SG_ 2566609662 HVESP1RmmnddMnmmSttOfChrg "HVESP1 Recommended Minimum State Of Charge: Per the HVES manufacturer, this is the recommended minimum state of charge for this High Voltage Energy Storage Pack instance operation.  Operating below this value may compromise HVES life.This parameter i...";
CM_ SG_ 2566609662 HVESP1RmmnddMxmmSttOfChrg "HVESP1 Recommended Maximum State Of Charge: Per the HVES manufacturer, this is the recommended maximum state of charge for this High Voltage Energy Storage Pack instance operation.  Operating above this value may compromise HVES life.This parameter i...";
CM_ SG_ 2566609662 HVESP1RmmnddMxmmOprtngTmprtr "HVESP1 Recommended Maximum Operating Temperature: Per the HVES manufacturer, this is the recommended maximum temperature for this High Voltage Energy Storage Pack instance operation.  Operating above this value may damage HVES hardware, or compromise...";
CM_ SG_ 2566609662 HVESP1RmmnddMnmmOprtngTmprtr "HVESP1 Recommended Minimum Operating Temperature: Per the HVES manufacturer, this is the recommended minimum temperature for this High Voltage Energy Storage Pack instance operation.  Operating below this value may damage HVES hardware, or compromise...";
CM_ SG_ 2566609662 HVESP1CellMaximumVoltageLimit "HVESP1 Cell Maximum Voltage Limit: Per the HVES manufacturer, this is the maximum cell voltage for this High Voltage Energy Storage Pack instance operation.  Operating above this value may damage HVES hardware, or compromise HVES life.This parameter ...";
CM_ SG_ 2566609662 HVESP1CellMinimumVoltageLimit "HVESP1 Cell Minimum Voltage Limit: Per the HVES manufacturer, this is the minimum cell voltage for this High Voltage Energy Storage Pack instance operation.  Operating below this value may damage HVES hardware, or compromise HVES life.This parameter ...";
CM_ BO_ 2633718782 "Vehicle Fire Suppression System Module 1 Detector Data";
CM_ SG_ 2633718782 VFSSMdl1Dttr1DttrTp "VFSS Module 1 Detector 1 Detector Type: The type of detector for detector 1 of module 1.0 = Analog thermal sensor1 = Analog gas sensor2 = Analog optical sensor3 = Heat detector4 = Manual release switch5 = SAE Reserved6 = SAE Reserved7 = SAE Reserved8...";
CM_ SG_ 2633718782 VFSSMdl1Dttr1DttrDtSLOT "VFSS Module 1 Detector 1 Detector Data SLOT: The SAE SLOT encoding used for data reported in SPN 10847 (VFSS Module 1 Detector 1 Data) for this detector instance of this module.0 = SAEev03 (voltage)1 = SAEpc07 (percent)2 = SAEtp02 (temperature)3 = SA...";
CM_ SG_ 2633718782 VFSSMdl1Dttr2DttrTp "VFSS Module 1 Detector 2 Detector Type: The type of detector for detector 2 of module 1.0 = Analog thermal sensor1 = Analog gas sensor2 = Analog optical sensor3 = Heat detector4 = Manual release switch5 = SAE Reserved6 = SAE Reserved7 = SAE Reserved8...";
CM_ SG_ 2633718782 VFSSMdl1Dttr2DttrDtSLOT "VFSS Module 1 Detector 2 Detector Data SLOT: The SAE SLOT encoding used for data reported in SPN 10848 (VFSS Module 1 Detector 2 Data) for this detector instance of this module.0 = SAEev03 (voltage)1 = SAEpc07 (percent)2 = SAEtp02 (temperature)3 = SA...";
CM_ SG_ 2633718782 VFSSMdl1Dttr3DttrTp "VFSS Module 1 Detector 3 Detector Type: The type of detector for detector 3 of module 1.0 = Analog thermal sensor1 = Analog gas sensor2 = Analog optical sensor3 = Heat detector4 = Manual release switch5 = SAE Reserved6 = SAE Reserved7 = SAE Reserved8...";
CM_ SG_ 2633718782 VFSSMdl1Dttr3DttrDtSLOT "VFSS Module 1 Detector 3 Detector Data SLOT: The SAE SLOT encoding used for data reported in SPN 10853 (VFSS Module 1 Detector 3 Data) for this detector instance of this module.0 = SAEev03 (voltage)1 = SAEpc07 (percent)2 = SAEtp02 (temperature)3 = SA...";
CM_ SG_ 2633718782 VFSSMdl1Dttr4DttrTp "VFSS Module 1 Detector 4 Detector Type: The type of detector for detector 4 of module 1.0 = Analog thermal sensor1 = Analog gas sensor2 = Analog optical sensor3 = Heat detector4 = Manual release switch5 = SAE Reserved6 = SAE Reserved7 = SAE Reserved8...";
CM_ SG_ 2633718782 VFSSMdl1Dttr4DttrDtSLOT "VFSS Module 1 Detector 4 Detector Data SLOT: The SAE SLOT encoding used for data reported in SPN 10856 (VFSS Module 1 Detector 4 Data) for this detector instance of this module.0 = SAEev03 (voltage)1 = SAEpc07 (percent)2 = SAEtp02 (temperature)3 = SA...";
CM_ SG_ 2633718782 VFSSMdl1Dttr5DttrTp "VFSS Module 1 Detector 5 Detector Type: The type of detector for detector 5 of module 1.0 = Analog thermal sensor1 = Analog gas sensor2 = Analog optical sensor3 = Heat detector4 = Manual release switch5 = SAE Reserved6 = SAE Reserved7 = SAE Reserved8...";
CM_ SG_ 2633718782 VFSSMdl1Dttr5DttrDtSLOT "VFSS Module 1 Detector 5 Detector Data SLOT: The SAE SLOT encoding used for data reported in SPN 10859 (VFSS Module 1 Detector 5 Data) for this detector instance of this module.0 = SAEev03 (voltage)1 = SAEpc07 (percent)2 = SAEtp02 (temperature)3 = SA...";
CM_ SG_ 2633718782 VFSSMdl1Dttr6DttrTp "VFSS Module 1 Detector 6 Detector Type: The type of detector for detector 6 of module 1.0 = Analog thermal sensor1 = Analog gas sensor2 = Analog optical sensor3 = Heat detector4 = Manual release switch5 = SAE Reserved6 = SAE Reserved7 = SAE Reserved8...";
CM_ SG_ 2633718782 VFSSMdl1Dttr6DttrDtSLOT "VFSS Module 1 Detector 6 Detector Data SLOT: The SAE SLOT encoding used for data reported in SPN 10861 (VFSS Module 1 Detector 6 Data) for this detector instance of this module.0 = SAEev03 (voltage)1 = SAEpc07 (percent)2 = SAEtp02 (temperature)3 = SA...";
CM_ SG_ 2633718782 VFSSMdl1Dttr7DttrTp "VFSS Module 1 Detector 7 Detector Type: The type of detector for detector 7 of module 1.0 = Analog thermal sensor1 = Analog gas sensor2 = Analog optical sensor3 = Heat detector4 = Manual release switch5 = SAE Reserved6 = SAE Reserved7 = SAE Reserved8...";
CM_ SG_ 2633718782 VFSSMdl1Dttr7DttrDtSLOT "VFSS Module 1 Detector 7 Detector Data SLOT: The SAE SLOT encoding used for data reported in SPN 10865 (VFSS Module 1 Detector 7 Data) for this detector instance of this module.0 = SAEev03 (voltage)1 = SAEpc07 (percent)2 = SAEtp02 (temperature)3 = SA...";
CM_ SG_ 2633718782 VFSSMdl1Dttr8DttrTp "VFSS Module 1 Detector 8 Detector Type: The type of detector for detector 8 of module 1.0 = Analog thermal sensor1 = Analog gas sensor2 = Analog optical sensor3 = Heat detector4 = Manual release switch5 = SAE Reserved6 = SAE Reserved7 = SAE Reserved8...";
CM_ SG_ 2633718782 VFSSMdl1Dttr8DttrDtSLOT "VFSS Module 1 Detector 8 Detector Data SLOT: The SAE SLOT encoding used for data reported in SPN 10868 (VFSS Module 1 Detector 8 Data) for this detector instance of this module.0 = SAEev03 (voltage)1 = SAEpc07 (percent)2 = SAEtp02 (temperature)3 = SA...";
CM_ BO_ 2633719038 "Vehicle Fire Suppression System Module 2 Detector Data";
CM_ SG_ 2633719038 VFSSMdl2Dttr1DttrTp "VFSS Module 2 Detector 1 Detector Type: The type of detector for detector 1 of module 2.0 = Analog thermal sensor1 = Analog gas sensor2 = Analog optical sensor3 = Heat detector4 = Manual release switch5 = SAE Reserved6 = SAE Reserved7 = SAE Reserved8...";
CM_ SG_ 2633719038 VFSSMdl2Dttr1DttrDtSLOT "VFSS Module 2 Detector 1 Detector Data SLOT: The SAE SLOT encoding used for data reported in SPN 10871 (VFSS Module 2 Detector 1 Data) for this detector instance of this module.0 = SAEev03 (voltage)1 = SAEpc07 (percent)2 = SAEtp02 (temperature)3 = SA...";
CM_ SG_ 2633719038 VFSSMdl2Dttr2DttrTp "VFSS Module 2 Detector 2 Detector Type: The type of detector for detector 2 of module 2.0 = Analog thermal sensor1 = Analog gas sensor2 = Analog optical sensor3 = Heat detector4 = Manual release switch5 = SAE Reserved6 = SAE Reserved7 = SAE Reserved8...";
CM_ SG_ 2633719038 VFSSMdl2Dttr2DttrDtSLOT "VFSS Module 2 Detector 2 Detector Data SLOT: The SAE SLOT encoding used for data reported in SPN 10871 (VFSS Module 2 Detector 2 Data) for this detector instance of this module.0 = SAEev03 (voltage)1 = SAEpc07 (percent)2 = SAEtp02 (temperature)3 = SA...";
CM_ SG_ 2633719038 VFSSMdl2Dttr3DttrTp "VFSS Module 2 Detector 3 Detector Type: The type of detector for detector 3 of module 2.0 = Analog thermal sensor1 = Analog gas sensor2 = Analog optical sensor3 = Heat detector4 = Manual release switch5 = SAE Reserved6 = SAE Reserved7 = SAE Reserved8...";
CM_ SG_ 2633719038 VFSSMdl2Dttr3DttrDtSLOT "VFSS Module 2 Detector 3 Detector Data SLOT: The SAE SLOT encoding used for data reported in SPN 10871 (VFSS Module 2 Detector 3 Data) for this detector instance of this module.0 = SAEev03 (voltage)1 = SAEpc07 (percent)2 = SAEtp02 (temperature)3 = SA...";
CM_ SG_ 2633719038 VFSSMdl2Dttr4DttrTp "VFSS Module 2 Detector 4 Detector Type: The type of detector for detector 4 of module 2.0 = Analog thermal sensor1 = Analog gas sensor2 = Analog optical sensor3 = Heat detector4 = Manual release switch5 = SAE Reserved6 = SAE Reserved7 = SAE Reserved8...";
CM_ SG_ 2633719038 VFSSMdl2Dttr4DttrDtSLOT "VFSS Module 2 Detector 4 Detector Data SLOT: The SAE SLOT encoding used for data reported in SPN 10871 (VFSS Module 2 Detector 4 Data) for this detector instance of this module.0 = SAEev03 (voltage)1 = SAEpc07 (percent)2 = SAEtp02 (temperature)3 = SA...";
CM_ SG_ 2633719038 VFSSMdl2Dttr5DttrTp "VFSS Module 2 Detector 5 Detector Type: The type of detector for detector 5 of module 2.0 = Analog thermal sensor1 = Analog gas sensor2 = Analog optical sensor3 = Heat detector4 = Manual release switch5 = SAE Reserved6 = SAE Reserved7 = SAE Reserved8...";
CM_ SG_ 2633719038 VFSSMdl2Dttr5DttrDtSLOT "VFSS Module 2 Detector 5 Detector Data SLOT: The SAE SLOT encoding used for data reported in SPN 10871 (VFSS Module 2 Detector 5 Data) for this detector instance of this module.0 = SAEev03 (voltage)1 = SAEpc07 (percent)2 = SAEtp02 (temperature)3 = SA...";
CM_ SG_ 2633719038 VFSSMdl2Dttr6DttrTp "VFSS Module 2 Detector 6 Detector Type: The type of detector for detector 6 of module 2.0 = Analog thermal sensor1 = Analog gas sensor2 = Analog optical sensor3 = Heat detector4 = Manual release switch5 = SAE Reserved6 = SAE Reserved7 = SAE Reserved8...";
CM_ SG_ 2633719038 VFSSMdl2Dttr6DttrDtSLOT "VFSS Module 2 Detector 6 Detector Data SLOT: The SAE SLOT encoding used for data reported in SPN 10871 (VFSS Module 2 Detector 6 Data) for this detector instance of this module.0 = SAEev03 (voltage)1 = SAEpc07 (percent)2 = SAEtp02 (temperature)3 = SA...";
CM_ SG_ 2633719038 VFSSMdl2Dttr7DttrTp "VFSS Module 2 Detector 7 Detector Type: The type of detector for detector 7 of module 2.0 = Analog thermal sensor1 = Analog gas sensor2 = Analog optical sensor3 = Heat detector4 = Manual release switch5 = SAE Reserved6 = SAE Reserved7 = SAE Reserved8...";
CM_ SG_ 2633719038 VFSSMdl2Dttr7DttrDtSLOT "VFSS Module 2 Detector 7 Detector Data SLOT: The SAE SLOT encoding used for data reported in SPN 10871 (VFSS Module 2 Detector 7 Data) for this detector instance of this module.0 = SAEev03 (voltage)1 = SAEpc07 (percent)2 = SAEtp02 (temperature)3 = SA...";
CM_ SG_ 2633719038 VFSSMdl2Dttr8DttrTp "VFSS Module 2 Detector 8 Detector Type: The type of detector for detector 8 of module 2.0 = Analog thermal sensor1 = Analog gas sensor2 = Analog optical sensor3 = Heat detector4 = Manual release switch5 = SAE Reserved6 = SAE Reserved7 = SAE Reserved8...";
CM_ SG_ 2633719038 VFSSMdl2Dttr8DttrDtSLOT "VFSS Module 2 Detector 8 Detector Data SLOT: The SAE SLOT encoding used for data reported in SPN 10871 (VFSS Module 2 Detector 8 Data) for this detector instance of this module.0 = SAEev03 (voltage)1 = SAEpc07 (percent)2 = SAEtp02 (temperature)3 = SA...";
BA_DEF_ SG_  "SPN" INT 0 524287;
BA_DEF_ BO_  "VFrameFormat" ENUM  "StandardCAN","ExtendedCAN","reserved","J1939PG";
BA_DEF_DEF_  "SPN" 0;
BA_DEF_DEF_  "VFrameFormat" "J1939PG";
BA_ "SPN" SG_ 2566593278 MtrGnrtr6InvrtrLmtsRqstMhnlCRC 12193;
BA_ "SPN" SG_ 2566593278 MtrGnrtr6InvrtrLmtsRqstMhnlCntr 12194;
BA_ "SPN" SG_ 2566593278 MtrGnrtr6InvrtrLmtsRqstTrqMxmm 12195;
BA_ "SPN" SG_ 2566593278 MtrGnrtr6InvrtrLmtsRqstTrqMnmm 12196;
BA_ "SPN" SG_ 2566593278 MtrGnrtr6InvrtrLmtsRqstSpdMxmm 12197;
BA_ "SPN" SG_ 2566593278 MtrGnrtr6InvrtrLmtsRqstSpdMnmm 12198;
BA_ "SPN" SG_ 2566593534 MtrGnrtr6InvrtrLmtsRqstDCSdCRC 12209;
BA_ "SPN" SG_ 2566593534 MtrGnrtr6InvrtrLmtsRqstDCSdCntr 12210;
BA_ "SPN" SG_ 2566593534 MtGt6IvtLtsRqstDCSdVtMx 12211;
BA_ "SPN" SG_ 2566593534 MtGt6IvtLtsRqstDCSdVtM 12212;
BA_ "SPN" SG_ 2566593534 MtGt6IvtLtsRqstDCSdCtMx 12213;
BA_ "SPN" SG_ 2566593534 MtGt6IvtLtsRqstDCSdCtM 12214;
BA_ "SPN" SG_ 2566593790 MtGt6IvtHVtBsAtvIstTstCd 12232;
BA_ "SPN" SG_ 2566593790 MtGt6IvtHVtBsPssvIstTstCd 12233;
BA_ "SPN" SG_ 2566593790 MtGt6IvtHVtBsHSdRsstCtRqst 12234;
BA_ "SPN" SG_ 2566593790 MtGt6IvtHVtBsLwSdRsstCtRqst 12235;
BA_ "SPN" SG_ 2365267454 MtrGnrtr5InvrtrRtLmtsRqst2CRC 12148;
BA_ "SPN" SG_ 2365267454 MtrGnrtr5InvrtrRtLmtsRqst2Cntr 12149;
BA_ "SPN" SG_ 2365267454 MtrGnrtr5InvrtrPIDCntrlAppllMd 12150;
BA_ "SPN" SG_ 2365267454 MtGt5IvtPIDCtNzdDtG 12151;
BA_ "SPN" SG_ 2365267454 MtGt5IvtPIDCtNzdItG 12152;
BA_ "SPN" SG_ 2365267454 MtGt5IvtPIDCtNzdPptG 12153;
BA_ "SPN" SG_ 2365267454 MtGt5IvtPIDCtFdFwdTq 12154;
BA_ "SPN" SG_ 2566594302 MtrGnrtr5InvrtrLmtsRqstPwrCRC 12063;
BA_ "SPN" SG_ 2566594302 MtrGnrtr5InvrtrLmtsRqstPwrCntr 12064;
BA_ "SPN" SG_ 2566594302 MtGt5IvtLtsRqstMPwMx 12065;
BA_ "SPN" SG_ 2566594302 MtGt5IvtLtsRqstMPwM 12066;
BA_ "SPN" SG_ 2566594302 MtGt5IvtLtsRqstDCSdPwMx 12067;
BA_ "SPN" SG_ 2566594302 MtGt5IvtLtsRqstDCSdPwM 12068;
BA_ "SPN" SG_ 2566594558 MtrGnrtr5InvrtrLmtsRqstMhnlCRC 12075;
BA_ "SPN" SG_ 2566594558 MtrGnrtr5InvrtrLmtsRqstMhnlCntr 12076;
BA_ "SPN" SG_ 2566594558 MtrGnrtr5InvrtrLmtsRqstTrqMxmm 12077;
BA_ "SPN" SG_ 2566594558 MtrGnrtr5InvrtrLmtsRqstTrqMnmm 12078;
BA_ "SPN" SG_ 2566594558 MtrGnrtr5InvrtrLmtsRqstSpdMxmm 12079;
BA_ "SPN" SG_ 2566594558 MtrGnrtr5InvrtrLmtsRqstSpdMnmm 12080;
BA_ "SPN" SG_ 2566594814 MtrGnrtr5InvrtrLmtsRqstDCSdCRC 12091;
BA_ "SPN" SG_ 2566594814 MtrGnrtr5InvrtrLmtsRqstDCSdCntr 12092;
BA_ "SPN" SG_ 2566594814 MtGt5IvtLtsRqstDCSdVtMx 12093;
BA_ "SPN" SG_ 2566594814 MtGt5IvtLtsRqstDCSdVtM 12094;
BA_ "SPN" SG_ 2566594814 MtGt5IvtLtsRqstDCSdCtMx 12095;
BA_ "SPN" SG_ 2566594814 MtGt5IvtLtsRqstDCSdCtM 12096;
BA_ "SPN" SG_ 2566595070 MtGt5IvtHVtBsAtvIstTstCd 12114;
BA_ "SPN" SG_ 2566595070 MtGt5IvtHVtBsPssvIstTstCd 12115;
BA_ "SPN" SG_ 2566595070 MtGt5IvtHVtBsHSdRsstCtRqst 12116;
BA_ "SPN" SG_ 2566595070 MtGt5IvtHVtBsLwSdRsstCtRqst 12117;
BA_ "SPN" SG_ 2365268734 MtrGnrtr4InvrtrRtLmtsRqst2CRC 12030;
BA_ "SPN" SG_ 2365268734 MtrGnrtr4InvrtrRtLmtsRqst2Cntr 12031;
BA_ "SPN" SG_ 2365268734 MtrGnrtr4InvrtrPIDCntrlAppllMd 12032;
BA_ "SPN" SG_ 2365268734 MtGt4IvtPIDCtNzdDtG 12033;
BA_ "SPN" SG_ 2365268734 MtGt4IvtPIDCtNzdItG 12034;
BA_ "SPN" SG_ 2365268734 MtGt4IvtPIDCtNzdPptG 12035;
BA_ "SPN" SG_ 2365268734 MtGt4IvtPIDCtFdFwdTq 12036;
BA_ "SPN" SG_ 2566595582 MtrGnrtr4InvrtrLmtsRqstPwrCRC 11945;
BA_ "SPN" SG_ 2566595582 MtrGnrtr4InvrtrLmtsRqstPwrCntr 11946;
BA_ "SPN" SG_ 2566595582 MtGt4IvtLtsRqstMPwMx 11947;
BA_ "SPN" SG_ 2566595582 MtGt4IvtLtsRqstMPwM 11948;
BA_ "SPN" SG_ 2566595582 MtGt4IvtLtsRqstDCSdPwMx 11949;
BA_ "SPN" SG_ 2566595582 MtGt4IvtLtsRqstDCSdPwM 11950;
BA_ "SPN" SG_ 2566595838 MtrGnrtr4InvrtrLmtsRqstMhnlCRC 11957;
BA_ "SPN" SG_ 2566595838 MtrGnrtr4InvrtrLmtsRqstMhnlCntr 11958;
BA_ "SPN" SG_ 2566595838 MtrGnrtr4InvrtrLmtsRqstTrqMxmm 11959;
BA_ "SPN" SG_ 2566595838 MtrGnrtr4InvrtrLmtsRqstTrqMnmm 11960;
BA_ "SPN" SG_ 2566595838 MtrGnrtr4InvrtrLmtsRqstSpdMxmm 11961;
BA_ "SPN" SG_ 2566595838 MtrGnrtr4InvrtrLmtsRqstSpdMnmm 11962;
BA_ "SPN" SG_ 2566596094 MtrGnrtr4InvrtrLmtsRqstDCSdCRC 11973;
BA_ "SPN" SG_ 2566596094 MtrGnrtr4InvrtrLmtsRqstDCSdCntr 11974;
BA_ "SPN" SG_ 2566596094 MtGt4IvtLtsRqstDCSdVtMx 11975;
BA_ "SPN" SG_ 2566596094 MtGt4IvtLtsRqstDCSdVtM 11976;
BA_ "SPN" SG_ 2566596094 MtGt4IvtLtsRqstDCSdCtMx 11977;
BA_ "SPN" SG_ 2566596094 MtGt4IvtLtsRqstDCSdCtM 11978;
BA_ "SPN" SG_ 2566596350 MtGt4IvtHVtBsAtvIstTstCd 11996;
BA_ "SPN" SG_ 2566596350 MtGt4IvtHVtBsPssvIstTstCd 11997;
BA_ "SPN" SG_ 2566596350 MtGt4IvtHVtBsHSdRsstCtRqst 11998;
BA_ "SPN" SG_ 2566596350 MtGt4IvtHVtBsLwSdRsstCtRqst 11999;
BA_ "SPN" SG_ 2365270014 MtrGnrtr3InvrtrRtLmtsRqst2CRC 11912;
BA_ "SPN" SG_ 2365270014 MtrGnrtr3InvrtrRtLmtsRqst2Cntr 11913;
BA_ "SPN" SG_ 2365270014 MtrGnrtr3InvrtrPIDCntrlAppllMd 11914;
BA_ "SPN" SG_ 2365270014 MtGt3IvtPIDCtNzdDtG 11915;
BA_ "SPN" SG_ 2365270014 MtGt3IvtPIDCtNzdItG 11916;
BA_ "SPN" SG_ 2365270014 MtGt3IvtPIDCtNzdPptG 11917;
BA_ "SPN" SG_ 2365270014 MtGt3IvtPIDCtFdFwdTq 11918;
BA_ "SPN" SG_ 2566596862 MtrGnrtr3InvrtrLmtsRqstPwrCRC 11827;
BA_ "SPN" SG_ 2566596862 MtrGnrtr3InvrtrLmtsRqstPwrCntr 11828;
BA_ "SPN" SG_ 2566596862 MtGt3IvtLtsRqstMPwMx 11829;
BA_ "SPN" SG_ 2566596862 MtGt3IvtLtsRqstMPwM 11830;
BA_ "SPN" SG_ 2566596862 MtGt3IvtLtsRqstDCSdPwMx 11831;
BA_ "SPN" SG_ 2566596862 MtGt3IvtLtsRqstDCSdPwM 11832;
BA_ "SPN" SG_ 2566597118 MtrGnrtr3InvrtrLmtsRqstMhnlCRC 11839;
BA_ "SPN" SG_ 2566597118 MtrGnrtr3InvrtrLmtsRqstMhnlCntr 11840;
BA_ "SPN" SG_ 2566597118 MtrGnrtr3InvrtrLmtsRqstTrqMxmm 11841;
BA_ "SPN" SG_ 2566597118 MtrGnrtr3InvrtrLmtsRqstTrqMnmm 11842;
BA_ "SPN" SG_ 2566597118 MtrGnrtr3InvrtrLmtsRqstSpdMxmm 11843;
BA_ "SPN" SG_ 2566597118 MtrGnrtr3InvrtrLmtsRqstSpdMnmm 11844;
BA_ "SPN" SG_ 2566597374 MtrGnrtr3InvrtrLmtsRqstDCSdCRC 11855;
BA_ "SPN" SG_ 2566597374 MtrGnrtr3InvrtrLmtsRqstDCSdCntr 11856;
BA_ "SPN" SG_ 2566597374 MtGt3IvtLtsRqstDCSdVtMx 11857;
BA_ "SPN" SG_ 2566597374 MtGt3IvtLtsRqstDCSdVtM 11858;
BA_ "SPN" SG_ 2566597374 MtGt3IvtLtsRqstDCSdCtMx 11859;
BA_ "SPN" SG_ 2566597374 MtGt3IvtLtsRqstDCSdCtM 11860;
BA_ "SPN" SG_ 2566597630 MtGt3IvtHVtBsAtvIstTstCd 11878;
BA_ "SPN" SG_ 2566597630 MtGt3IvtHVtBsPssvIstTstCd 11879;
BA_ "SPN" SG_ 2566597630 MtGt3IvtHVtBsHSdRsstCtRqst 11880;
BA_ "SPN" SG_ 2566597630 MtGt3IvtHVtBsLwSdRsstCtRqst 11881;
BA_ "SPN" SG_ 2566598142 EngineTurbocharger5Speed 12313;
BA_ "SPN" SG_ 2566598142 EngineTurbocharger6Speed 12314;
BA_ "SPN" SG_ 2566598142 EngnTrhrgr5CmprssrIntkPrssr 12315;
BA_ "SPN" SG_ 2566598142 EngnTrhrgr6CmprssrIntkPrssr 12316;
BA_ "SPN" SG_ 2566598398 WinchLifetimeRevolutionCounter 12311;
BA_ "SPN" SG_ 2365272062 MtrGnrtr6InvrtrRfrn1CRC 12173;
BA_ "SPN" SG_ 2365272062 MtrGnrtr6InvrtrRfrn1Cntr 12174;
BA_ "SPN" SG_ 2365272062 MtrGnrtr6InvrtrRfrnTrq 12175;
BA_ "SPN" SG_ 2365272062 MtrGnrtr6InvrtrRfrnSpd 12176;
BA_ "SPN" SG_ 2365272062 MtrGnrtr6InvrtrRfrnPwr 12177;
BA_ "SPN" SG_ 2365272318 MtrGnrtr6InvrtrStts1CRC 12178;
BA_ "SPN" SG_ 2365272318 MtrGnrtr6InvrtrStts1Cntr 12179;
BA_ "SPN" SG_ 2365272318 MotorGenerator6Torque 12157;
BA_ "SPN" SG_ 2365272318 MotorGenerator6Speed 12155;
BA_ "SPN" SG_ 2365272318 MtrGnrtr6InvrtrDCSdCrrnt 12180;
BA_ "SPN" SG_ 2365272318 MtrGnrtr6InvrtrDCSdVltg 12158;
BA_ "SPN" SG_ 2365272574 MtrGnrtr6InvrtrRfrn2CRC 12205;
BA_ "SPN" SG_ 2365272574 MtrGnrtr6InvrtrRfrn2Cntr 12206;
BA_ "SPN" SG_ 2365272574 MtrGnrtr6InvrtrRfrnCrrnt 12207;
BA_ "SPN" SG_ 2365272574 MtrGnrtr6InvrtrRfrnVltg 12208;
BA_ "SPN" SG_ 2566599422 MtrGnrtr6InvrtrTmprtr1 12221;
BA_ "SPN" SG_ 2566599422 MtrGnrtr6InvrtrTmprtr2 12222;
BA_ "SPN" SG_ 2566599422 MtrGnrtr6InvrtrTmprtr3 12223;
BA_ "SPN" SG_ 2566599422 MtrGnrtr6InvrtrTmprtr4 12224;
BA_ "SPN" SG_ 2566599678 MotorGenerator6Temperature1 12156;
BA_ "SPN" SG_ 2566599678 MotorGenerator6Temperature2 12225;
BA_ "SPN" SG_ 2566599678 MotorGenerator6Temperature3 12226;
BA_ "SPN" SG_ 2566599678 MotorGenerator6Temperature4 12227;
BA_ "SPN" SG_ 2566599934 MtrGnrtr6InvrtrIsltnIntgrtCRC 12236;
BA_ "SPN" SG_ 2566599934 MtrGnrtr6InvrtrIsltnIntgrtCntr 12237;
BA_ "SPN" SG_ 2566599934 MtGt6IvtDCSdNtvtCsssGdVt 12238;
BA_ "SPN" SG_ 2566599934 MtGt6IvtHVtBsAtvIstTstStts 12239;
BA_ "SPN" SG_ 2566599934 MtGt6IvtHVtBsPssvIstTstStts 12240;
BA_ "SPN" SG_ 2566599934 MtGt6IvtHVtBsAtvIstTstRsts 12241;
BA_ "SPN" SG_ 2566599934 MtGt6IvtHVtBsPssvIstTstRsts 12242;
BA_ "SPN" SG_ 2566600190 MtGt6IvtPwLtddtUddRs 12243;
BA_ "SPN" SG_ 2566600190 MtGt6IvtPwLtddtDCSdCtMx 12244;
BA_ "SPN" SG_ 2566600190 MtGt6IvtPwLtddtDCSdCtM 12245;
BA_ "SPN" SG_ 2566600190 MtGt6IvtPwLtddtDCSdVtMx 12246;
BA_ "SPN" SG_ 2566600190 MtGt6IvtPwLtddtDCSdVtM 12247;
BA_ "SPN" SG_ 2566600190 MtGt6IvtPwLtddtMPwMx 12248;
BA_ "SPN" SG_ 2566600190 MtGt6IvtPwLtddtMPwM 12249;
BA_ "SPN" SG_ 2566600190 MtGt6IvtPwLtddtDCSdPwMx 12250;
BA_ "SPN" SG_ 2566600190 MtGt6IvtPwLtddtDCSdPwM 12251;
BA_ "SPN" SG_ 2566600190 MtrGnrtr6InvrtrPwrLmtddtTrqMxmm 12252;
BA_ "SPN" SG_ 2566600190 MtrGnrtr6InvrtrPwrLmtddtTrqMnmm 12253;
BA_ "SPN" SG_ 2566600190 MtrGnrtr6InvrtrPwrLmtddtSpdMxmm 12254;
BA_ "SPN" SG_ 2566600190 MtrGnrtr6InvrtrPwrLmtddtSpdMnmm 12255;
BA_ "SPN" SG_ 2566600190 MtGt6IvtPwLtddtIvtTpt 12256;
BA_ "SPN" SG_ 2566600190 MtGt6IvtPwLtddtMtTpt 12257;
BA_ "SPN" SG_ 2566600190 MtGt6IvtPwLtdDtFtCdt 13061;
BA_ "SPN" SG_ 2566600190 MtGt6IvtPwLtdDtAtvTqRtLt 13062;
BA_ "SPN" SG_ 2566600190 MtGt6IvtPwLtdDtAtvSpdRtLt 13063;
BA_ "SPN" SG_ 2566600190 MtGt6IvtTqLtdDtMCtsts 13064;
BA_ "SPN" SG_ 2365273854 MtrGnrtr5InvrtrRfrn1CRC 12055;
BA_ "SPN" SG_ 2365273854 MtrGnrtr5InvrtrRfrn1Cntr 12056;
BA_ "SPN" SG_ 2365273854 MtrGnrtr5InvrtrRfrnTrq 12057;
BA_ "SPN" SG_ 2365273854 MtrGnrtr5InvrtrRfrnSpd 12058;
BA_ "SPN" SG_ 2365273854 MtrGnrtr5InvrtrRfrnPwr 12059;
BA_ "SPN" SG_ 2365274110 MtrGnrtr5InvrtrStts1CRC 12060;
BA_ "SPN" SG_ 2365274110 MtrGnrtr5InvrtrStts1Cntr 12061;
BA_ "SPN" SG_ 2365274110 MotorGenerator5Torque 12039;
BA_ "SPN" SG_ 2365274110 MotorGenerator5Speed 12037;
BA_ "SPN" SG_ 2365274110 MtrGnrtr5InvrtrDCSdCrrnt 12062;
BA_ "SPN" SG_ 2365274110 MtrGnrtr5InvrtrDCSdVltg 12040;
BA_ "SPN" SG_ 2365274366 MtrGnrtr5InvrtrRfrn2CRC 12087;
BA_ "SPN" SG_ 2365274366 MtrGnrtr5InvrtrRfrn2Cntr 12088;
BA_ "SPN" SG_ 2365274366 MtrGnrtr5InvrtrRfrnCrrnt 12089;
BA_ "SPN" SG_ 2365274366 MtrGnrtr5InvrtrRfrnVltg 12090;
BA_ "SPN" SG_ 2566601214 MtrGnrtr5InvrtrTmprtr1 12103;
BA_ "SPN" SG_ 2566601214 MtrGnrtr5InvrtrTmprtr2 12104;
BA_ "SPN" SG_ 2566601214 MtrGnrtr5InvrtrTmprtr3 12105;
BA_ "SPN" SG_ 2566601214 MtrGnrtr5InvrtrTmprtr4 12106;
BA_ "SPN" SG_ 2566601470 MotorGenerator5Temperature1 12038;
BA_ "SPN" SG_ 2566601470 MotorGenerator5Temperature2 12107;
BA_ "SPN" SG_ 2566601470 MotorGenerator5Temperature3 12108;
BA_ "SPN" SG_ 2566601470 MotorGenerator5Temperature4 12109;
BA_ "SPN" SG_ 2566601726 MtrGnrtr5InvrtrIsltnIntgrtCRC 12118;
BA_ "SPN" SG_ 2566601726 MtrGnrtr5InvrtrIsltnIntgrtCntr 12119;
BA_ "SPN" SG_ 2566601726 MtGt5IvtDCSdNtvtCsssGdVt 12120;
BA_ "SPN" SG_ 2566601726 MtGt5IvtHVtBsAtvIstTstStts 12121;
BA_ "SPN" SG_ 2566601726 MtGt5IvtHVtBsPssvIstTstStts 12122;
BA_ "SPN" SG_ 2566601726 MtGt5IvtHVtBsAtvIstTstRsts 12123;
BA_ "SPN" SG_ 2566601726 MtGt5IvtHVtBsPssvIstTstRsts 12124;
BA_ "SPN" SG_ 2566601982 MtGt5IvtPwLtddtUddRs 12125;
BA_ "SPN" SG_ 2566601982 MtGt5IvtPwLtddtDCSdCtMx 12126;
BA_ "SPN" SG_ 2566601982 MtGt5IvtPwLtddtDCSdCtM 12127;
BA_ "SPN" SG_ 2566601982 MtGt5IvtPwLtddtDCSdVtMx 12128;
BA_ "SPN" SG_ 2566601982 MtGt5IvtPwLtddtDCSdVtM 12129;
BA_ "SPN" SG_ 2566601982 MtGt5IvtPwLtddtMPwMx 12130;
BA_ "SPN" SG_ 2566601982 MtGt5IvtPwLtddtMPwM 12131;
BA_ "SPN" SG_ 2566601982 MtGt5IvtPwLtddtDCSdPwMx 12132;
BA_ "SPN" SG_ 2566601982 MtGt5IvtPwLtddtDCSdPwM 12133;
BA_ "SPN" SG_ 2566601982 MtrGnrtr5InvrtrPwrLmtddtTrqMxmm 12134;
BA_ "SPN" SG_ 2566601982 MtrGnrtr5InvrtrPwrLmtddtTrqMnmm 12135;
BA_ "SPN" SG_ 2566601982 MtrGnrtr5InvrtrPwrLmtddtSpdMxmm 12136;
BA_ "SPN" SG_ 2566601982 MtrGnrtr5InvrtrPwrLmtddtSpdMnmm 12137;
BA_ "SPN" SG_ 2566601982 MtGt5IvtPwLtddtIvtTpt 12138;
BA_ "SPN" SG_ 2566601982 MtGt5IvtPwLtddtMtTpt 12139;
BA_ "SPN" SG_ 2566601982 MtGt5IvtPwLtdDtFtCdt 13057;
BA_ "SPN" SG_ 2566601982 MtGt5IvtPwLtdDtAtvTqRtLt 13058;
BA_ "SPN" SG_ 2566601982 MtGt5IvtPwLtdDtAtvSpdRtLt 13059;
BA_ "SPN" SG_ 2566601982 MtGt5IvtTqLtdDtMCtsts 13060;
BA_ "SPN" SG_ 2365275646 MtrGnrtr4InvrtrRfrn1CRC 11937;
BA_ "SPN" SG_ 2365275646 MtrGnrtr4InvrtrRfrn1Cntr 11938;
BA_ "SPN" SG_ 2365275646 MtrGnrtr4InvrtrRfrnTrq 11939;
BA_ "SPN" SG_ 2365275646 MtrGnrtr4InvrtrRfrnSpd 11940;
BA_ "SPN" SG_ 2365275646 MtrGnrtr4InvrtrRfrnPwr 11941;
BA_ "SPN" SG_ 2365275902 MtrGnrtr4InvrtrStts1CRC 11942;
BA_ "SPN" SG_ 2365275902 MtrGnrtr4InvrtrStts1Cntr 11943;
BA_ "SPN" SG_ 2365275902 MotorGenerator4Torque 11921;
BA_ "SPN" SG_ 2365275902 MotorGenerator4Speed 11919;
BA_ "SPN" SG_ 2365275902 MtrGnrtr4InvrtrDCSdCrrnt 11944;
BA_ "SPN" SG_ 2365275902 MtrGnrtr4InvrtrDCSdVltg 11922;
BA_ "SPN" SG_ 2365276158 MtrGnrtr4InvrtrRfrn2CRC 11969;
BA_ "SPN" SG_ 2365276158 MtrGnrtr4InvrtrRfrn2Cntr 11970;
BA_ "SPN" SG_ 2365276158 MtrGnrtr4InvrtrRfrnCrrnt 11971;
BA_ "SPN" SG_ 2365276158 MtrGnrtr4InvrtrRfrnVltg 11972;
BA_ "SPN" SG_ 2566603006 MtrGnrtr4InvrtrTmprtr1 11985;
BA_ "SPN" SG_ 2566603006 MtrGnrtr4InvrtrTmprtr2 11986;
BA_ "SPN" SG_ 2566603006 MtrGnrtr4InvrtrTmprtr3 11987;
BA_ "SPN" SG_ 2566603006 MtrGnrtr4InvrtrTmprtr4 11988;
BA_ "SPN" SG_ 2566603262 MotorGenerator4Temperature1 11920;
BA_ "SPN" SG_ 2566603262 MotorGenerator4Temperature2 11989;
BA_ "SPN" SG_ 2566603262 MotorGenerator4Temperature3 11990;
BA_ "SPN" SG_ 2566603262 MotorGenerator4Temperature4 11991;
BA_ "SPN" SG_ 2566603518 MtrGnrtr4InvrtrIsltnIntgrtCRC 12000;
BA_ "SPN" SG_ 2566603518 MtrGnrtr4InvrtrIsltnIntgrtCntr 12001;
BA_ "SPN" SG_ 2566603518 MtGt4IvtDCSdNtvtCsssGdVt 12002;
BA_ "SPN" SG_ 2566603518 MtGt4IvtHVtBsAtvIstTstStts 12003;
BA_ "SPN" SG_ 2566603518 MtGt4IvtHVtBsPssvIstTstStts 12004;
BA_ "SPN" SG_ 2566603518 MtGt4IvtHVtBsAtvIstTstRsts 12005;
BA_ "SPN" SG_ 2566603518 MtGt4IvtHVtBsPssvIstTstRsts 12006;
BA_ "SPN" SG_ 2566603774 MtGt4IvtPwLtddtUddRs 12007;
BA_ "SPN" SG_ 2566603774 MtGt4IvtPwLtddtDCSdCtMx 12008;
BA_ "SPN" SG_ 2566603774 MtGt4IvtPwLtddtDCSdCtM 12009;
BA_ "SPN" SG_ 2566603774 MtGt4IvtPwLtddtDCSdVtMx 12010;
BA_ "SPN" SG_ 2566603774 MtGt4IvtPwLtddtDCSdVtM 12011;
BA_ "SPN" SG_ 2566603774 MtGt4IvtPwLtddtMPwMx 12012;
BA_ "SPN" SG_ 2566603774 MtGt4IvtPwLtddtMPwM 12013;
BA_ "SPN" SG_ 2566603774 MtGt4IvtPwLtddtDCSdPwMx 12014;
BA_ "SPN" SG_ 2566603774 MtGt4IvtPwLtddtDCSdPwM 12015;
BA_ "SPN" SG_ 2566603774 MtrGnrtr4InvrtrPwrLmtddtTrqMxmm 12016;
BA_ "SPN" SG_ 2566603774 MtrGnrtr4InvrtrPwrLmtddtTrqMnmm 12017;
BA_ "SPN" SG_ 2566603774 MtrGnrtr4InvrtrPwrLmtddtSpdMxmm 12018;
BA_ "SPN" SG_ 2566603774 MtrGnrtr4InvrtrPwrLmtddtSpdMnmm 12019;
BA_ "SPN" SG_ 2566603774 MtGt4IvtPwLtddtIvtTpt 12020;
BA_ "SPN" SG_ 2566603774 MtGt4IvtPwLtddtMtTpt 12021;
BA_ "SPN" SG_ 2566603774 MtGt4IvtPwLtdDtFtCdt 13053;
BA_ "SPN" SG_ 2566603774 MtGt4IvtPwLtdDtAtvTqRtLt 13054;
BA_ "SPN" SG_ 2566603774 MtGt4IvtPwLtdDtAtvSpdRtLt 13055;
BA_ "SPN" SG_ 2566603774 MtGt4IvtTqLtdDtMCtsts 13056;
BA_ "SPN" SG_ 2365277438 MtrGnrtr3InvrtrRfrn1CRC 11819;
BA_ "SPN" SG_ 2365277438 MtrGnrtr3InvrtrRfrn1Cntr 11820;
BA_ "SPN" SG_ 2365277438 MtrGnrtr3InvrtrRfrnTrq 11821;
BA_ "SPN" SG_ 2365277438 MtrGnrtr3InvrtrRfrnSpd 11822;
BA_ "SPN" SG_ 2365277438 MtrGnrtr3InvrtrRfrnPwr 11823;
BA_ "SPN" SG_ 2365277694 MtrGnrtr3InvrtrStts1CRC 11824;
BA_ "SPN" SG_ 2365277694 MtrGnrtr3InvrtrStts1Cntr 11825;
BA_ "SPN" SG_ 2365277694 MotorGenerator3Torque 11803;
BA_ "SPN" SG_ 2365277694 MotorGenerator3Speed 11801;
BA_ "SPN" SG_ 2365277694 MtrGnrtr3InvrtrDCSdCrrnt 11826;
BA_ "SPN" SG_ 2365277694 MtrGnrtr3InvrtrDCSdVltg 11804;
BA_ "SPN" SG_ 2365277950 MtrGnrtr3InvrtrRfrn2CRC 11851;
BA_ "SPN" SG_ 2365277950 MtrGnrtr3InvrtrRfrn2Cntr 11852;
BA_ "SPN" SG_ 2365277950 MtrGnrtr3InvrtrRfrnCrrnt 11853;
BA_ "SPN" SG_ 2365277950 MtrGnrtr3InvrtrRfrnVltg 11854;
BA_ "SPN" SG_ 2566604798 MtrGnrtr3InvrtrTmprtr1 11867;
BA_ "SPN" SG_ 2566604798 MtrGnrtr3InvrtrTmprtr2 11868;
BA_ "SPN" SG_ 2566604798 MtrGnrtr3InvrtrTmprtr3 11869;
BA_ "SPN" SG_ 2566604798 MtrGnrtr3InvrtrTmprtr4 11870;
BA_ "SPN" SG_ 2566605054 MotorGenerator3Temperature1 11802;
BA_ "SPN" SG_ 2566605054 MotorGenerator3Temperature2 11871;
BA_ "SPN" SG_ 2566605054 MotorGenerator3Temperature3 11872;
BA_ "SPN" SG_ 2566605054 MotorGenerator3Temperature4 11873;
BA_ "SPN" SG_ 2566605310 MtrGnrtr3InvrtrIsltnIntgrtCRC 11882;
BA_ "SPN" SG_ 2566605310 MtrGnrtr3InvrtrIsltnIntgrtCntr 11883;
BA_ "SPN" SG_ 2566605310 MtGt3IvtDCSdNtvtCsssGdVt 11884;
BA_ "SPN" SG_ 2566605310 MtGt3IvtHVtBsAtvIstTstStts 11885;
BA_ "SPN" SG_ 2566605310 MtGt3IvtHVtBsPssvIstTstStts 11886;
BA_ "SPN" SG_ 2566605310 MtGt3IvtHVtBsAtvIstTstRsts 11887;
BA_ "SPN" SG_ 2566605310 MtGt3IvtHVtBsPssvIstTstRsts 11888;
BA_ "SPN" SG_ 2566605566 MtGt3IvtPwLtddtUddRs 11889;
BA_ "SPN" SG_ 2566605566 MtGt3IvtPwLtddtDCSdCtMx 11890;
BA_ "SPN" SG_ 2566605566 MtGt3IvtPwLtddtDCSdCtM 11891;
BA_ "SPN" SG_ 2566605566 MtGt3IvtPwLtddtDCSdVtMx 11892;
BA_ "SPN" SG_ 2566605566 MtGt3IvtPwLtddtDCSdVtM 11893;
BA_ "SPN" SG_ 2566605566 MtGt3IvtPwLtddtMPwMx 11894;
BA_ "SPN" SG_ 2566605566 MtGt3IvtPwLtddtMPwM 11895;
BA_ "SPN" SG_ 2566605566 MtGt3IvtPwLtddtDCSdPwMx 11896;
BA_ "SPN" SG_ 2566605566 MtGt3IvtPwLtddtDCSdPwM 11897;
BA_ "SPN" SG_ 2566605566 MtrGnrtr3InvrtrPwrLmtddtTrqMxmm 11898;
BA_ "SPN" SG_ 2566605566 MtrGnrtr3InvrtrPwrLmtddtTrqMnmm 11899;
BA_ "SPN" SG_ 2566605566 MtrGnrtr3InvrtrPwrLmtddtSpdMxmm 11900;
BA_ "SPN" SG_ 2566605566 MtrGnrtr3InvrtrPwrLmtddtSpdMnmm 11901;
BA_ "SPN" SG_ 2566605566 MtGt3IvtPwLtddtIvtTpt 11902;
BA_ "SPN" SG_ 2566605566 MtGt3IvtPwLtddtMtTpt 11903;
BA_ "SPN" SG_ 2566605566 MtGt3IvtPwLtdDtFtCdt 13049;
BA_ "SPN" SG_ 2566605566 MtGt3IvtPwLtdDtAtvTqRtLt 13050;
BA_ "SPN" SG_ 2566605566 MtGt3IvtPwLtdDtAtvSpdRtLt 13051;
BA_ "SPN" SG_ 2566605566 MtGt3IvtTqLtdDtMCtsts 13052;
BA_ "SPN" SG_ 2566605822 SAddssCtDvTSC1CtPpsP7 11756;
BA_ "SPN" SG_ 2566605822 TSC1CntrlPrpsP7RdnssStts 11757;
BA_ "SPN" SG_ 2566606078 CabHeaterPower 11755;
BA_ "SPN" SG_ 2566606334 EngineAirFilter1LifeRemaining 11737;
BA_ "SPN" SG_ 2566606334 EngineAirFilter2LifeRemaining 11738;
BA_ "SPN" SG_ 2566606334 EngineAirFilter3LifeRemaining 11739;
BA_ "SPN" SG_ 2566606334 EngineAirFilter4LifeRemaining 11740;
BA_ "SPN" SG_ 2566606334 EngineFuelFilterLifeRemaining 11741;
BA_ "SPN" SG_ 2566606334 EngnFlFltrStnSdLfRmnng 11742;
BA_ "SPN" SG_ 2566606334 EngineOilFilterLifeRemaining 11743;
BA_ "SPN" SG_ 2566606334 TrnsmssnOIlFltrLfRmnng 11744;
BA_ "SPN" SG_ 2499497726 HoistLeverPosition 11727;
BA_ "SPN" SG_ 2499497726 HoistLeverDetentPositionStatus 11728;
BA_ "SPN" SG_ 2633715710 HVESP6StateofHealth 11721;
BA_ "SPN" SG_ 2633715710 HVESP6CnttrOpnUndrLdCnt 11722;
BA_ "SPN" SG_ 2633715710 HVESP6TotalEnergyThroughput 11723;
BA_ "SPN" SG_ 2633715710 HVESP6TotalAccumulatedCharge 11724;
BA_ "SPN" SG_ 2633715710 HVESP6TotalLifetimeEnergyInput 13377;
BA_ "SPN" SG_ 2633715710 HVESP6TotalLifetimeEnergyOutput 13378;
BA_ "SPN" SG_ 2566607102 HVESP6NominalVoltage 11712;
BA_ "SPN" SG_ 2566607102 HVESP6RmmnddMnmmOprtngVltg 11713;
BA_ "SPN" SG_ 2566607102 HVESP6RmmnddMxmmOprtngVltg 11714;
BA_ "SPN" SG_ 2566607102 HVESP6RmmnddMnmmSttOfChrg 11715;
BA_ "SPN" SG_ 2566607102 HVESP6RmmnddMxmmSttOfChrg 11716;
BA_ "SPN" SG_ 2566607102 HVESP6RmmnddMxmmOprtngTmprtr 11717;
BA_ "SPN" SG_ 2566607102 HVESP6RmmnddMnmmOprtngTmprtr 11718;
BA_ "SPN" SG_ 2566607102 HVESP6CellMaximumVoltageLimit 11719;
BA_ "SPN" SG_ 2566607102 HVESP6CellMinimumVoltageLimit 11720;
BA_ "SPN" SG_ 2633716222 HVESP5StateofHealth 11605;
BA_ "SPN" SG_ 2633716222 HVESP5CnttrOpnUndrLdCnt 11606;
BA_ "SPN" SG_ 2633716222 HVESP5TotalEnergyThroughput 11607;
BA_ "SPN" SG_ 2633716222 HVESP5TotalAccumulatedCharge 11608;
BA_ "SPN" SG_ 2633716222 HVESP5TotalLifetimeEnergyInput 13375;
BA_ "SPN" SG_ 2633716222 HVESP5TotalLifetimeEnergyOutput 13376;
BA_ "SPN" SG_ 2566607614 HVESP5NominalVoltage 11596;
BA_ "SPN" SG_ 2566607614 HVESP5RmmnddMnmmOprtngVltg 11597;
BA_ "SPN" SG_ 2566607614 HVESP5RmmnddMxmmOprtngVltg 11598;
BA_ "SPN" SG_ 2566607614 HVESP5RmmnddMnmmSttOfChrg 11599;
BA_ "SPN" SG_ 2566607614 HVESP5RmmnddMxmmSttOfChrg 11600;
BA_ "SPN" SG_ 2566607614 HVESP5RmmnddMxmmOprtngTmprtr 11601;
BA_ "SPN" SG_ 2566607614 HVESP5RmmnddMnmmOprtngTmprtr 11602;
BA_ "SPN" SG_ 2566607614 HVESP5CellMaximumVoltageLimit 11603;
BA_ "SPN" SG_ 2566607614 HVESP5CellMinimumVoltageLimit 11604;
BA_ "SPN" SG_ 2633716734 HVESP4StateofHealth 11489;
BA_ "SPN" SG_ 2633716734 HVESP4CnttrOpnUndrLdCnt 11490;
BA_ "SPN" SG_ 2633716734 HVESP4TotalEnergyThroughput 11491;
BA_ "SPN" SG_ 2633716734 HVESP4TotalAccumulatedCharge 11492;
BA_ "SPN" SG_ 2633716734 HVESP4TotalLifetimeEnergyInput 13373;
BA_ "SPN" SG_ 2633716734 HVESP4TotalLifetimeEnergyOutput 13374;
BA_ "SPN" SG_ 2566608126 HVESP4NominalVoltage 11480;
BA_ "SPN" SG_ 2566608126 HVESP4RmmnddMnmmOprtngVltg 11481;
BA_ "SPN" SG_ 2566608126 HVESP4RmmnddMxmmOprtngVltg 11482;
BA_ "SPN" SG_ 2566608126 HVESP4RmmnddMnmmSttOfChrg 11483;
BA_ "SPN" SG_ 2566608126 HVESP4RmmnddMxmmSttOfChrg 11484;
BA_ "SPN" SG_ 2566608126 HVESP4RmmnddMxmmOprtngTmprtr 11485;
BA_ "SPN" SG_ 2566608126 HVESP4RmmnddMnmmOprtngTmprtr 11486;
BA_ "SPN" SG_ 2566608126 HVESP4CellMaximumVoltageLimit 11487;
BA_ "SPN" SG_ 2566608126 HVESP4CellMinimumVoltageLimit 11488;
BA_ "SPN" SG_ 2633717246 HVESP3StateofHealth 11373;
BA_ "SPN" SG_ 2633717246 HVESP3CnttrOpnUndrLdCnt 11374;
BA_ "SPN" SG_ 2633717246 HVESP3TotalEnergyThroughput 11375;
BA_ "SPN" SG_ 2633717246 HVESP3TotalAccumulatedCharge 11376;
BA_ "SPN" SG_ 2633717246 HVESP3TotalLifetimeEnergyInput 13371;
BA_ "SPN" SG_ 2633717246 HVESP3TotalLifetimeEnergyOutput 13372;
BA_ "SPN" SG_ 2566608638 HVESP3NominalVoltage 11364;
BA_ "SPN" SG_ 2566608638 HVESP3RmmnddMnmmOprtngVltg 11365;
BA_ "SPN" SG_ 2566608638 HVESP3RmmnddMxmmOprtngVltg 11366;
BA_ "SPN" SG_ 2566608638 HVESP3RmmnddMnmmSttOfChrg 11367;
BA_ "SPN" SG_ 2566608638 HVESP3RmmnddMxmmSttOfChrg 11368;
BA_ "SPN" SG_ 2566608638 HVESP3RmmnddMxmmOprtngTmprtr 11369;
BA_ "SPN" SG_ 2566608638 HVESP3RmmnddMnmmOprtngTmprtr 11370;
BA_ "SPN" SG_ 2566608638 HVESP3CellMaximumVoltageLimit 11371;
BA_ "SPN" SG_ 2566608638 HVESP3CellMinimumVoltageLimit 11372;
BA_ "SPN" SG_ 2633717758 HVESP2StateofHealth 11257;
BA_ "SPN" SG_ 2633717758 HVESP2CnttrOpnUndrLdCnt 11258;
BA_ "SPN" SG_ 2633717758 HVESP2TotalEnergyThroughput 11259;
BA_ "SPN" SG_ 2633717758 HVESP2TotalAccumulatedCharge 11260;
BA_ "SPN" SG_ 2633717758 HVESP2TotalLifetimeEnergyInput 13369;
BA_ "SPN" SG_ 2633717758 HVESP2TotalLifetimeEnergyOutput 13370;
BA_ "SPN" SG_ 2566609150 HVESP2NominalVoltage 11248;
BA_ "SPN" SG_ 2566609150 HVESP2RmmnddMnmmOprtngVltg 11249;
BA_ "SPN" SG_ 2566609150 HVESP2RmmnddMxmmOprtngVltg 11250;
BA_ "SPN" SG_ 2566609150 HVESP2RmmnddMnmmSttOfChrg 11251;
BA_ "SPN" SG_ 2566609150 HVESP2RmmnddMxmmSttOfChrg 11252;
BA_ "SPN" SG_ 2566609150 HVESP2RmmnddMxmmOprtngTmprtr 11253;
BA_ "SPN" SG_ 2566609150 HVESP2RmmnddMnmmOprtngTmprtr 11254;
BA_ "SPN" SG_ 2566609150 HVESP2CellMaximumVoltageLimit 11255;
BA_ "SPN" SG_ 2566609150 HVESP2CellMinimumVoltageLimit 11256;
BA_ "SPN" SG_ 2633718270 HVESP1StateofHealth 11141;
BA_ "SPN" SG_ 2633718270 HVESP1CnttrOpnUndrLdCnt 11142;
BA_ "SPN" SG_ 2633718270 HVESP1TotalEnergyThroughput 11143;
BA_ "SPN" SG_ 2633718270 HVESP1TotalAccumulatedCharge 11144;
BA_ "SPN" SG_ 2633718270 HVESP1TotalLifetimeEnergyInput 13367;
BA_ "SPN" SG_ 2633718270 HVESP1TotalLifetimeEnergyOutput 13368;
BA_ "SPN" SG_ 2566609662 HVESP1NominalVoltage 11132;
BA_ "SPN" SG_ 2566609662 HVESP1RmmnddMnmmOprtngVltg 11133;
BA_ "SPN" SG_ 2566609662 HVESP1RmmnddMxmmOprtngVltg 11134;
BA_ "SPN" SG_ 2566609662 HVESP1RmmnddMnmmSttOfChrg 11135;
BA_ "SPN" SG_ 2566609662 HVESP1RmmnddMxmmSttOfChrg 11136;
BA_ "SPN" SG_ 2566609662 HVESP1RmmnddMxmmOprtngTmprtr 11137;
BA_ "SPN" SG_ 2566609662 HVESP1RmmnddMnmmOprtngTmprtr 11138;
BA_ "SPN" SG_ 2566609662 HVESP1CellMaximumVoltageLimit 11139;
BA_ "SPN" SG_ 2566609662 HVESP1CellMinimumVoltageLimit 11140;
BA_ "SPN" SG_ 2633718782 VFSSMdl1Dttr1DttrTp 10845;
BA_ "SPN" SG_ 2633718782 VFSSMdl1Dttr1DttrDtSLOT 10846;
BA_ "SPN" SG_ 2633718782 VFSSMdl1Dttr2DttrTp 10848;
BA_ "SPN" SG_ 2633718782 VFSSMdl1Dttr2DttrDtSLOT 10849;
BA_ "SPN" SG_ 2633718782 VFSSMdl1Dttr3DttrTp 10851;
BA_ "SPN" SG_ 2633718782 VFSSMdl1Dttr3DttrDtSLOT 10852;
BA_ "SPN" SG_ 2633718782 VFSSMdl1Dttr4DttrTp 10854;
BA_ "SPN" SG_ 2633718782 VFSSMdl1Dttr4DttrDtSLOT 10855;
BA_ "SPN" SG_ 2633718782 VFSSMdl1Dttr5DttrTp 10857;
BA_ "SPN" SG_ 2633718782 VFSSMdl1Dttr5DttrDtSLOT 10858;
BA_ "SPN" SG_ 2633718782 VFSSMdl1Dttr6DttrTp 10860;
BA_ "SPN" SG_ 2633718782 VFSSMdl1Dttr6DttrDtSLOT 10861;
BA_ "SPN" SG_ 2633718782 VFSSMdl1Dttr7DttrTp 10863;
BA_ "SPN" SG_ 2633718782 VFSSMdl1Dttr7DttrDtSLOT 10864;
BA_ "SPN" SG_ 2633718782 VFSSMdl1Dttr8DttrTp 10866;
BA_ "SPN" SG_ 2633718782 VFSSMdl1Dttr8DttrDtSLOT 10867;
BA_ "SPN" SG_ 2633719038 VFSSMdl2Dttr1DttrTp 10869;
BA_ "SPN" SG_ 2633719038 VFSSMdl2Dttr1DttrDtSLOT 10870;
BA_ "SPN" SG_ 2633719038 VFSSMdl2Dttr2DttrTp 10872;
BA_ "SPN" SG_ 2633719038 VFSSMdl2Dttr2DttrDtSLOT 10873;
BA_ "SPN" SG_ 2633719038 VFSSMdl2Dttr3DttrTp 10875;
BA_ "SPN" SG_ 2633719038 VFSSMdl2Dttr3DttrDtSLOT 10876;
BA_ "SPN" SG_ 2633719038 VFSSMdl2Dttr4DttrTp 10878;
BA_ "SPN" SG_ 2633719038 VFSSMdl2Dttr4DttrDtSLOT 10879;
BA_ "SPN" SG_ 2633719038 VFSSMdl2Dttr5DttrTp 10881;
BA_ "SPN" SG_ 2633719038 VFSSMdl2Dttr5DttrDtSLOT 10882;
BA_ "SPN" SG_ 2633719038 VFSSMdl2Dttr6DttrTp 10884;
BA_ "SPN" SG_ 2633719038 VFSSMdl2Dttr6DttrDtSLOT 10885;
BA_ "SPN" SG_ 2633719038 VFSSMdl2Dttr7DttrTp 10887;
BA_ "SPN" SG_ 2633719038 VFSSMdl2Dttr7DttrDtSLOT 10888;
BA_ "SPN" SG_ 2633719038 VFSSMdl2Dttr8DttrTp 10890;
BA_ "SPN" SG_ 2633719038 VFSSMdl2Dttr8DttrDtSLOT 10891;
